VERSION "canboat-NMEA2000-curated"

NS_ :

BS_:

BU_: Vector__XXX
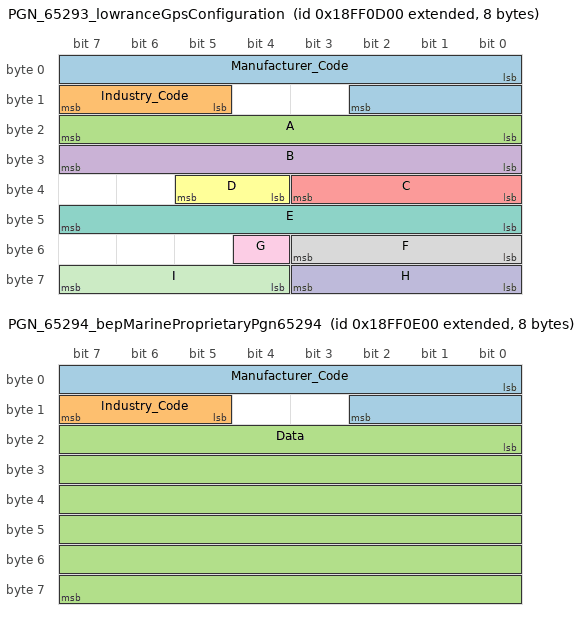
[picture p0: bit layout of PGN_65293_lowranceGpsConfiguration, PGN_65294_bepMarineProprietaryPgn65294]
BO_ 2566851840 PGN_65293_lowranceGpsConfiguration: 8 Vector__XXX
 SG_ Manufacturer_Code : 0|11@1+ (1.0,0) [0|2047] "" Vector__XXX
 SG_ Industry_Code : 13|3@1+ (1.0,0) [0|7] "" Vector__XXX
 SG_ A : 16|8@1+ (1.0,0) [0|255] "" Vector__XXX
 SG_ B : 24|8@1+ (1.0,0) [0|255] "" Vector__XXX
 SG_ C : 32|4@1+ (1.0,0) [0|15] "" Vector__XXX
 SG_ D : 36|2@1+ (1.0,0) [0|3] "" Vector__XXX
 SG_ E : 40|8@1+ (1.0,0) [0|255] "" Vector__XXX
 SG_ F : 48|4@1+ (1.0,0) [0|15] "" Vector__XXX
 SG_ G : 52|1@1+ (1.0,0) [0|1] "" Vector__XXX
 SG_ H : 56|4@1+ (1.0,0) [0|15] "" Vector__XXX
 SG_ I : 60|4@1+ (1.0,0) [0|15] "" Vector__XXX

BO_ 2566851840 PGN_65293_simnetLgc2000Configuration: 8 Vector__XXX
 SG_ Manufacturer_Code : 0|11@1+ (1.0,0) [0|2047] "" Vector__XXX
 SG_ Industry_Code : 13|3@1+ (1.0,0) [0|7] "" Vector__XXX

BO_ 2566852096 PGN_65294_bepMarineProprietaryPgn65294: 8 Vector__XXX
 SG_ Manufacturer_Code : 0|11@1+ (1.0,0) [0|2047] "" Vector__XXX
 SG_ Industry_Code : 13|3@1+ (1.0,0) [0|7] "" Vector__XXX
 SG_ Data : 16|48@1+ (1.0,0) [0|281474976710655] "" Vector__XXX

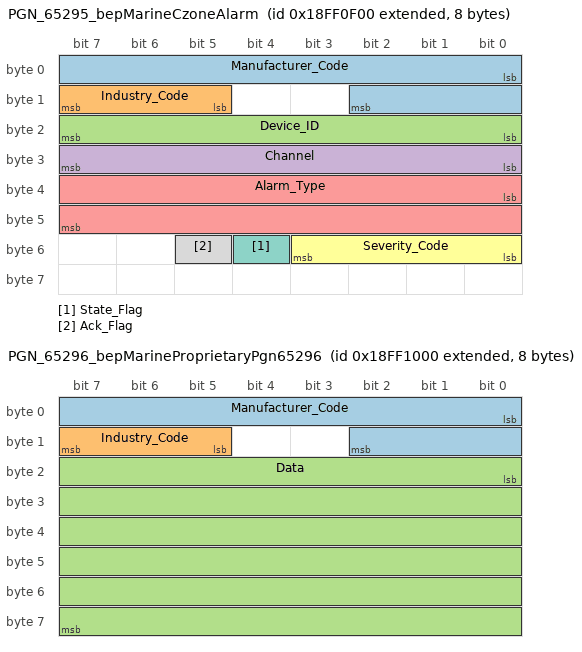
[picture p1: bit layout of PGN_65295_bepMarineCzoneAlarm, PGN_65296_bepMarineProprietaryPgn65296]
BO_ 2566852352 PGN_65295_bepMarineCzoneAlarm: 8 Vector__XXX
 SG_ Manufacturer_Code : 0|11@1+ (1.0,0) [0|2047] "" Vector__XXX
 SG_ Industry_Code : 13|3@1+ (1.0,0) [0|7] "" Vector__XXX
 SG_ Device_ID : 16|8@1+ (1.0,0) [0|255] "" Vector__XXX
 SG_ Channel : 24|8@1+ (1.0,0) [0|255] "" Vector__XXX
 SG_ Alarm_Type : 32|16@1+ (1.0,0) [0|65535] "" Vector__XXX
 SG_ Severity_Code : 48|4@1+ (1.0,0) [0|15] "" Vector__XXX
 SG_ State_Flag : 52|1@1+ (1.0,0) [0|1] "" Vector__XXX
 SG_ Ack_Flag : 53|1@1+ (1.0,0) [0|1] "" Vector__XXX

BO_ 2566852608 PGN_65296_bepMarineProprietaryPgn65296: 8 Vector__XXX
 SG_ Manufacturer_Code : 0|11@1+ (1.0,0) [0|2047] "" Vector__XXX
 SG_ Industry_Code : 13|3@1+ (1.0,0) [0|7] "" Vector__XXX
 SG_ Data : 16|48@1+ (1.0,0) [0|281474976710655] "" Vector__XXX

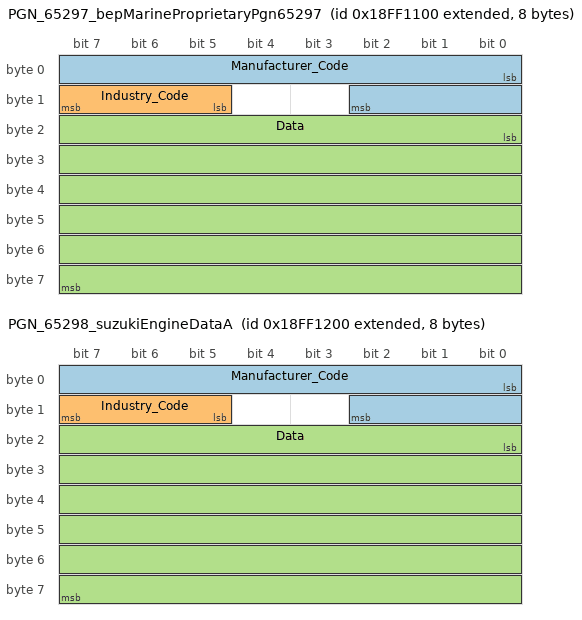
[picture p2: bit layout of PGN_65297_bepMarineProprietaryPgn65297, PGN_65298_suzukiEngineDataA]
BO_ 2566852864 PGN_65297_bepMarineProprietaryPgn65297: 8 Vector__XXX
 SG_ Manufacturer_Code : 0|11@1+ (1.0,0) [0|2047] "" Vector__XXX
 SG_ Industry_Code : 13|3@1+ (1.0,0) [0|7] "" Vector__XXX
 SG_ Data : 16|48@1+ (1.0,0) [0|281474976710655] "" Vector__XXX

BO_ 2566853120 PGN_65298_suzukiEngineDataA: 8 Vector__XXX
 SG_ Manufacturer_Code : 0|11@1+ (1.0,0) [0|2047] "" Vector__XXX
 SG_ Industry_Code : 13|3@1+ (1.0,0) [0|7] "" Vector__XXX
 SG_ Data : 16|48@1+ (1.0,0) [0|281474976710655] "" Vector__XXX

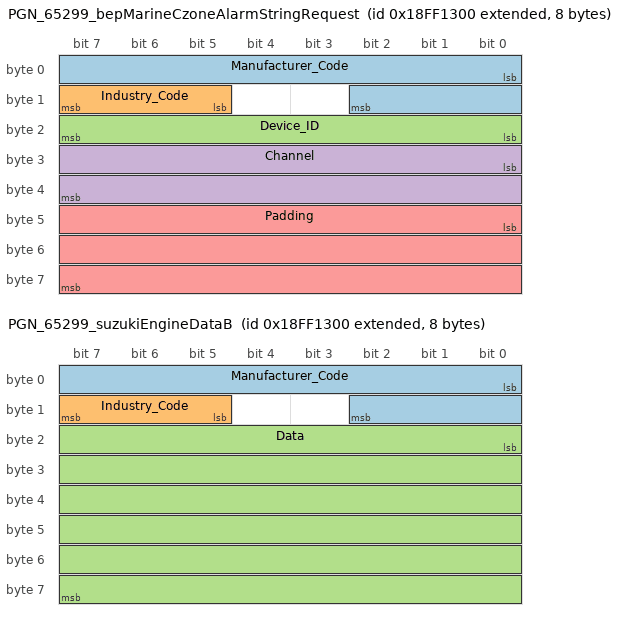
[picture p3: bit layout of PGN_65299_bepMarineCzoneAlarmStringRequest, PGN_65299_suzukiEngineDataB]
BO_ 2566853376 PGN_65299_bepMarineCzoneAlarmStringRequest: 8 Vector__XXX
 SG_ Manufacturer_Code : 0|11@1+ (1.0,0) [0|2047] "" Vector__XXX
 SG_ Industry_Code : 13|3@1+ (1.0,0) [0|7] "" Vector__XXX
 SG_ Device_ID : 16|8@1+ (1.0,0) [0|255] "" Vector__XXX
 SG_ Channel : 24|16@1+ (1.0,0) [0|65535] "" Vector__XXX
 SG_ Padding : 40|24@1+ (1.0,0) [0|16777215] "" Vector__XXX

BO_ 2566853376 PGN_65299_suzukiEngineDataB: 8 Vector__XXX
 SG_ Manufacturer_Code : 0|11@1+ (1.0,0) [0|2047] "" Vector__XXX
 SG_ Industry_Code : 13|3@1+ (1.0,0) [0|7] "" Vector__XXX
 SG_ Data : 16|48@1+ (1.0,0) [0|281474976710655] "" Vector__XXX

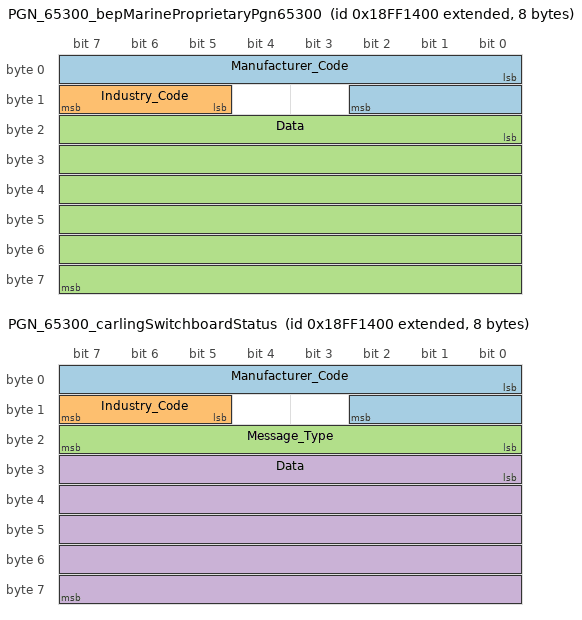
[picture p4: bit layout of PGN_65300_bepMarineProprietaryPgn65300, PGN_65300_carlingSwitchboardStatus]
BO_ 2566853632 PGN_65300_bepMarineProprietaryPgn65300: 8 Vector__XXX
 SG_ Manufacturer_Code : 0|11@1+ (1.0,0) [0|2047] "" Vector__XXX
 SG_ Industry_Code : 13|3@1+ (1.0,0) [0|7] "" Vector__XXX
 SG_ Data : 16|48@1+ (1.0,0) [0|281474976710655] "" Vector__XXX

BO_ 2566853632 PGN_65300_carlingSwitchboardStatus: 8 Vector__XXX
 SG_ Manufacturer_Code : 0|11@1+ (1.0,0) [0|2047] "" Vector__XXX
 SG_ Industry_Code : 13|3@1+ (1.0,0) [0|7] "" Vector__XXX
 SG_ Message_Type : 16|8@1+ (1.0,0) [0|255] "" Vector__XXX
 SG_ Data : 24|40@1+ (1.0,0) [0|1099511627775] "" Vector__XXX

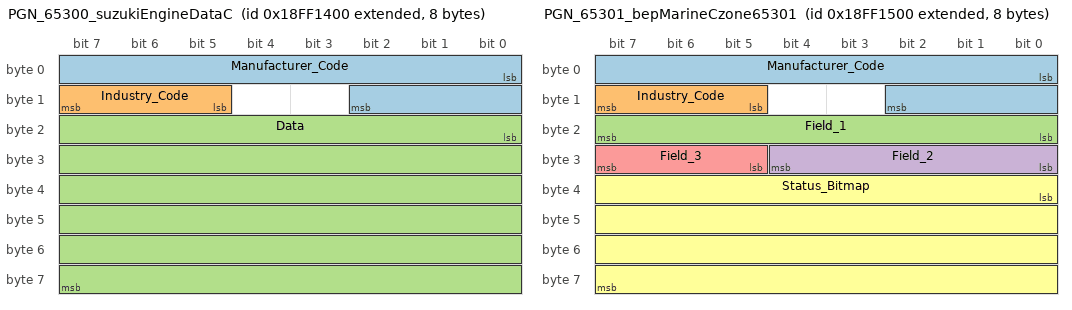
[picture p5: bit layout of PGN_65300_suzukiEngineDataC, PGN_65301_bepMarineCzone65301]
BO_ 2566853632 PGN_65300_suzukiEngineDataC: 8 Vector__XXX
 SG_ Manufacturer_Code : 0|11@1+ (1.0,0) [0|2047] "" Vector__XXX
 SG_ Industry_Code : 13|3@1+ (1.0,0) [0|7] "" Vector__XXX
 SG_ Data : 16|48@1+ (1.0,0) [0|281474976710655] "" Vector__XXX

BO_ 2566853888 PGN_65301_bepMarineCzone65301: 8 Vector__XXX
 SG_ Manufacturer_Code : 0|11@1+ (1.0,0) [0|2047] "" Vector__XXX
 SG_ Industry_Code : 13|3@1+ (1.0,0) [0|7] "" Vector__XXX
 SG_ Field_1 : 16|8@1+ (1.0,0) [0|255] "" Vector__XXX
 SG_ Field_2 : 24|5@1+ (1.0,0) [0|31] "" Vector__XXX
 SG_ Field_3 : 29|3@1+ (1.0,0) [0|7] "" Vector__XXX
 SG_ Status_Bitmap : 32|32@1+ (1.0,0) [0|4294967295] "" Vector__XXX

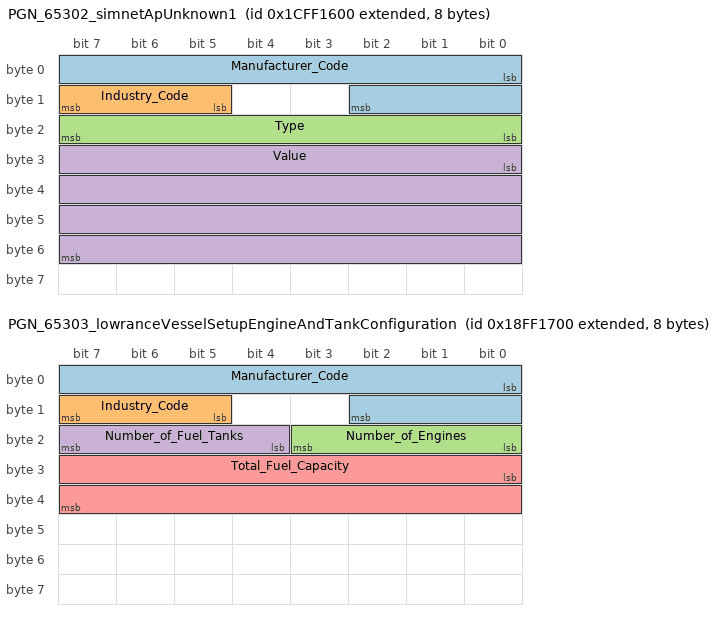
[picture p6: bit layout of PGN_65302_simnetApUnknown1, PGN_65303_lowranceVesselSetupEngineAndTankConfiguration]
BO_ 2633963008 PGN_65302_simnetApUnknown1: 8 Vector__XXX
 SG_ Manufacturer_Code : 0|11@1+ (1.0,0) [0|2047] "" Vector__XXX
 SG_ Industry_Code : 13|3@1+ (1.0,0) [0|7] "" Vector__XXX
 SG_ Type : 16|8@1+ (1.0,0) [0|255] "" Vector__XXX
 SG_ Value : 24|32@1+ (1.0,0) [0|4294967295] "" Vector__XXX

BO_ 2566854400 PGN_65303_lowranceVesselSetupEngineAndTankConfiguration: 8 Vector__XXX
 SG_ Manufacturer_Code : 0|11@1+ (1.0,0) [0|2047] "" Vector__XXX
 SG_ Industry_Code : 13|3@1+ (1.0,0) [0|7] "" Vector__XXX
 SG_ Number_of_Engines : 16|4@1+ (1.0,0) [0|15] "" Vector__XXX
 SG_ Number_of_Fuel_Tanks : 20|4@1+ (1.0,0) [0|15] "" Vector__XXX
 SG_ Total_Fuel_Capacity : 24|16@1+ (0.1,0) [0.0|6553.5] "" Vector__XXX

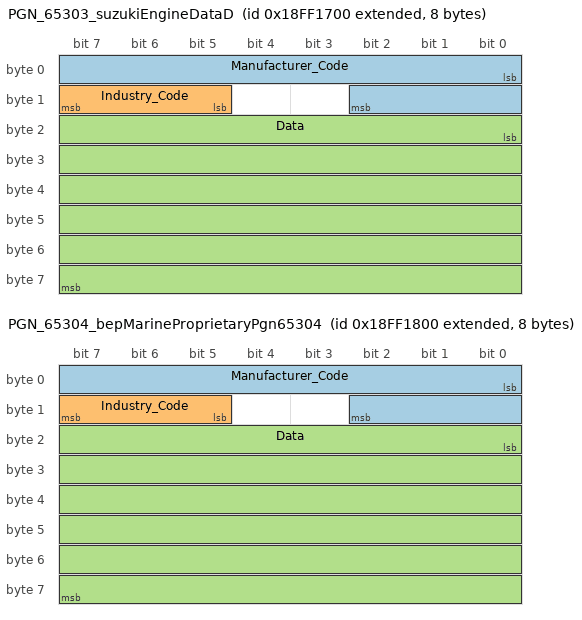
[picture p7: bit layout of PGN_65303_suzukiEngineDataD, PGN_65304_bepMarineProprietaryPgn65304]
BO_ 2566854400 PGN_65303_suzukiEngineDataD: 8 Vector__XXX
 SG_ Manufacturer_Code : 0|11@1+ (1.0,0) [0|2047] "" Vector__XXX
 SG_ Industry_Code : 13|3@1+ (1.0,0) [0|7] "" Vector__XXX
 SG_ Data : 16|48@1+ (1.0,0) [0|281474976710655] "" Vector__XXX

BO_ 2566854656 PGN_65304_bepMarineProprietaryPgn65304: 8 Vector__XXX
 SG_ Manufacturer_Code : 0|11@1+ (1.0,0) [0|2047] "" Vector__XXX
 SG_ Industry_Code : 13|3@1+ (1.0,0) [0|7] "" Vector__XXX
 SG_ Data : 16|48@1+ (1.0,0) [0|281474976710655] "" Vector__XXX

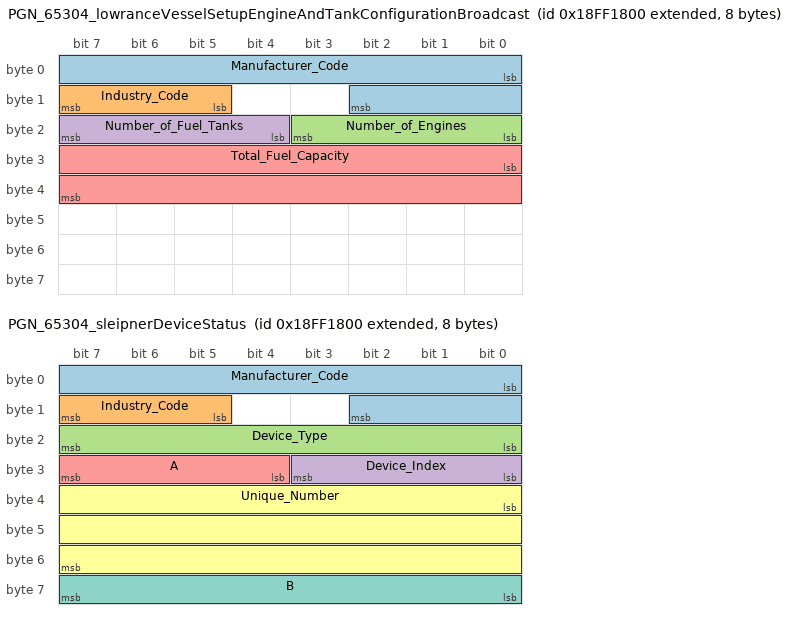
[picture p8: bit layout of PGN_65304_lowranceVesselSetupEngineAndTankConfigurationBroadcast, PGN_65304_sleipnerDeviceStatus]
BO_ 2566854656 PGN_65304_lowranceVesselSetupEngineAndTankConfigurationBroadcast: 8 Vector__XXX
 SG_ Manufacturer_Code : 0|11@1+ (1.0,0) [0|2047] "" Vector__XXX
 SG_ Industry_Code : 13|3@1+ (1.0,0) [0|7] "" Vector__XXX
 SG_ Number_of_Engines : 16|4@1+ (1.0,0) [0|15] "" Vector__XXX
 SG_ Number_of_Fuel_Tanks : 20|4@1+ (1.0,0) [0|15] "" Vector__XXX
 SG_ Total_Fuel_Capacity : 24|16@1+ (0.1,0) [0.0|6553.5] "" Vector__XXX

BO_ 2566854656 PGN_65304_sleipnerDeviceStatus: 8 Vector__XXX
 SG_ Manufacturer_Code : 0|11@1+ (1.0,0) [0|2047] "" Vector__XXX
 SG_ Industry_Code : 13|3@1+ (1.0,0) [0|7] "" Vector__XXX
 SG_ Device_Type : 16|8@1+ (1.0,0) [0|255] "" Vector__XXX
 SG_ Device_Index : 24|4@1+ (1.0,0) [0|15] "" Vector__XXX
 SG_ A : 28|4@1+ (1.0,0) [0|15] "" Vector__XXX
 SG_ Unique_Number : 32|24@1+ (1.0,0) [0|16777215] "" Vector__XXX
 SG_ B : 56|8@1+ (1.0,0) [0|255] "" Vector__XXX

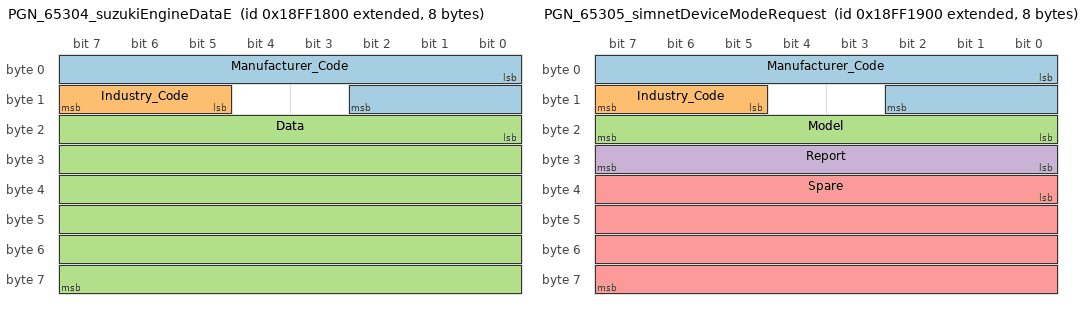
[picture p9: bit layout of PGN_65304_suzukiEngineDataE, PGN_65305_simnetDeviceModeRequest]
BO_ 2566854656 PGN_65304_suzukiEngineDataE: 8 Vector__XXX
 SG_ Manufacturer_Code : 0|11@1+ (1.0,0) [0|2047] "" Vector__XXX
 SG_ Industry_Code : 13|3@1+ (1.0,0) [0|7] "" Vector__XXX
 SG_ Data : 16|48@1+ (1.0,0) [0|281474976710655] "" Vector__XXX

BO_ 2566854912 PGN_65305_simnetDeviceModeRequest: 8 Vector__XXX
 SG_ Manufacturer_Code : 0|11@1+ (1.0,0) [0|2047] "" Vector__XXX
 SG_ Industry_Code : 13|3@1+ (1.0,0) [0|7] "" Vector__XXX
 SG_ Model : 16|8@1+ (1.0,0) [0|255] "" Vector__XXX
 SG_ Report : 24|8@1+ (1.0,0) [0|255] "" Vector__XXX
 SG_ Spare : 32|32@1+ (1.0,0) [0|4294967295] "" Vector__XXX

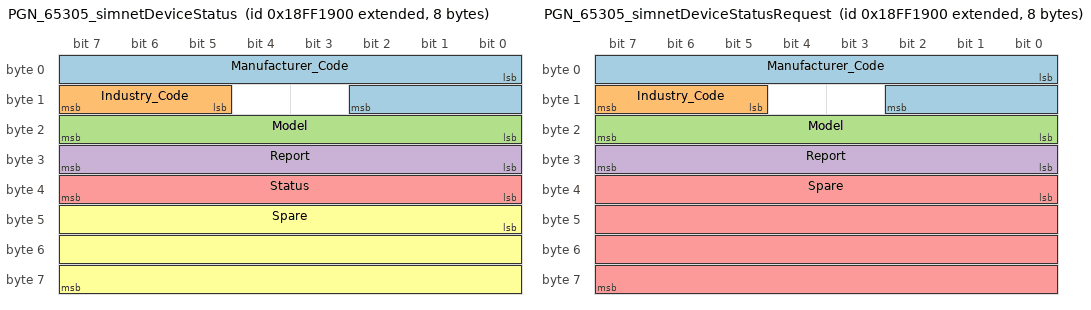
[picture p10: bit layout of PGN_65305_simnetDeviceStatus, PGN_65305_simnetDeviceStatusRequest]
BO_ 2566854912 PGN_65305_simnetDeviceStatus: 8 Vector__XXX
 SG_ Manufacturer_Code : 0|11@1+ (1.0,0) [0|2047] "" Vector__XXX
 SG_ Industry_Code : 13|3@1+ (1.0,0) [0|7] "" Vector__XXX
 SG_ Model : 16|8@1+ (1.0,0) [0|255] "" Vector__XXX
 SG_ Report : 24|8@1+ (1.0,0) [0|255] "" Vector__XXX
 SG_ Status : 32|8@1+ (1.0,0) [0|255] "" Vector__XXX
 SG_ Spare : 40|24@1+ (1.0,0) [0|16777215] "" Vector__XXX

BO_ 2566854912 PGN_65305_simnetDeviceStatusRequest: 8 Vector__XXX
 SG_ Manufacturer_Code : 0|11@1+ (1.0,0) [0|2047] "" Vector__XXX
 SG_ Industry_Code : 13|3@1+ (1.0,0) [0|7] "" Vector__XXX
 SG_ Model : 16|8@1+ (1.0,0) [0|255] "" Vector__XXX
 SG_ Report : 24|8@1+ (1.0,0) [0|255] "" Vector__XXX
 SG_ Spare : 32|32@1+ (1.0,0) [0|4294967295] "" Vector__XXX

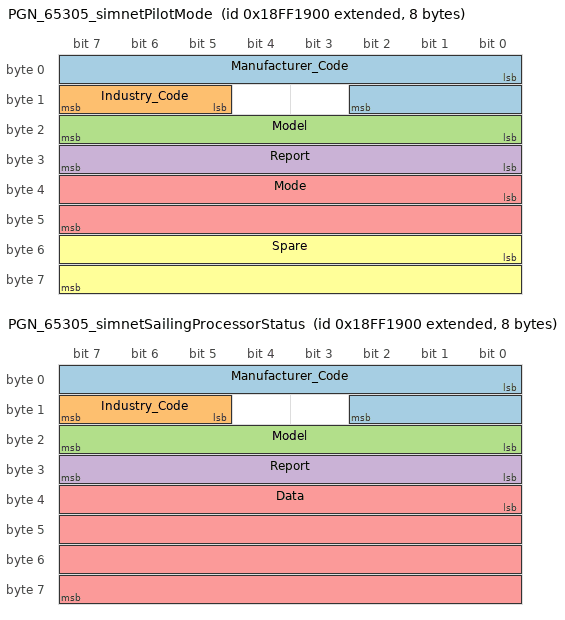
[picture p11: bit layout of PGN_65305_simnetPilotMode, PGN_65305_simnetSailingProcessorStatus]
BO_ 2566854912 PGN_65305_simnetPilotMode: 8 Vector__XXX
 SG_ Manufacturer_Code : 0|11@1+ (1.0,0) [0|2047] "" Vector__XXX
 SG_ Industry_Code : 13|3@1+ (1.0,0) [0|7] "" Vector__XXX
 SG_ Model : 16|8@1+ (1.0,0) [0|255] "" Vector__XXX
 SG_ Report : 24|8@1+ (1.0,0) [0|255] "" Vector__XXX
 SG_ Mode : 32|16@1+ (1.0,0) [0|65535] "" Vector__XXX
 SG_ Spare : 48|16@1+ (1.0,0) [0|65535] "" Vector__XXX

BO_ 2566854912 PGN_65305_simnetSailingProcessorStatus: 8 Vector__XXX
 SG_ Manufacturer_Code : 0|11@1+ (1.0,0) [0|2047] "" Vector__XXX
 SG_ Industry_Code : 13|3@1+ (1.0,0) [0|7] "" Vector__XXX
 SG_ Model : 16|8@1+ (1.0,0) [0|255] "" Vector__XXX
 SG_ Report : 24|8@1+ (1.0,0) [0|255] "" Vector__XXX
 SG_ Data : 32|32@1+ (1.0,0) [0|4294967295] "" Vector__XXX

CM_ BO_ 2566851840 "NMEA2000: PGN 65293 - Lowrance: GPS Configuration (type: Single)";
CM_ BO_ 2566851840 "NMEA2000: PGN 65293 - Simnet: LGC-2000 Configuration (type: Single)";
CM_ BO_ 2566852096 "NMEA2000: PGN 65294 - BEP Marine: Proprietary PGN 65294 (type: Single)";
CM_ BO_ 2566852352 "NMEA2000: PGN 65295 - BEP Marine: CZone Alarm (type: Single)";
CM_ BO_ 2566852608 "NMEA2000: PGN 65296 - BEP Marine: Proprietary PGN 65296 (type: Single)";
CM_ BO_ 2566852864 "NMEA2000: PGN 65297 - BEP Marine: Proprietary PGN 65297 (type: Single)";
CM_ BO_ 2566853120 "NMEA2000: PGN 65298 - Suzuki: Engine Data A (type: Single)";
CM_ BO_ 2566853376 "NMEA2000: PGN 65299 - BEP Marine: CZone Alarm String Request (type: Single)";
CM_ BO_ 2566853376 "NMEA2000: PGN 65299 - Suzuki: Engine Data B (type: Single)";
CM_ BO_ 2566853632 "NMEA2000: PGN 65300 - BEP Marine: Proprietary PGN 65300 (type: Single)";
CM_ BO_ 2566853632 "NMEA2000: PGN 65300 - Carling: Switchboard Status (type: Single)";
CM_ BO_ 2566853632 "NMEA2000: PGN 65300 - Suzuki: Engine Data C (type: Single)";
CM_ BO_ 2566853888 "NMEA2000: PGN 65301 - BEP Marine: CZone 65301 (type: Single)";
CM_ BO_ 2633963008 "NMEA2000: PGN 65302 - Simnet: AP Unknown 1 (type: Single)";
CM_ BO_ 2566854400 "NMEA2000: PGN 65303 - Lowrance: Vessel Setup - Engine and Tank Configuration (type: Single)";
CM_ BO_ 2566854400 "NMEA2000: PGN 65303 - Suzuki: Engine Data D (type: Single)";
CM_ BO_ 2566854656 "NMEA2000: PGN 65304 - BEP Marine: Proprietary PGN 65304 (type: Single)";
CM_ BO_ 2566854656 "NMEA2000: PGN 65304 - Lowrance: Vessel Setup - Engine and Tank Configuration Broadcast (type: Single)";
CM_ BO_ 2566854656 "NMEA2000: PGN 65304 - Sleipner: Device Status (type: Single)";
CM_ BO_ 2566854656 "NMEA2000: PGN 65304 - Suzuki: Engine Data E (type: Single)";
CM_ BO_ 2566854912 "NMEA2000: PGN 65305 - Simnet: Device Mode Request (type: Single)";
CM_ BO_ 2566854912 "NMEA2000: PGN 65305 - Simnet: Device Status (type: Single)";
CM_ BO_ 2566854912 "NMEA2000: PGN 65305 - Simnet: Device Status Request (type: Single)";
CM_ BO_ 2566854912 "NMEA2000: PGN 65305 - Simnet: Pilot Mode (type: Single)";
CM_ BO_ 2566854912 "NMEA2000: PGN 65305 - Simnet: Sailing Processor Status (type: Single)";
CM_ SG_ 2566851840 Manufacturer_Code "Lowrance; canboat type: LOOKUP";
CM_ SG_ 2566851840 Industry_Code "Marine Industry; canboat type: LOOKUP";
CM_ SG_ 2566851840 A "canboat type: UINT8";
CM_ SG_ 2566851840 B "canboat type: UINT8";
CM_ SG_ 2566851840 C "canboat type: UNSIGNED_INTEGER";
CM_ SG_ 2566851840 D "canboat type: UNSIGNED_INTEGER";
CM_ SG_ 2566851840 E "canboat type: UINT8";
CM_ SG_ 2566851840 F "canboat type: UNSIGNED_INTEGER";
CM_ SG_ 2566851840 G "canboat type: UNSIGNED_INTEGER";
CM_ SG_ 2566851840 H "canboat type: UNSIGNED_INTEGER";
CM_ SG_ 2566851840 I "canboat type: UNSIGNED_INTEGER";
CM_ SG_ 2566851840 Manufacturer_Code "Simrad; canboat type: LOOKUP";
CM_ SG_ 2566851840 Industry_Code "Marine Industry; canboat type: LOOKUP";
CM_ SG_ 2566852096 Manufacturer_Code "BEP Marine; canboat type: LOOKUP";
CM_ SG_ 2566852096 Industry_Code "Marine Industry; canboat type: LOOKUP";
CM_ SG_ 2566852096 Data "canboat type: BINARY";
CM_ SG_ 2566852352 Manufacturer_Code "BEP Marine; canboat type: LOOKUP";
CM_ SG_ 2566852352 Industry_Code "Marine Industry; canboat type: LOOKUP";
CM_ SG_ 2566852352 Device_ID "Device / source module id; canboat type: UINT8";
CM_ SG_ 2566852352 Channel "Channel / alarm id low byte; canboat type: UINT8";
CM_ SG_ 2566852352 Alarm_Type "canboat type: LOOKUP";
CM_ SG_ 2566852352 Severity_Code "Raw CZone severity code; values 1..5 map to internal severities 4..0; canboat type: UNSIGNED_INTEGER";
CM_ SG_ 2566852352 State_Flag "State bit used by CZone to distinguish active vs cleared/acknowledged state; canboat type: UNSIGNED_INTEGER";
CM_ SG_ 2566852352 Ack_Flag "Packed and transmitted by CZone, but receive-side action is not confirmed; canboat type: UNSIGNED_INTEGER";
CM_ SG_ 2566852608 Manufacturer_Code "BEP Marine; canboat type: LOOKUP";
CM_ SG_ 2566852608 Industry_Code "Marine Industry; canboat type: LOOKUP";
CM_ SG_ 2566852608 Data "canboat type: BINARY";
CM_ SG_ 2566852864 Manufacturer_Code "BEP Marine; canboat type: LOOKUP";
CM_ SG_ 2566852864 Industry_Code "Marine Industry; canboat type: LOOKUP";
CM_ SG_ 2566852864 Data "canboat type: BINARY";
CM_ SG_ 2566853120 Manufacturer_Code "Suzuki Motor Corporation; canboat type: LOOKUP";
CM_ SG_ 2566853120 Industry_Code "Marine Industry; canboat type: LOOKUP";
CM_ SG_ 2566853120 Data "canboat type: BINARY";
CM_ SG_ 2566853376 Manufacturer_Code "BEP Marine; canboat type: LOOKUP";
CM_ SG_ 2566853376 Industry_Code "Marine Industry; canboat type: LOOKUP";
CM_ SG_ 2566853376 Device_ID "Device / destination module id associated with the alarm; canboat type: UINT8";
CM_ SG_ 2566853376 Channel "Channel / alarm id; canboat type: UINT16";
CM_ SG_ 2566853376 Padding "Set to FF FF FF; canboat type: BINARY";
CM_ SG_ 2566853376 Manufacturer_Code "Suzuki Motor Corporation; canboat type: LOOKUP";
CM_ SG_ 2566853376 Industry_Code "Marine Industry; canboat type: LOOKUP";
CM_ SG_ 2566853376 Data "canboat type: BINARY";
CM_ SG_ 2566853632 Manufacturer_Code "BEP Marine; canboat type: LOOKUP";
CM_ SG_ 2566853632 Industry_Code "Marine Industry; canboat type: LOOKUP";
CM_ SG_ 2566853632 Data "canboat type: BINARY";
CM_ SG_ 2566853632 Manufacturer_Code "Carling Technologies Inc. (Moritz Aerospace); canboat type: LOOKUP";
CM_ SG_ 2566853632 Industry_Code "Marine Industry; canboat type: LOOKUP";
CM_ SG_ 2566853632 Message_Type "canboat type: UINT8";
CM_ SG_ 2566853632 Data "Payload varies by Message Type.; canboat type: BINARY";
CM_ SG_ 2566853632 Manufacturer_Code "Suzuki Motor Corporation; canboat type: LOOKUP";
CM_ SG_ 2566853632 Industry_Code "Marine Industry; canboat type: LOOKUP";
CM_ SG_ 2566853632 Data "canboat type: BINARY";
CM_ SG_ 2566853888 Manufacturer_Code "BEP Marine; canboat type: LOOKUP";
CM_ SG_ 2566853888 Industry_Code "Marine Industry; canboat type: LOOKUP";
CM_ SG_ 2566853888 Field_1 "Pass-through byte; purpose unverified; canboat type: UINT8";
CM_ SG_ 2566853888 Field_2 "5-bit field; purpose unverified; canboat type: UNSIGNED_INTEGER";
CM_ SG_ 2566853888 Field_3 "3-bit field; purpose unverified; canboat type: UNSIGNED_INTEGER";
CM_ SG_ 2566853888 Status_Bitmap "32-bit bitmap, LSB-first; bit n set => item n active. Per-bit meaning unverified.; canboat type: BINARY";
CM_ SG_ 2633963008 Manufacturer_Code "Simrad; canboat type: LOOKUP";
CM_ SG_ 2633963008 Industry_Code "Marine Industry; canboat type: LOOKUP";
CM_ SG_ 2633963008 Type "Always 0x0A; canboat type: UINT8";
CM_ SG_ 2633963008 Value "canboat type: UINT32";
CM_ SG_ 2566854400 Manufacturer_Code "Lowrance; canboat type: LOOKUP";
CM_ SG_ 2566854400 Industry_Code "Marine Industry; canboat type: LOOKUP";
CM_ SG_ 2566854400 Number_of_Engines "Engine count configured on the display's Vessel Setup page; canboat type: UNSIGNED_INTEGER";
CM_ SG_ 2566854400 Number_of_Fuel_Tanks "Fuel-tank count configured on the display's Vessel Setup page; canboat type: UNSIGNED_INTEGER";
CM_ SG_ 2566854400 Total_Fuel_Capacity "canboat type: VOLUME_UFIX16_DL";
CM_ SG_ 2566854400 Manufacturer_Code "Suzuki Motor Corporation; canboat type: LOOKUP";
CM_ SG_ 2566854400 Industry_Code "Marine Industry; canboat type: LOOKUP";
CM_ SG_ 2566854400 Data "canboat type: BINARY";
CM_ SG_ 2566854656 Manufacturer_Code "BEP Marine; canboat type: LOOKUP";
CM_ SG_ 2566854656 Industry_Code "Marine Industry; canboat type: LOOKUP";
CM_ SG_ 2566854656 Data "canboat type: BINARY";
CM_ SG_ 2566854656 Manufacturer_Code "Lowrance; canboat type: LOOKUP";
CM_ SG_ 2566854656 Industry_Code "Marine Industry; canboat type: LOOKUP";
CM_ SG_ 2566854656 Number_of_Engines "Engine count configured on the display's Vessel Setup page; canboat type: UNSIGNED_INTEGER";
CM_ SG_ 2566854656 Number_of_Fuel_Tanks "Fuel-tank count configured on the display's Vessel Setup page; canboat type: UNSIGNED_INTEGER";
CM_ SG_ 2566854656 Total_Fuel_Capacity "canboat type: VOLUME_UFIX16_DL";
CM_ SG_ 2566854656 Manufacturer_Code "Sleipner Motor; canboat type: LOOKUP";
CM_ SG_ 2566854656 Industry_Code "Marine Industry; canboat type: LOOKUP";
CM_ SG_ 2566854656 Device_Type "Constant per device; canboat type: UINT8";
CM_ SG_ 2566854656 Device_Index "Stable per-device index; canboat type: UNSIGNED_INTEGER";
CM_ SG_ 2566854656 A "Varies with system state; the value set is wider than the thruster state reported in PGN 130827 and is not yet understood; canboat type: UNSIGNED_INTEGER";
CM_ SG_ 2566854656 Unique_Number "ISO Identity Number, as claimed by this device in PGN 60928; canboat type: UNSIGNED_INTEGER";
CM_ SG_ 2566854656 B "canboat type: UINT8";
CM_ SG_ 2566854656 Manufacturer_Code "Suzuki Motor Corporation; canboat type: LOOKUP";
CM_ SG_ 2566854656 Industry_Code "Marine Industry; canboat type: LOOKUP";
CM_ SG_ 2566854656 Data "canboat type: BINARY";
CM_ SG_ 2566854912 Manufacturer_Code "Simrad; canboat type: LOOKUP";
CM_ SG_ 2566854912 Industry_Code "Marine Industry; canboat type: LOOKUP";
CM_ SG_ 2566854912 Model "canboat type: LOOKUP";
CM_ SG_ 2566854912 Report "Send Mode; canboat type: LOOKUP";
CM_ SG_ 2566854912 Spare "canboat type: SPARE";
CM_ SG_ 2566854912 Manufacturer_Code "Simrad; canboat type: LOOKUP";
CM_ SG_ 2566854912 Industry_Code "Marine Industry; canboat type: LOOKUP";
CM_ SG_ 2566854912 Model "canboat type: LOOKUP";
CM_ SG_ 2566854912 Report "Status; canboat type: LOOKUP";
CM_ SG_ 2566854912 Status "canboat type: LOOKUP";
CM_ SG_ 2566854912 Spare "canboat type: SPARE";
CM_ SG_ 2566854912 Manufacturer_Code "Simrad; canboat type: LOOKUP";
CM_ SG_ 2566854912 Industry_Code "Marine Industry; canboat type: LOOKUP";
CM_ SG_ 2566854912 Model "canboat type: LOOKUP";
CM_ SG_ 2566854912 Report "Send Status; canboat type: LOOKUP";
CM_ SG_ 2566854912 Spare "canboat type: SPARE";
CM_ SG_ 2566854912 Manufacturer_Code "Simrad; canboat type: LOOKUP";
CM_ SG_ 2566854912 Industry_Code "Marine Industry; canboat type: LOOKUP";
CM_ SG_ 2566854912 Model "canboat type: LOOKUP";
CM_ SG_ 2566854912 Report "Mode; canboat type: LOOKUP";
CM_ SG_ 2566854912 Mode "canboat type: BITLOOKUP";
CM_ SG_ 2566854912 Spare "canboat type: SPARE";
CM_ SG_ 2566854912 Manufacturer_Code "Simrad; canboat type: LOOKUP";
CM_ SG_ 2566854912 Industry_Code "Marine Industry; canboat type: LOOKUP";
CM_ SG_ 2566854912 Model "canboat type: LOOKUP";
CM_ SG_ 2566854912 Report "Sailing Processor Status; canboat type: LOOKUP";
CM_ SG_ 2566854912 Data "canboat type: BINARY";
VAL_ 2566851840 Manufacturer_Code 69 "ARKS Enterprises" 78 "FW Murphy/Enovation Controls" 80 "Twin Disc" 85 "Kohler Power Systems" 88 "Hemisphere GPS" 135 "Airmar" 137 "Maretron" 140 "Lowrance" 144 "Mercury Marine" 147 "Nautibus Electronic" 148 "Blue Water Data" 154 "Westerbeke" 157 "ISSPRO" 161 "Offshore Systems (UK)" 163 "Evinrude/BRP" 165 "CPAC Systems" 168 "Xantrex Technology" 169 "Marlin Technologies" 172 "Yanmar Marine" 174 "Volvo Penta" 176 "Carling Technologies Inc. (Moritz Aerospace)" 185 "Beede Instruments" 192 "Floscan Instrument" 193 "Nobeltec" 198 "Mystic Valley Communications" 199 "Actia" 201 "Disenos Y Technologia" 211 "Digital Switching Systems" 215 "Xintex/Atena" 224 "EMMI NETWORK" 228 "ZF" 229 "Garmin" 233 "Yacht Monitoring Solutions" 235 "Sailormade Marine Telemetry/Tetra Technology" 243 "Eride" 257 "Honda Motor" 272 "Groco" 273 "Actisense" 274 "Amphenol LTW Technology" 275 "Navico" 283 "Hamilton Jet" 285 "Sea Recovery" 286 "Coelmo SRL Italy" 295 "BEP Marine" 304 "Empir Bus" 305 "NovAtel" 306 "Sleipner Motor" 307 "MBW Technologies" 315 "ICOM" 328 "Qwerty" 329 "Dief" 341 "Boening Automationstechnologie" 345 "Korean Maritime University" 351 "Thrane and Thrane" 355 "Mastervolt" 356 "Fischer Panda Generators" 358 "Victron Energy" 370 "Rolls Royce Marine" 373 "Electronic Design" 374 "Northern Lights" 378 "Glendinning" 381 "B & G" 384 "Rose Point Navigation Systems" 385 "Johnson Outdoors Marine Electronics Inc Geonav" 394 "Capi 2" 396 "Beyond Measure" 400 "Livorsi Marine" 404 "ComNav" 409 "Chetco" 419 "Fusion Electronics" 421 "Standard Horizon" 422 "True Heading" 426 "Egersund Marine Electronics" 427 "em-trak Marine Electronics" 431 "Tohatsu Co, JP" 437 "Digital Yacht" 438 "Comar Systems Limited" 440 "Cummins" 443 "VDO (aka Continental-Corporation)" 451 "Parker Hannifin aka Village Marine Tech" 459 "Alltek Marine Electronics" 460 "SAN GIORGIO S.E.I.N" 466 "Veethree Electronics & Marine" 470 "SI-TEX Marine Electronics" 471 "Sea Cross Marine" 475 "GME aka Standard Communications" 476 "Humminbird Marine Electronics" 478 "Ocean Sat" 481 "Chetco Digital Instruments" 493 "Watcheye" 499 "Lcj Capteurs" 502 "Attwood Marine" 503 "Naviop S.R.L." 504 "Vesper Marine" 510 "Marinesoft" 513 "Simarine" 517 "NoLand Engineering" 518 "Transas USA" 529 "National Instruments Korea" 530 "National Marine Electronics Association" 532 "Onwa Marine" 540 "Webasto" 571 "Marinecraft (South Korea)" 573 "McMurdo Group aka Orolia" 578 "Advansea" 579 "KVH" 580 "San Jose Technology" 583 "Yacht Control" 586 "Suzuki Motor" 591 "US Coast Guard" 595 "Ship Module aka Customware" 600 "Aquatic AV" 605 "Aventics" 606 "Intellian" 612 "SamwonIT" 614 "Arlt Tecnologies" 637 "Bavaria Yachts" 641 "Diverse Yacht Services" 644 "Wema U.S.A dba KUS" 658 "Shenzhen Jiuzhou Himunication" 688 "Rockford" 699 "Harman International" 704 "JL Audio" 708 "Lars Thrane" 715 "Autonnic" 717 "Yacht Devices" 734 "REAP Systems" 735 "AEM Performance Electronics" 739 "LxNav" 741 "Littelfuse, Inc (formerly Carling Technologies)" 743 "DaeMyung" 744 "Woosung" 748 "ISOTTA IFRA srl" 773 "Clarion US" 776 "HMI Systems" 777 "Ocean Signal" 778 "Seakeeper" 781 "Poly Planar" 785 "Fischer Panda DE" 795 "Broyda Industries" 796 "Canadian Automotive" 797 "Tides Marine" 798 "Lumishore" 799 "Still Water Designs and Audio" 802 "BJ Technologies (Beneteau)" 803 "Gill Sensors" 811 "Blue Water Desalination" 815 "FLIR" 824 "Undheim Systems" 826 "Lewmar" 838 "TeamSurv" 844 "Fell Marine" 847 "Oceanvolt" 862 "Prospec" 868 "Data Panel" 890 "L3 Technologies" 894 "Rhodan Marine Systems" 896 "Nexfour Solutions" 905 "ASA Electronics" 909 "Marines Co (South Korea)" 911 "Nautic-on" 917 "Sentinel" 929 "JL Marine Systems" 930 "Ecotronix" 944 "Zontisa Marine" 951 "EXOR International" 962 "Timbolier Industries" 963 "TJC Micro" 968 "Cox Powertrain" 969 "Blue Seas" 981 "Kobelt Manufacturing" 992 "Blue Ocean IOT" 997 "Xenta Systems" 999 "Signal K" 1004 "Ultraflex" 1008 "Lintest SmartBoat" 1011 "Soundmax" 1020 "Team Italia Marine (Onyx Marine Automation s.r.l)" 1021 "Entratech" 1022 "ITC" 1029 "The Marine Guardian" 1047 "Sonic" 1051 "ProNav" 1053 "Vetus Maxwell INC." 1056 "Lithium Pros" 1059 "Boatrax" 1062 "Marol Co ltd" 1065 "CALYPSO Instruments" 1066 "Spot Zero Water" 1069 "Lithionics Battery" 1070 "Quick-teck Electronics" 1075 "Uniden America" 1083 "Nauticoncept" 1084 "Shadow-Caster LED lighting" 1085 "Wet Sounds" 1088 "E-T-A Circuit Breakers" 1092 "Scheiber" 1100 "Smart Yachts International Limited" 1109 "Dockmate" 1114 "Bobs Machine" 1118 "L3Harris ASV" 1119 "Balmar" 1120 "Elettromedia" 1127 "Electromaax" 1140 "Across Oceans Systems" 1145 "Kiwi Yachting" 1150 "BSB Artificial Intelligence" 1151 "Orca Technologies" 1154 "TBS Electronics" 1158 "Technoton Electroics" 1160 "MG Energy Systems" 1169 "Sea Machine Robotics" 1171 "Vista Manufacturing" 1183 "Zipwake" 1186 "Sailmon" 1192 "Airmoniq Pro Kft" 1194 "Sierra Marine" 1200 "Xinuo Information Technology (Xiamen)" 1218 "Septentrio" 1233 "NKE Marine Electronics" 1238 "SuperTrack Aps" 1239 "Honda Electronics" 1245 "Raritan Engineering" 1249 "Integrated Power Solutions AG" 1260 "Interactive Technologies" 1283 "LTG-Tech" 1299 "Energy Solutions (UK)" 1300 "WATT Fuel Cell" 1302 "Pro Mainer" 1305 "Dragonfly Energy" 1306 "Koden Electronics" 1311 "Humphree" 1316 "Hinkley Yachts" 1317 "Global Marine Management GmbH (GMM)" 1320 "Triskel Marine" 1330 "Warwick Control Technologies" 1331 "Dolphin Charger" 1337 "Barnacle Systems" 1348 "Radian IoT" 1353 "Ocean LED Marine" 1359 "BluNav" 1361 "OVA (Nantong Saiyang Electronics Co., Ltd)" 1368 "RAD Propulsion" 1369 "Electric Yacht" 1372 "Elco Motor Yachts" 1384 "Tecnoseal Foundry S.r.l" 1385 "Pro Charging Systems" 1389 "EVEX" 1398 "Gobius Sensor Technology" 1403 "Arco Marine" 1408 "Lenco Marine" 1413 "Naocontrol" 1417 "Revatek" 1438 "Aeolionics" 1439 "PredictWind" 1440 "Egis Mobile Electric" 1445 "Starboard Yacht Group" 1446 "Roswell Marine" 1451 "ePropulsion (Guangdong ePropulsion Technology Ltd.)" 1452 "Micro-Air" 1453 "Vital Battery" 1458 "Ride Controller" 1460 "Tocaro Blue" 1461 "Vanquish Yachts" 1471 "FT Technologies" 1478 "Alps Alpine" 1481 "E-Force Marine" 1482 "CMC Marine" 1483 "Nanjing Sandemarine Information Technology" 1850 "Teleflex Marine (SeaStar Solutions)" 1851 "Raymarine" 1852 "Navionics" 1853 "Japan Radio" 1854 "Northstar Technologies" 1855 "Furuno" 1856 "Trimble" 1857 "Simrad" 1858 "Litton" 1859 "Kvasar" 1860 "MMP" 1861 "Vector Cantech" 1862 "Yamaha Marine" 1863 "Faria Instruments" ;
VAL_ 2566851840 Industry_Code 0 "Global" 1 "Highway" 2 "Agriculture" 3 "Construction" 4 "Marine Industry" 5 "Industrial" ;
VAL_ 2566851840 Manufacturer_Code 69 "ARKS Enterprises" 78 "FW Murphy/Enovation Controls" 80 "Twin Disc" 85 "Kohler Power Systems" 88 "Hemisphere GPS" 135 "Airmar" 137 "Maretron" 140 "Lowrance" 144 "Mercury Marine" 147 "Nautibus Electronic" 148 "Blue Water Data" 154 "Westerbeke" 157 "ISSPRO" 161 "Offshore Systems (UK)" 163 "Evinrude/BRP" 165 "CPAC Systems" 168 "Xantrex Technology" 169 "Marlin Technologies" 172 "Yanmar Marine" 174 "Volvo Penta" 176 "Carling Technologies Inc. (Moritz Aerospace)" 185 "Beede Instruments" 192 "Floscan Instrument" 193 "Nobeltec" 198 "Mystic Valley Communications" 199 "Actia" 201 "Disenos Y Technologia" 211 "Digital Switching Systems" 215 "Xintex/Atena" 224 "EMMI NETWORK" 228 "ZF" 229 "Garmin" 233 "Yacht Monitoring Solutions" 235 "Sailormade Marine Telemetry/Tetra Technology" 243 "Eride" 257 "Honda Motor" 272 "Groco" 273 "Actisense" 274 "Amphenol LTW Technology" 275 "Navico" 283 "Hamilton Jet" 285 "Sea Recovery" 286 "Coelmo SRL Italy" 295 "BEP Marine" 304 "Empir Bus" 305 "NovAtel" 306 "Sleipner Motor" 307 "MBW Technologies" 315 "ICOM" 328 "Qwerty" 329 "Dief" 341 "Boening Automationstechnologie" 345 "Korean Maritime University" 351 "Thrane and Thrane" 355 "Mastervolt" 356 "Fischer Panda Generators" 358 "Victron Energy" 370 "Rolls Royce Marine" 373 "Electronic Design" 374 "Northern Lights" 378 "Glendinning" 381 "B & G" 384 "Rose Point Navigation Systems" 385 "Johnson Outdoors Marine Electronics Inc Geonav" 394 "Capi 2" 396 "Beyond Measure" 400 "Livorsi Marine" 404 "ComNav" 409 "Chetco" 419 "Fusion Electronics" 421 "Standard Horizon" 422 "True Heading" 426 "Egersund Marine Electronics" 427 "em-trak Marine Electronics" 431 "Tohatsu Co, JP" 437 "Digital Yacht" 438 "Comar Systems Limited" 440 "Cummins" 443 "VDO (aka Continental-Corporation)" 451 "Parker Hannifin aka Village Marine Tech" 459 "Alltek Marine Electronics" 460 "SAN GIORGIO S.E.I.N" 466 "Veethree Electronics & Marine" 470 "SI-TEX Marine Electronics" 471 "Sea Cross Marine" 475 "GME aka Standard Communications" 476 "Humminbird Marine Electronics" 478 "Ocean Sat" 481 "Chetco Digital Instruments" 493 "Watcheye" 499 "Lcj Capteurs" 502 "Attwood Marine" 503 "Naviop S.R.L." 504 "Vesper Marine" 510 "Marinesoft" 513 "Simarine" 517 "NoLand Engineering" 518 "Transas USA" 529 "National Instruments Korea" 530 "National Marine Electronics Association" 532 "Onwa Marine" 540 "Webasto" 571 "Marinecraft (South Korea)" 573 "McMurdo Group aka Orolia" 578 "Advansea" 579 "KVH" 580 "San Jose Technology" 583 "Yacht Control" 586 "Suzuki Motor" 591 "US Coast Guard" 595 "Ship Module aka Customware" 600 "Aquatic AV" 605 "Aventics" 606 "Intellian" 612 "SamwonIT" 614 "Arlt Tecnologies" 637 "Bavaria Yachts" 641 "Diverse Yacht Services" 644 "Wema U.S.A dba KUS" 658 "Shenzhen Jiuzhou Himunication" 688 "Rockford" 699 "Harman International" 704 "JL Audio" 708 "Lars Thrane" 715 "Autonnic" 717 "Yacht Devices" 734 "REAP Systems" 735 "AEM Performance Electronics" 739 "LxNav" 741 "Littelfuse, Inc (formerly Carling Technologies)" 743 "DaeMyung" 744 "Woosung" 748 "ISOTTA IFRA srl" 773 "Clarion US" 776 "HMI Systems" 777 "Ocean Signal" 778 "Seakeeper" 781 "Poly Planar" 785 "Fischer Panda DE" 795 "Broyda Industries" 796 "Canadian Automotive" 797 "Tides Marine" 798 "Lumishore" 799 "Still Water Designs and Audio" 802 "BJ Technologies (Beneteau)" 803 "Gill Sensors" 811 "Blue Water Desalination" 815 "FLIR" 824 "Undheim Systems" 826 "Lewmar" 838 "TeamSurv" 844 "Fell Marine" 847 "Oceanvolt" 862 "Prospec" 868 "Data Panel" 890 "L3 Technologies" 894 "Rhodan Marine Systems" 896 "Nexfour Solutions" 905 "ASA Electronics" 909 "Marines Co (South Korea)" 911 "Nautic-on" 917 "Sentinel" 929 "JL Marine Systems" 930 "Ecotronix" 944 "Zontisa Marine" 951 "EXOR International" 962 "Timbolier Industries" 963 "TJC Micro" 968 "Cox Powertrain" 969 "Blue Seas" 981 "Kobelt Manufacturing" 992 "Blue Ocean IOT" 997 "Xenta Systems" 999 "Signal K" 1004 "Ultraflex" 1008 "Lintest SmartBoat" 1011 "Soundmax" 1020 "Team Italia Marine (Onyx Marine Automation s.r.l)" 1021 "Entratech" 1022 "ITC" 1029 "The Marine Guardian" 1047 "Sonic" 1051 "ProNav" 1053 "Vetus Maxwell INC." 1056 "Lithium Pros" 1059 "Boatrax" 1062 "Marol Co ltd" 1065 "CALYPSO Instruments" 1066 "Spot Zero Water" 1069 "Lithionics Battery" 1070 "Quick-teck Electronics" 1075 "Uniden America" 1083 "Nauticoncept" 1084 "Shadow-Caster LED lighting" 1085 "Wet Sounds" 1088 "E-T-A Circuit Breakers" 1092 "Scheiber" 1100 "Smart Yachts International Limited" 1109 "Dockmate" 1114 "Bobs Machine" 1118 "L3Harris ASV" 1119 "Balmar" 1120 "Elettromedia" 1127 "Electromaax" 1140 "Across Oceans Systems" 1145 "Kiwi Yachting" 1150 "BSB Artificial Intelligence" 1151 "Orca Technologies" 1154 "TBS Electronics" 1158 "Technoton Electroics" 1160 "MG Energy Systems" 1169 "Sea Machine Robotics" 1171 "Vista Manufacturing" 1183 "Zipwake" 1186 "Sailmon" 1192 "Airmoniq Pro Kft" 1194 "Sierra Marine" 1200 "Xinuo Information Technology (Xiamen)" 1218 "Septentrio" 1233 "NKE Marine Electronics" 1238 "SuperTrack Aps" 1239 "Honda Electronics" 1245 "Raritan Engineering" 1249 "Integrated Power Solutions AG" 1260 "Interactive Technologies" 1283 "LTG-Tech" 1299 "Energy Solutions (UK)" 1300 "WATT Fuel Cell" 1302 "Pro Mainer" 1305 "Dragonfly Energy" 1306 "Koden Electronics" 1311 "Humphree" 1316 "Hinkley Yachts" 1317 "Global Marine Management GmbH (GMM)" 1320 "Triskel Marine" 1330 "Warwick Control Technologies" 1331 "Dolphin Charger" 1337 "Barnacle Systems" 1348 "Radian IoT" 1353 "Ocean LED Marine" 1359 "BluNav" 1361 "OVA (Nantong Saiyang Electronics Co., Ltd)" 1368 "RAD Propulsion" 1369 "Electric Yacht" 1372 "Elco Motor Yachts" 1384 "Tecnoseal Foundry S.r.l" 1385 "Pro Charging Systems" 1389 "EVEX" 1398 "Gobius Sensor Technology" 1403 "Arco Marine" 1408 "Lenco Marine" 1413 "Naocontrol" 1417 "Revatek" 1438 "Aeolionics" 1439 "PredictWind" 1440 "Egis Mobile Electric" 1445 "Starboard Yacht Group" 1446 "Roswell Marine" 1451 "ePropulsion (Guangdong ePropulsion Technology Ltd.)" 1452 "Micro-Air" 1453 "Vital Battery" 1458 "Ride Controller" 1460 "Tocaro Blue" 1461 "Vanquish Yachts" 1471 "FT Technologies" 1478 "Alps Alpine" 1481 "E-Force Marine" 1482 "CMC Marine" 1483 "Nanjing Sandemarine Information Technology" 1850 "Teleflex Marine (SeaStar Solutions)" 1851 "Raymarine" 1852 "Navionics" 1853 "Japan Radio" 1854 "Northstar Technologies" 1855 "Furuno" 1856 "Trimble" 1857 "Simrad" 1858 "Litton" 1859 "Kvasar" 1860 "MMP" 1861 "Vector Cantech" 1862 "Yamaha Marine" 1863 "Faria Instruments" ;
VAL_ 2566851840 Industry_Code 0 "Global" 1 "Highway" 2 "Agriculture" 3 "Construction" 4 "Marine Industry" 5 "Industrial" ;
VAL_ 2566852096 Manufacturer_Code 69 "ARKS Enterprises" 78 "FW Murphy/Enovation Controls" 80 "Twin Disc" 85 "Kohler Power Systems" 88 "Hemisphere GPS" 135 "Airmar" 137 "Maretron" 140 "Lowrance" 144 "Mercury Marine" 147 "Nautibus Electronic" 148 "Blue Water Data" 154 "Westerbeke" 157 "ISSPRO" 161 "Offshore Systems (UK)" 163 "Evinrude/BRP" 165 "CPAC Systems" 168 "Xantrex Technology" 169 "Marlin Technologies" 172 "Yanmar Marine" 174 "Volvo Penta" 176 "Carling Technologies Inc. (Moritz Aerospace)" 185 "Beede Instruments" 192 "Floscan Instrument" 193 "Nobeltec" 198 "Mystic Valley Communications" 199 "Actia" 201 "Disenos Y Technologia" 211 "Digital Switching Systems" 215 "Xintex/Atena" 224 "EMMI NETWORK" 228 "ZF" 229 "Garmin" 233 "Yacht Monitoring Solutions" 235 "Sailormade Marine Telemetry/Tetra Technology" 243 "Eride" 257 "Honda Motor" 272 "Groco" 273 "Actisense" 274 "Amphenol LTW Technology" 275 "Navico" 283 "Hamilton Jet" 285 "Sea Recovery" 286 "Coelmo SRL Italy" 295 "BEP Marine" 304 "Empir Bus" 305 "NovAtel" 306 "Sleipner Motor" 307 "MBW Technologies" 315 "ICOM" 328 "Qwerty" 329 "Dief" 341 "Boening Automationstechnologie" 345 "Korean Maritime University" 351 "Thrane and Thrane" 355 "Mastervolt" 356 "Fischer Panda Generators" 358 "Victron Energy" 370 "Rolls Royce Marine" 373 "Electronic Design" 374 "Northern Lights" 378 "Glendinning" 381 "B & G" 384 "Rose Point Navigation Systems" 385 "Johnson Outdoors Marine Electronics Inc Geonav" 394 "Capi 2" 396 "Beyond Measure" 400 "Livorsi Marine" 404 "ComNav" 409 "Chetco" 419 "Fusion Electronics" 421 "Standard Horizon" 422 "True Heading" 426 "Egersund Marine Electronics" 427 "em-trak Marine Electronics" 431 "Tohatsu Co, JP" 437 "Digital Yacht" 438 "Comar Systems Limited" 440 "Cummins" 443 "VDO (aka Continental-Corporation)" 451 "Parker Hannifin aka Village Marine Tech" 459 "Alltek Marine Electronics" 460 "SAN GIORGIO S.E.I.N" 466 "Veethree Electronics & Marine" 470 "SI-TEX Marine Electronics" 471 "Sea Cross Marine" 475 "GME aka Standard Communications" 476 "Humminbird Marine Electronics" 478 "Ocean Sat" 481 "Chetco Digital Instruments" 493 "Watcheye" 499 "Lcj Capteurs" 502 "Attwood Marine" 503 "Naviop S.R.L." 504 "Vesper Marine" 510 "Marinesoft" 513 "Simarine" 517 "NoLand Engineering" 518 "Transas USA" 529 "National Instruments Korea" 530 "National Marine Electronics Association" 532 "Onwa Marine" 540 "Webasto" 571 "Marinecraft (South Korea)" 573 "McMurdo Group aka Orolia" 578 "Advansea" 579 "KVH" 580 "San Jose Technology" 583 "Yacht Control" 586 "Suzuki Motor" 591 "US Coast Guard" 595 "Ship Module aka Customware" 600 "Aquatic AV" 605 "Aventics" 606 "Intellian" 612 "SamwonIT" 614 "Arlt Tecnologies" 637 "Bavaria Yachts" 641 "Diverse Yacht Services" 644 "Wema U.S.A dba KUS" 658 "Shenzhen Jiuzhou Himunication" 688 "Rockford" 699 "Harman International" 704 "JL Audio" 708 "Lars Thrane" 715 "Autonnic" 717 "Yacht Devices" 734 "REAP Systems" 735 "AEM Performance Electronics" 739 "LxNav" 741 "Littelfuse, Inc (formerly Carling Technologies)" 743 "DaeMyung" 744 "Woosung" 748 "ISOTTA IFRA srl" 773 "Clarion US" 776 "HMI Systems" 777 "Ocean Signal" 778 "Seakeeper" 781 "Poly Planar" 785 "Fischer Panda DE" 795 "Broyda Industries" 796 "Canadian Automotive" 797 "Tides Marine" 798 "Lumishore" 799 "Still Water Designs and Audio" 802 "BJ Technologies (Beneteau)" 803 "Gill Sensors" 811 "Blue Water Desalination" 815 "FLIR" 824 "Undheim Systems" 826 "Lewmar" 838 "TeamSurv" 844 "Fell Marine" 847 "Oceanvolt" 862 "Prospec" 868 "Data Panel" 890 "L3 Technologies" 894 "Rhodan Marine Systems" 896 "Nexfour Solutions" 905 "ASA Electronics" 909 "Marines Co (South Korea)" 911 "Nautic-on" 917 "Sentinel" 929 "JL Marine Systems" 930 "Ecotronix" 944 "Zontisa Marine" 951 "EXOR International" 962 "Timbolier Industries" 963 "TJC Micro" 968 "Cox Powertrain" 969 "Blue Seas" 981 "Kobelt Manufacturing" 992 "Blue Ocean IOT" 997 "Xenta Systems" 999 "Signal K" 1004 "Ultraflex" 1008 "Lintest SmartBoat" 1011 "Soundmax" 1020 "Team Italia Marine (Onyx Marine Automation s.r.l)" 1021 "Entratech" 1022 "ITC" 1029 "The Marine Guardian" 1047 "Sonic" 1051 "ProNav" 1053 "Vetus Maxwell INC." 1056 "Lithium Pros" 1059 "Boatrax" 1062 "Marol Co ltd" 1065 "CALYPSO Instruments" 1066 "Spot Zero Water" 1069 "Lithionics Battery" 1070 "Quick-teck Electronics" 1075 "Uniden America" 1083 "Nauticoncept" 1084 "Shadow-Caster LED lighting" 1085 "Wet Sounds" 1088 "E-T-A Circuit Breakers" 1092 "Scheiber" 1100 "Smart Yachts International Limited" 1109 "Dockmate" 1114 "Bobs Machine" 1118 "L3Harris ASV" 1119 "Balmar" 1120 "Elettromedia" 1127 "Electromaax" 1140 "Across Oceans Systems" 1145 "Kiwi Yachting" 1150 "BSB Artificial Intelligence" 1151 "Orca Technologies" 1154 "TBS Electronics" 1158 "Technoton Electroics" 1160 "MG Energy Systems" 1169 "Sea Machine Robotics" 1171 "Vista Manufacturing" 1183 "Zipwake" 1186 "Sailmon" 1192 "Airmoniq Pro Kft" 1194 "Sierra Marine" 1200 "Xinuo Information Technology (Xiamen)" 1218 "Septentrio" 1233 "NKE Marine Electronics" 1238 "SuperTrack Aps" 1239 "Honda Electronics" 1245 "Raritan Engineering" 1249 "Integrated Power Solutions AG" 1260 "Interactive Technologies" 1283 "LTG-Tech" 1299 "Energy Solutions (UK)" 1300 "WATT Fuel Cell" 1302 "Pro Mainer" 1305 "Dragonfly Energy" 1306 "Koden Electronics" 1311 "Humphree" 1316 "Hinkley Yachts" 1317 "Global Marine Management GmbH (GMM)" 1320 "Triskel Marine" 1330 "Warwick Control Technologies" 1331 "Dolphin Charger" 1337 "Barnacle Systems" 1348 "Radian IoT" 1353 "Ocean LED Marine" 1359 "BluNav" 1361 "OVA (Nantong Saiyang Electronics Co., Ltd)" 1368 "RAD Propulsion" 1369 "Electric Yacht" 1372 "Elco Motor Yachts" 1384 "Tecnoseal Foundry S.r.l" 1385 "Pro Charging Systems" 1389 "EVEX" 1398 "Gobius Sensor Technology" 1403 "Arco Marine" 1408 "Lenco Marine" 1413 "Naocontrol" 1417 "Revatek" 1438 "Aeolionics" 1439 "PredictWind" 1440 "Egis Mobile Electric" 1445 "Starboard Yacht Group" 1446 "Roswell Marine" 1451 "ePropulsion (Guangdong ePropulsion Technology Ltd.)" 1452 "Micro-Air" 1453 "Vital Battery" 1458 "Ride Controller" 1460 "Tocaro Blue" 1461 "Vanquish Yachts" 1471 "FT Technologies" 1478 "Alps Alpine" 1481 "E-Force Marine" 1482 "CMC Marine" 1483 "Nanjing Sandemarine Information Technology" 1850 "Teleflex Marine (SeaStar Solutions)" 1851 "Raymarine" 1852 "Navionics" 1853 "Japan Radio" 1854 "Northstar Technologies" 1855 "Furuno" 1856 "Trimble" 1857 "Simrad" 1858 "Litton" 1859 "Kvasar" 1860 "MMP" 1861 "Vector Cantech" 1862 "Yamaha Marine" 1863 "Faria Instruments" ;
VAL_ 2566852096 Industry_Code 0 "Global" 1 "Highway" 2 "Agriculture" 3 "Construction" 4 "Marine Industry" 5 "Industrial" ;
VAL_ 2566852352 Manufacturer_Code 69 "ARKS Enterprises" 78 "FW Murphy/Enovation Controls" 80 "Twin Disc" 85 "Kohler Power Systems" 88 "Hemisphere GPS" 135 "Airmar" 137 "Maretron" 140 "Lowrance" 144 "Mercury Marine" 147 "Nautibus Electronic" 148 "Blue Water Data" 154 "Westerbeke" 157 "ISSPRO" 161 "Offshore Systems (UK)" 163 "Evinrude/BRP" 165 "CPAC Systems" 168 "Xantrex Technology" 169 "Marlin Technologies" 172 "Yanmar Marine" 174 "Volvo Penta" 176 "Carling Technologies Inc. (Moritz Aerospace)" 185 "Beede Instruments" 192 "Floscan Instrument" 193 "Nobeltec" 198 "Mystic Valley Communications" 199 "Actia" 201 "Disenos Y Technologia" 211 "Digital Switching Systems" 215 "Xintex/Atena" 224 "EMMI NETWORK" 228 "ZF" 229 "Garmin" 233 "Yacht Monitoring Solutions" 235 "Sailormade Marine Telemetry/Tetra Technology" 243 "Eride" 257 "Honda Motor" 272 "Groco" 273 "Actisense" 274 "Amphenol LTW Technology" 275 "Navico" 283 "Hamilton Jet" 285 "Sea Recovery" 286 "Coelmo SRL Italy" 295 "BEP Marine" 304 "Empir Bus" 305 "NovAtel" 306 "Sleipner Motor" 307 "MBW Technologies" 315 "ICOM" 328 "Qwerty" 329 "Dief" 341 "Boening Automationstechnologie" 345 "Korean Maritime University" 351 "Thrane and Thrane" 355 "Mastervolt" 356 "Fischer Panda Generators" 358 "Victron Energy" 370 "Rolls Royce Marine" 373 "Electronic Design" 374 "Northern Lights" 378 "Glendinning" 381 "B & G" 384 "Rose Point Navigation Systems" 385 "Johnson Outdoors Marine Electronics Inc Geonav" 394 "Capi 2" 396 "Beyond Measure" 400 "Livorsi Marine" 404 "ComNav" 409 "Chetco" 419 "Fusion Electronics" 421 "Standard Horizon" 422 "True Heading" 426 "Egersund Marine Electronics" 427 "em-trak Marine Electronics" 431 "Tohatsu Co, JP" 437 "Digital Yacht" 438 "Comar Systems Limited" 440 "Cummins" 443 "VDO (aka Continental-Corporation)" 451 "Parker Hannifin aka Village Marine Tech" 459 "Alltek Marine Electronics" 460 "SAN GIORGIO S.E.I.N" 466 "Veethree Electronics & Marine" 470 "SI-TEX Marine Electronics" 471 "Sea Cross Marine" 475 "GME aka Standard Communications" 476 "Humminbird Marine Electronics" 478 "Ocean Sat" 481 "Chetco Digital Instruments" 493 "Watcheye" 499 "Lcj Capteurs" 502 "Attwood Marine" 503 "Naviop S.R.L." 504 "Vesper Marine" 510 "Marinesoft" 513 "Simarine" 517 "NoLand Engineering" 518 "Transas USA" 529 "National Instruments Korea" 530 "National Marine Electronics Association" 532 "Onwa Marine" 540 "Webasto" 571 "Marinecraft (South Korea)" 573 "McMurdo Group aka Orolia" 578 "Advansea" 579 "KVH" 580 "San Jose Technology" 583 "Yacht Control" 586 "Suzuki Motor" 591 "US Coast Guard" 595 "Ship Module aka Customware" 600 "Aquatic AV" 605 "Aventics" 606 "Intellian" 612 "SamwonIT" 614 "Arlt Tecnologies" 637 "Bavaria Yachts" 641 "Diverse Yacht Services" 644 "Wema U.S.A dba KUS" 658 "Shenzhen Jiuzhou Himunication" 688 "Rockford" 699 "Harman International" 704 "JL Audio" 708 "Lars Thrane" 715 "Autonnic" 717 "Yacht Devices" 734 "REAP Systems" 735 "AEM Performance Electronics" 739 "LxNav" 741 "Littelfuse, Inc (formerly Carling Technologies)" 743 "DaeMyung" 744 "Woosung" 748 "ISOTTA IFRA srl" 773 "Clarion US" 776 "HMI Systems" 777 "Ocean Signal" 778 "Seakeeper" 781 "Poly Planar" 785 "Fischer Panda DE" 795 "Broyda Industries" 796 "Canadian Automotive" 797 "Tides Marine" 798 "Lumishore" 799 "Still Water Designs and Audio" 802 "BJ Technologies (Beneteau)" 803 "Gill Sensors" 811 "Blue Water Desalination" 815 "FLIR" 824 "Undheim Systems" 826 "Lewmar" 838 "TeamSurv" 844 "Fell Marine" 847 "Oceanvolt" 862 "Prospec" 868 "Data Panel" 890 "L3 Technologies" 894 "Rhodan Marine Systems" 896 "Nexfour Solutions" 905 "ASA Electronics" 909 "Marines Co (South Korea)" 911 "Nautic-on" 917 "Sentinel" 929 "JL Marine Systems" 930 "Ecotronix" 944 "Zontisa Marine" 951 "EXOR International" 962 "Timbolier Industries" 963 "TJC Micro" 968 "Cox Powertrain" 969 "Blue Seas" 981 "Kobelt Manufacturing" 992 "Blue Ocean IOT" 997 "Xenta Systems" 999 "Signal K" 1004 "Ultraflex" 1008 "Lintest SmartBoat" 1011 "Soundmax" 1020 "Team Italia Marine (Onyx Marine Automation s.r.l)" 1021 "Entratech" 1022 "ITC" 1029 "The Marine Guardian" 1047 "Sonic" 1051 "ProNav" 1053 "Vetus Maxwell INC." 1056 "Lithium Pros" 1059 "Boatrax" 1062 "Marol Co ltd" 1065 "CALYPSO Instruments" 1066 "Spot Zero Water" 1069 "Lithionics Battery" 1070 "Quick-teck Electronics" 1075 "Uniden America" 1083 "Nauticoncept" 1084 "Shadow-Caster LED lighting" 1085 "Wet Sounds" 1088 "E-T-A Circuit Breakers" 1092 "Scheiber" 1100 "Smart Yachts International Limited" 1109 "Dockmate" 1114 "Bobs Machine" 1118 "L3Harris ASV" 1119 "Balmar" 1120 "Elettromedia" 1127 "Electromaax" 1140 "Across Oceans Systems" 1145 "Kiwi Yachting" 1150 "BSB Artificial Intelligence" 1151 "Orca Technologies" 1154 "TBS Electronics" 1158 "Technoton Electroics" 1160 "MG Energy Systems" 1169 "Sea Machine Robotics" 1171 "Vista Manufacturing" 1183 "Zipwake" 1186 "Sailmon" 1192 "Airmoniq Pro Kft" 1194 "Sierra Marine" 1200 "Xinuo Information Technology (Xiamen)" 1218 "Septentrio" 1233 "NKE Marine Electronics" 1238 "SuperTrack Aps" 1239 "Honda Electronics" 1245 "Raritan Engineering" 1249 "Integrated Power Solutions AG" 1260 "Interactive Technologies" 1283 "LTG-Tech" 1299 "Energy Solutions (UK)" 1300 "WATT Fuel Cell" 1302 "Pro Mainer" 1305 "Dragonfly Energy" 1306 "Koden Electronics" 1311 "Humphree" 1316 "Hinkley Yachts" 1317 "Global Marine Management GmbH (GMM)" 1320 "Triskel Marine" 1330 "Warwick Control Technologies" 1331 "Dolphin Charger" 1337 "Barnacle Systems" 1348 "Radian IoT" 1353 "Ocean LED Marine" 1359 "BluNav" 1361 "OVA (Nantong Saiyang Electronics Co., Ltd)" 1368 "RAD Propulsion" 1369 "Electric Yacht" 1372 "Elco Motor Yachts" 1384 "Tecnoseal Foundry S.r.l" 1385 "Pro Charging Systems" 1389 "EVEX" 1398 "Gobius Sensor Technology" 1403 "Arco Marine" 1408 "Lenco Marine" 1413 "Naocontrol" 1417 "Revatek" 1438 "Aeolionics" 1439 "PredictWind" 1440 "Egis Mobile Electric" 1445 "Starboard Yacht Group" 1446 "Roswell Marine" 1451 "ePropulsion (Guangdong ePropulsion Technology Ltd.)" 1452 "Micro-Air" 1453 "Vital Battery" 1458 "Ride Controller" 1460 "Tocaro Blue" 1461 "Vanquish Yachts" 1471 "FT Technologies" 1478 "Alps Alpine" 1481 "E-Force Marine" 1482 "CMC Marine" 1483 "Nanjing Sandemarine Information Technology" 1850 "Teleflex Marine (SeaStar Solutions)" 1851 "Raymarine" 1852 "Navionics" 1853 "Japan Radio" 1854 "Northstar Technologies" 1855 "Furuno" 1856 "Trimble" 1857 "Simrad" 1858 "Litton" 1859 "Kvasar" 1860 "MMP" 1861 "Vector Cantech" 1862 "Yamaha Marine" 1863 "Faria Instruments" ;
VAL_ 2566852352 Industry_Code 0 "Global" 1 "Highway" 2 "Agriculture" 3 "Construction" 4 "Marine Industry" 5 "Industrial" ;
VAL_ 2566852352 Alarm_Type 1 "AC Voltage Error" 2 "AC Frequency Error" 3 "AC High Power" 4 "DC Low Voltage" 5 "DC Very Low Voltage" 6 "DC High Voltage" 7 "DC Low Battery Capacity" 10 "Out of Range" 11 "Low Run Current" 12 "Over Current" 13 "Short Circuit" 14 "Missing Commander" 15 "Reverse Current" 16 "Calibration Error" 17 "Missing Output" 18 "Systems On" 19 "AC Very High Power" 20 "AC Low Power" 21 "DC Very Low Battery Capacity" 22 "Battery Full" 23 "DC Load Shed Low" 24 "DC Load Shed Very Low" 25 "AC Load Shed Low" 26 "AC Load Shed Very Low" 27 "Reverse Polarity" 28 "Manual Override" 29 "Mastervolt" 30 "Hardware Fault" 31 "No AC Supply" 34 "PGN Switching On" 35 "Low Canbus Voltage" 36 "Blown Fuse" 37 "Manual Bypass" 38 "Generic Alarm" 39 "Battery Temperature Alarm" 40 "Temperature Sensor Error" 41 "AC IN Out Of Range" 42 "Device In Overload" 43 "High Temperature" 44 "Inverter/Charger Installation Error" 45 "Inverter Installation Error" 46 "Charger Installation Error" 47 "Cable Voltage Drop Too High" 48 "Shunt mismatch" 49 "Cooling Fan Error" 50 "Mastershunt Fuse Blown" 51 "High Temperature" 52 "Over Pressure" 53 "Low Pressure" 54 "Rapid Deflation" 55 "Inverter/Charger Over Temperature" 56 "Confirm On" 57 "Battery Safety" 58 "Stop Charging" 59 "Check Battery Relay" 60 "Battery Hardware Failure" 61 "Battery Over Current" 62 "Battery Temperature Low" 63 "Battery Temperature High" 64 "Battery Last 100" ;
VAL_ 2566852608 Manufacturer_Code 69 "ARKS Enterprises" 78 "FW Murphy/Enovation Controls" 80 "Twin Disc" 85 "Kohler Power Systems" 88 "Hemisphere GPS" 135 "Airmar" 137 "Maretron" 140 "Lowrance" 144 "Mercury Marine" 147 "Nautibus Electronic" 148 "Blue Water Data" 154 "Westerbeke" 157 "ISSPRO" 161 "Offshore Systems (UK)" 163 "Evinrude/BRP" 165 "CPAC Systems" 168 "Xantrex Technology" 169 "Marlin Technologies" 172 "Yanmar Marine" 174 "Volvo Penta" 176 "Carling Technologies Inc. (Moritz Aerospace)" 185 "Beede Instruments" 192 "Floscan Instrument" 193 "Nobeltec" 198 "Mystic Valley Communications" 199 "Actia" 201 "Disenos Y Technologia" 211 "Digital Switching Systems" 215 "Xintex/Atena" 224 "EMMI NETWORK" 228 "ZF" 229 "Garmin" 233 "Yacht Monitoring Solutions" 235 "Sailormade Marine Telemetry/Tetra Technology" 243 "Eride" 257 "Honda Motor" 272 "Groco" 273 "Actisense" 274 "Amphenol LTW Technology" 275 "Navico" 283 "Hamilton Jet" 285 "Sea Recovery" 286 "Coelmo SRL Italy" 295 "BEP Marine" 304 "Empir Bus" 305 "NovAtel" 306 "Sleipner Motor" 307 "MBW Technologies" 315 "ICOM" 328 "Qwerty" 329 "Dief" 341 "Boening Automationstechnologie" 345 "Korean Maritime University" 351 "Thrane and Thrane" 355 "Mastervolt" 356 "Fischer Panda Generators" 358 "Victron Energy" 370 "Rolls Royce Marine" 373 "Electronic Design" 374 "Northern Lights" 378 "Glendinning" 381 "B & G" 384 "Rose Point Navigation Systems" 385 "Johnson Outdoors Marine Electronics Inc Geonav" 394 "Capi 2" 396 "Beyond Measure" 400 "Livorsi Marine" 404 "ComNav" 409 "Chetco" 419 "Fusion Electronics" 421 "Standard Horizon" 422 "True Heading" 426 "Egersund Marine Electronics" 427 "em-trak Marine Electronics" 431 "Tohatsu Co, JP" 437 "Digital Yacht" 438 "Comar Systems Limited" 440 "Cummins" 443 "VDO (aka Continental-Corporation)" 451 "Parker Hannifin aka Village Marine Tech" 459 "Alltek Marine Electronics" 460 "SAN GIORGIO S.E.I.N" 466 "Veethree Electronics & Marine" 470 "SI-TEX Marine Electronics" 471 "Sea Cross Marine" 475 "GME aka Standard Communications" 476 "Humminbird Marine Electronics" 478 "Ocean Sat" 481 "Chetco Digital Instruments" 493 "Watcheye" 499 "Lcj Capteurs" 502 "Attwood Marine" 503 "Naviop S.R.L." 504 "Vesper Marine" 510 "Marinesoft" 513 "Simarine" 517 "NoLand Engineering" 518 "Transas USA" 529 "National Instruments Korea" 530 "National Marine Electronics Association" 532 "Onwa Marine" 540 "Webasto" 571 "Marinecraft (South Korea)" 573 "McMurdo Group aka Orolia" 578 "Advansea" 579 "KVH" 580 "San Jose Technology" 583 "Yacht Control" 586 "Suzuki Motor" 591 "US Coast Guard" 595 "Ship Module aka Customware" 600 "Aquatic AV" 605 "Aventics" 606 "Intellian" 612 "SamwonIT" 614 "Arlt Tecnologies" 637 "Bavaria Yachts" 641 "Diverse Yacht Services" 644 "Wema U.S.A dba KUS" 658 "Shenzhen Jiuzhou Himunication" 688 "Rockford" 699 "Harman International" 704 "JL Audio" 708 "Lars Thrane" 715 "Autonnic" 717 "Yacht Devices" 734 "REAP Systems" 735 "AEM Performance Electronics" 739 "LxNav" 741 "Littelfuse, Inc (formerly Carling Technologies)" 743 "DaeMyung" 744 "Woosung" 748 "ISOTTA IFRA srl" 773 "Clarion US" 776 "HMI Systems" 777 "Ocean Signal" 778 "Seakeeper" 781 "Poly Planar" 785 "Fischer Panda DE" 795 "Broyda Industries" 796 "Canadian Automotive" 797 "Tides Marine" 798 "Lumishore" 799 "Still Water Designs and Audio" 802 "BJ Technologies (Beneteau)" 803 "Gill Sensors" 811 "Blue Water Desalination" 815 "FLIR" 824 "Undheim Systems" 826 "Lewmar" 838 "TeamSurv" 844 "Fell Marine" 847 "Oceanvolt" 862 "Prospec" 868 "Data Panel" 890 "L3 Technologies" 894 "Rhodan Marine Systems" 896 "Nexfour Solutions" 905 "ASA Electronics" 909 "Marines Co (South Korea)" 911 "Nautic-on" 917 "Sentinel" 929 "JL Marine Systems" 930 "Ecotronix" 944 "Zontisa Marine" 951 "EXOR International" 962 "Timbolier Industries" 963 "TJC Micro" 968 "Cox Powertrain" 969 "Blue Seas" 981 "Kobelt Manufacturing" 992 "Blue Ocean IOT" 997 "Xenta Systems" 999 "Signal K" 1004 "Ultraflex" 1008 "Lintest SmartBoat" 1011 "Soundmax" 1020 "Team Italia Marine (Onyx Marine Automation s.r.l)" 1021 "Entratech" 1022 "ITC" 1029 "The Marine Guardian" 1047 "Sonic" 1051 "ProNav" 1053 "Vetus Maxwell INC." 1056 "Lithium Pros" 1059 "Boatrax" 1062 "Marol Co ltd" 1065 "CALYPSO Instruments" 1066 "Spot Zero Water" 1069 "Lithionics Battery" 1070 "Quick-teck Electronics" 1075 "Uniden America" 1083 "Nauticoncept" 1084 "Shadow-Caster LED lighting" 1085 "Wet Sounds" 1088 "E-T-A Circuit Breakers" 1092 "Scheiber" 1100 "Smart Yachts International Limited" 1109 "Dockmate" 1114 "Bobs Machine" 1118 "L3Harris ASV" 1119 "Balmar" 1120 "Elettromedia" 1127 "Electromaax" 1140 "Across Oceans Systems" 1145 "Kiwi Yachting" 1150 "BSB Artificial Intelligence" 1151 "Orca Technologies" 1154 "TBS Electronics" 1158 "Technoton Electroics" 1160 "MG Energy Systems" 1169 "Sea Machine Robotics" 1171 "Vista Manufacturing" 1183 "Zipwake" 1186 "Sailmon" 1192 "Airmoniq Pro Kft" 1194 "Sierra Marine" 1200 "Xinuo Information Technology (Xiamen)" 1218 "Septentrio" 1233 "NKE Marine Electronics" 1238 "SuperTrack Aps" 1239 "Honda Electronics" 1245 "Raritan Engineering" 1249 "Integrated Power Solutions AG" 1260 "Interactive Technologies" 1283 "LTG-Tech" 1299 "Energy Solutions (UK)" 1300 "WATT Fuel Cell" 1302 "Pro Mainer" 1305 "Dragonfly Energy" 1306 "Koden Electronics" 1311 "Humphree" 1316 "Hinkley Yachts" 1317 "Global Marine Management GmbH (GMM)" 1320 "Triskel Marine" 1330 "Warwick Control Technologies" 1331 "Dolphin Charger" 1337 "Barnacle Systems" 1348 "Radian IoT" 1353 "Ocean LED Marine" 1359 "BluNav" 1361 "OVA (Nantong Saiyang Electronics Co., Ltd)" 1368 "RAD Propulsion" 1369 "Electric Yacht" 1372 "Elco Motor Yachts" 1384 "Tecnoseal Foundry S.r.l" 1385 "Pro Charging Systems" 1389 "EVEX" 1398 "Gobius Sensor Technology" 1403 "Arco Marine" 1408 "Lenco Marine" 1413 "Naocontrol" 1417 "Revatek" 1438 "Aeolionics" 1439 "PredictWind" 1440 "Egis Mobile Electric" 1445 "Starboard Yacht Group" 1446 "Roswell Marine" 1451 "ePropulsion (Guangdong ePropulsion Technology Ltd.)" 1452 "Micro-Air" 1453 "Vital Battery" 1458 "Ride Controller" 1460 "Tocaro Blue" 1461 "Vanquish Yachts" 1471 "FT Technologies" 1478 "Alps Alpine" 1481 "E-Force Marine" 1482 "CMC Marine" 1483 "Nanjing Sandemarine Information Technology" 1850 "Teleflex Marine (SeaStar Solutions)" 1851 "Raymarine" 1852 "Navionics" 1853 "Japan Radio" 1854 "Northstar Technologies" 1855 "Furuno" 1856 "Trimble" 1857 "Simrad" 1858 "Litton" 1859 "Kvasar" 1860 "MMP" 1861 "Vector Cantech" 1862 "Yamaha Marine" 1863 "Faria Instruments" ;
VAL_ 2566852608 Industry_Code 0 "Global" 1 "Highway" 2 "Agriculture" 3 "Construction" 4 "Marine Industry" 5 "Industrial" ;
VAL_ 2566852864 Manufacturer_Code 69 "ARKS Enterprises" 78 "FW Murphy/Enovation Controls" 80 "Twin Disc" 85 "Kohler Power Systems" 88 "Hemisphere GPS" 135 "Airmar" 137 "Maretron" 140 "Lowrance" 144 "Mercury Marine" 147 "Nautibus Electronic" 148 "Blue Water Data" 154 "Westerbeke" 157 "ISSPRO" 161 "Offshore Systems (UK)" 163 "Evinrude/BRP" 165 "CPAC Systems" 168 "Xantrex Technology" 169 "Marlin Technologies" 172 "Yanmar Marine" 174 "Volvo Penta" 176 "Carling Technologies Inc. (Moritz Aerospace)" 185 "Beede Instruments" 192 "Floscan Instrument" 193 "Nobeltec" 198 "Mystic Valley Communications" 199 "Actia" 201 "Disenos Y Technologia" 211 "Digital Switching Systems" 215 "Xintex/Atena" 224 "EMMI NETWORK" 228 "ZF" 229 "Garmin" 233 "Yacht Monitoring Solutions" 235 "Sailormade Marine Telemetry/Tetra Technology" 243 "Eride" 257 "Honda Motor" 272 "Groco" 273 "Actisense" 274 "Amphenol LTW Technology" 275 "Navico" 283 "Hamilton Jet" 285 "Sea Recovery" 286 "Coelmo SRL Italy" 295 "BEP Marine" 304 "Empir Bus" 305 "NovAtel" 306 "Sleipner Motor" 307 "MBW Technologies" 315 "ICOM" 328 "Qwerty" 329 "Dief" 341 "Boening Automationstechnologie" 345 "Korean Maritime University" 351 "Thrane and Thrane" 355 "Mastervolt" 356 "Fischer Panda Generators" 358 "Victron Energy" 370 "Rolls Royce Marine" 373 "Electronic Design" 374 "Northern Lights" 378 "Glendinning" 381 "B & G" 384 "Rose Point Navigation Systems" 385 "Johnson Outdoors Marine Electronics Inc Geonav" 394 "Capi 2" 396 "Beyond Measure" 400 "Livorsi Marine" 404 "ComNav" 409 "Chetco" 419 "Fusion Electronics" 421 "Standard Horizon" 422 "True Heading" 426 "Egersund Marine Electronics" 427 "em-trak Marine Electronics" 431 "Tohatsu Co, JP" 437 "Digital Yacht" 438 "Comar Systems Limited" 440 "Cummins" 443 "VDO (aka Continental-Corporation)" 451 "Parker Hannifin aka Village Marine Tech" 459 "Alltek Marine Electronics" 460 "SAN GIORGIO S.E.I.N" 466 "Veethree Electronics & Marine" 470 "SI-TEX Marine Electronics" 471 "Sea Cross Marine" 475 "GME aka Standard Communications" 476 "Humminbird Marine Electronics" 478 "Ocean Sat" 481 "Chetco Digital Instruments" 493 "Watcheye" 499 "Lcj Capteurs" 502 "Attwood Marine" 503 "Naviop S.R.L." 504 "Vesper Marine" 510 "Marinesoft" 513 "Simarine" 517 "NoLand Engineering" 518 "Transas USA" 529 "National Instruments Korea" 530 "National Marine Electronics Association" 532 "Onwa Marine" 540 "Webasto" 571 "Marinecraft (South Korea)" 573 "McMurdo Group aka Orolia" 578 "Advansea" 579 "KVH" 580 "San Jose Technology" 583 "Yacht Control" 586 "Suzuki Motor" 591 "US Coast Guard" 595 "Ship Module aka Customware" 600 "Aquatic AV" 605 "Aventics" 606 "Intellian" 612 "SamwonIT" 614 "Arlt Tecnologies" 637 "Bavaria Yachts" 641 "Diverse Yacht Services" 644 "Wema U.S.A dba KUS" 658 "Shenzhen Jiuzhou Himunication" 688 "Rockford" 699 "Harman International" 704 "JL Audio" 708 "Lars Thrane" 715 "Autonnic" 717 "Yacht Devices" 734 "REAP Systems" 735 "AEM Performance Electronics" 739 "LxNav" 741 "Littelfuse, Inc (formerly Carling Technologies)" 743 "DaeMyung" 744 "Woosung" 748 "ISOTTA IFRA srl" 773 "Clarion US" 776 "HMI Systems" 777 "Ocean Signal" 778 "Seakeeper" 781 "Poly Planar" 785 "Fischer Panda DE" 795 "Broyda Industries" 796 "Canadian Automotive" 797 "Tides Marine" 798 "Lumishore" 799 "Still Water Designs and Audio" 802 "BJ Technologies (Beneteau)" 803 "Gill Sensors" 811 "Blue Water Desalination" 815 "FLIR" 824 "Undheim Systems" 826 "Lewmar" 838 "TeamSurv" 844 "Fell Marine" 847 "Oceanvolt" 862 "Prospec" 868 "Data Panel" 890 "L3 Technologies" 894 "Rhodan Marine Systems" 896 "Nexfour Solutions" 905 "ASA Electronics" 909 "Marines Co (South Korea)" 911 "Nautic-on" 917 "Sentinel" 929 "JL Marine Systems" 930 "Ecotronix" 944 "Zontisa Marine" 951 "EXOR International" 962 "Timbolier Industries" 963 "TJC Micro" 968 "Cox Powertrain" 969 "Blue Seas" 981 "Kobelt Manufacturing" 992 "Blue Ocean IOT" 997 "Xenta Systems" 999 "Signal K" 1004 "Ultraflex" 1008 "Lintest SmartBoat" 1011 "Soundmax" 1020 "Team Italia Marine (Onyx Marine Automation s.r.l)" 1021 "Entratech" 1022 "ITC" 1029 "The Marine Guardian" 1047 "Sonic" 1051 "ProNav" 1053 "Vetus Maxwell INC." 1056 "Lithium Pros" 1059 "Boatrax" 1062 "Marol Co ltd" 1065 "CALYPSO Instruments" 1066 "Spot Zero Water" 1069 "Lithionics Battery" 1070 "Quick-teck Electronics" 1075 "Uniden America" 1083 "Nauticoncept" 1084 "Shadow-Caster LED lighting" 1085 "Wet Sounds" 1088 "E-T-A Circuit Breakers" 1092 "Scheiber" 1100 "Smart Yachts International Limited" 1109 "Dockmate" 1114 "Bobs Machine" 1118 "L3Harris ASV" 1119 "Balmar" 1120 "Elettromedia" 1127 "Electromaax" 1140 "Across Oceans Systems" 1145 "Kiwi Yachting" 1150 "BSB Artificial Intelligence" 1151 "Orca Technologies" 1154 "TBS Electronics" 1158 "Technoton Electroics" 1160 "MG Energy Systems" 1169 "Sea Machine Robotics" 1171 "Vista Manufacturing" 1183 "Zipwake" 1186 "Sailmon" 1192 "Airmoniq Pro Kft" 1194 "Sierra Marine" 1200 "Xinuo Information Technology (Xiamen)" 1218 "Septentrio" 1233 "NKE Marine Electronics" 1238 "SuperTrack Aps" 1239 "Honda Electronics" 1245 "Raritan Engineering" 1249 "Integrated Power Solutions AG" 1260 "Interactive Technologies" 1283 "LTG-Tech" 1299 "Energy Solutions (UK)" 1300 "WATT Fuel Cell" 1302 "Pro Mainer" 1305 "Dragonfly Energy" 1306 "Koden Electronics" 1311 "Humphree" 1316 "Hinkley Yachts" 1317 "Global Marine Management GmbH (GMM)" 1320 "Triskel Marine" 1330 "Warwick Control Technologies" 1331 "Dolphin Charger" 1337 "Barnacle Systems" 1348 "Radian IoT" 1353 "Ocean LED Marine" 1359 "BluNav" 1361 "OVA (Nantong Saiyang Electronics Co., Ltd)" 1368 "RAD Propulsion" 1369 "Electric Yacht" 1372 "Elco Motor Yachts" 1384 "Tecnoseal Foundry S.r.l" 1385 "Pro Charging Systems" 1389 "EVEX" 1398 "Gobius Sensor Technology" 1403 "Arco Marine" 1408 "Lenco Marine" 1413 "Naocontrol" 1417 "Revatek" 1438 "Aeolionics" 1439 "PredictWind" 1440 "Egis Mobile Electric" 1445 "Starboard Yacht Group" 1446 "Roswell Marine" 1451 "ePropulsion (Guangdong ePropulsion Technology Ltd.)" 1452 "Micro-Air" 1453 "Vital Battery" 1458 "Ride Controller" 1460 "Tocaro Blue" 1461 "Vanquish Yachts" 1471 "FT Technologies" 1478 "Alps Alpine" 1481 "E-Force Marine" 1482 "CMC Marine" 1483 "Nanjing Sandemarine Information Technology" 1850 "Teleflex Marine (SeaStar Solutions)" 1851 "Raymarine" 1852 "Navionics" 1853 "Japan Radio" 1854 "Northstar Technologies" 1855 "Furuno" 1856 "Trimble" 1857 "Simrad" 1858 "Litton" 1859 "Kvasar" 1860 "MMP" 1861 "Vector Cantech" 1862 "Yamaha Marine" 1863 "Faria Instruments" ;
VAL_ 2566852864 Industry_Code 0 "Global" 1 "Highway" 2 "Agriculture" 3 "Construction" 4 "Marine Industry" 5 "Industrial" ;
VAL_ 2566853120 Manufacturer_Code 69 "ARKS Enterprises" 78 "FW Murphy/Enovation Controls" 80 "Twin Disc" 85 "Kohler Power Systems" 88 "Hemisphere GPS" 135 "Airmar" 137 "Maretron" 140 "Lowrance" 144 "Mercury Marine" 147 "Nautibus Electronic" 148 "Blue Water Data" 154 "Westerbeke" 157 "ISSPRO" 161 "Offshore Systems (UK)" 163 "Evinrude/BRP" 165 "CPAC Systems" 168 "Xantrex Technology" 169 "Marlin Technologies" 172 "Yanmar Marine" 174 "Volvo Penta" 176 "Carling Technologies Inc. (Moritz Aerospace)" 185 "Beede Instruments" 192 "Floscan Instrument" 193 "Nobeltec" 198 "Mystic Valley Communications" 199 "Actia" 201 "Disenos Y Technologia" 211 "Digital Switching Systems" 215 "Xintex/Atena" 224 "EMMI NETWORK" 228 "ZF" 229 "Garmin" 233 "Yacht Monitoring Solutions" 235 "Sailormade Marine Telemetry/Tetra Technology" 243 "Eride" 257 "Honda Motor" 272 "Groco" 273 "Actisense" 274 "Amphenol LTW Technology" 275 "Navico" 283 "Hamilton Jet" 285 "Sea Recovery" 286 "Coelmo SRL Italy" 295 "BEP Marine" 304 "Empir Bus" 305 "NovAtel" 306 "Sleipner Motor" 307 "MBW Technologies" 315 "ICOM" 328 "Qwerty" 329 "Dief" 341 "Boening Automationstechnologie" 345 "Korean Maritime University" 351 "Thrane and Thrane" 355 "Mastervolt" 356 "Fischer Panda Generators" 358 "Victron Energy" 370 "Rolls Royce Marine" 373 "Electronic Design" 374 "Northern Lights" 378 "Glendinning" 381 "B & G" 384 "Rose Point Navigation Systems" 385 "Johnson Outdoors Marine Electronics Inc Geonav" 394 "Capi 2" 396 "Beyond Measure" 400 "Livorsi Marine" 404 "ComNav" 409 "Chetco" 419 "Fusion Electronics" 421 "Standard Horizon" 422 "True Heading" 426 "Egersund Marine Electronics" 427 "em-trak Marine Electronics" 431 "Tohatsu Co, JP" 437 "Digital Yacht" 438 "Comar Systems Limited" 440 "Cummins" 443 "VDO (aka Continental-Corporation)" 451 "Parker Hannifin aka Village Marine Tech" 459 "Alltek Marine Electronics" 460 "SAN GIORGIO S.E.I.N" 466 "Veethree Electronics & Marine" 470 "SI-TEX Marine Electronics" 471 "Sea Cross Marine" 475 "GME aka Standard Communications" 476 "Humminbird Marine Electronics" 478 "Ocean Sat" 481 "Chetco Digital Instruments" 493 "Watcheye" 499 "Lcj Capteurs" 502 "Attwood Marine" 503 "Naviop S.R.L." 504 "Vesper Marine" 510 "Marinesoft" 513 "Simarine" 517 "NoLand Engineering" 518 "Transas USA" 529 "National Instruments Korea" 530 "National Marine Electronics Association" 532 "Onwa Marine" 540 "Webasto" 571 "Marinecraft (South Korea)" 573 "McMurdo Group aka Orolia" 578 "Advansea" 579 "KVH" 580 "San Jose Technology" 583 "Yacht Control" 586 "Suzuki Motor" 591 "US Coast Guard" 595 "Ship Module aka Customware" 600 "Aquatic AV" 605 "Aventics" 606 "Intellian" 612 "SamwonIT" 614 "Arlt Tecnologies" 637 "Bavaria Yachts" 641 "Diverse Yacht Services" 644 "Wema U.S.A dba KUS" 658 "Shenzhen Jiuzhou Himunication" 688 "Rockford" 699 "Harman International" 704 "JL Audio" 708 "Lars Thrane" 715 "Autonnic" 717 "Yacht Devices" 734 "REAP Systems" 735 "AEM Performance Electronics" 739 "LxNav" 741 "Littelfuse, Inc (formerly Carling Technologies)" 743 "DaeMyung" 744 "Woosung" 748 "ISOTTA IFRA srl" 773 "Clarion US" 776 "HMI Systems" 777 "Ocean Signal" 778 "Seakeeper" 781 "Poly Planar" 785 "Fischer Panda DE" 795 "Broyda Industries" 796 "Canadian Automotive" 797 "Tides Marine" 798 "Lumishore" 799 "Still Water Designs and Audio" 802 "BJ Technologies (Beneteau)" 803 "Gill Sensors" 811 "Blue Water Desalination" 815 "FLIR" 824 "Undheim Systems" 826 "Lewmar" 838 "TeamSurv" 844 "Fell Marine" 847 "Oceanvolt" 862 "Prospec" 868 "Data Panel" 890 "L3 Technologies" 894 "Rhodan Marine Systems" 896 "Nexfour Solutions" 905 "ASA Electronics" 909 "Marines Co (South Korea)" 911 "Nautic-on" 917 "Sentinel" 929 "JL Marine Systems" 930 "Ecotronix" 944 "Zontisa Marine" 951 "EXOR International" 962 "Timbolier Industries" 963 "TJC Micro" 968 "Cox Powertrain" 969 "Blue Seas" 981 "Kobelt Manufacturing" 992 "Blue Ocean IOT" 997 "Xenta Systems" 999 "Signal K" 1004 "Ultraflex" 1008 "Lintest SmartBoat" 1011 "Soundmax" 1020 "Team Italia Marine (Onyx Marine Automation s.r.l)" 1021 "Entratech" 1022 "ITC" 1029 "The Marine Guardian" 1047 "Sonic" 1051 "ProNav" 1053 "Vetus Maxwell INC." 1056 "Lithium Pros" 1059 "Boatrax" 1062 "Marol Co ltd" 1065 "CALYPSO Instruments" 1066 "Spot Zero Water" 1069 "Lithionics Battery" 1070 "Quick-teck Electronics" 1075 "Uniden America" 1083 "Nauticoncept" 1084 "Shadow-Caster LED lighting" 1085 "Wet Sounds" 1088 "E-T-A Circuit Breakers" 1092 "Scheiber" 1100 "Smart Yachts International Limited" 1109 "Dockmate" 1114 "Bobs Machine" 1118 "L3Harris ASV" 1119 "Balmar" 1120 "Elettromedia" 1127 "Electromaax" 1140 "Across Oceans Systems" 1145 "Kiwi Yachting" 1150 "BSB Artificial Intelligence" 1151 "Orca Technologies" 1154 "TBS Electronics" 1158 "Technoton Electroics" 1160 "MG Energy Systems" 1169 "Sea Machine Robotics" 1171 "Vista Manufacturing" 1183 "Zipwake" 1186 "Sailmon" 1192 "Airmoniq Pro Kft" 1194 "Sierra Marine" 1200 "Xinuo Information Technology (Xiamen)" 1218 "Septentrio" 1233 "NKE Marine Electronics" 1238 "SuperTrack Aps" 1239 "Honda Electronics" 1245 "Raritan Engineering" 1249 "Integrated Power Solutions AG" 1260 "Interactive Technologies" 1283 "LTG-Tech" 1299 "Energy Solutions (UK)" 1300 "WATT Fuel Cell" 1302 "Pro Mainer" 1305 "Dragonfly Energy" 1306 "Koden Electronics" 1311 "Humphree" 1316 "Hinkley Yachts" 1317 "Global Marine Management GmbH (GMM)" 1320 "Triskel Marine" 1330 "Warwick Control Technologies" 1331 "Dolphin Charger" 1337 "Barnacle Systems" 1348 "Radian IoT" 1353 "Ocean LED Marine" 1359 "BluNav" 1361 "OVA (Nantong Saiyang Electronics Co., Ltd)" 1368 "RAD Propulsion" 1369 "Electric Yacht" 1372 "Elco Motor Yachts" 1384 "Tecnoseal Foundry S.r.l" 1385 "Pro Charging Systems" 1389 "EVEX" 1398 "Gobius Sensor Technology" 1403 "Arco Marine" 1408 "Lenco Marine" 1413 "Naocontrol" 1417 "Revatek" 1438 "Aeolionics" 1439 "PredictWind" 1440 "Egis Mobile Electric" 1445 "Starboard Yacht Group" 1446 "Roswell Marine" 1451 "ePropulsion (Guangdong ePropulsion Technology Ltd.)" 1452 "Micro-Air" 1453 "Vital Battery" 1458 "Ride Controller" 1460 "Tocaro Blue" 1461 "Vanquish Yachts" 1471 "FT Technologies" 1478 "Alps Alpine" 1481 "E-Force Marine" 1482 "CMC Marine" 1483 "Nanjing Sandemarine Information Technology" 1850 "Teleflex Marine (SeaStar Solutions)" 1851 "Raymarine" 1852 "Navionics" 1853 "Japan Radio" 1854 "Northstar Technologies" 1855 "Furuno" 1856 "Trimble" 1857 "Simrad" 1858 "Litton" 1859 "Kvasar" 1860 "MMP" 1861 "Vector Cantech" 1862 "Yamaha Marine" 1863 "Faria Instruments" ;
VAL_ 2566853120 Industry_Code 0 "Global" 1 "Highway" 2 "Agriculture" 3 "Construction" 4 "Marine Industry" 5 "Industrial" ;
VAL_ 2566853376 Manufacturer_Code 69 "ARKS Enterprises" 78 "FW Murphy/Enovation Controls" 80 "Twin Disc" 85 "Kohler Power Systems" 88 "Hemisphere GPS" 135 "Airmar" 137 "Maretron" 140 "Lowrance" 144 "Mercury Marine" 147 "Nautibus Electronic" 148 "Blue Water Data" 154 "Westerbeke" 157 "ISSPRO" 161 "Offshore Systems (UK)" 163 "Evinrude/BRP" 165 "CPAC Systems" 168 "Xantrex Technology" 169 "Marlin Technologies" 172 "Yanmar Marine" 174 "Volvo Penta" 176 "Carling Technologies Inc. (Moritz Aerospace)" 185 "Beede Instruments" 192 "Floscan Instrument" 193 "Nobeltec" 198 "Mystic Valley Communications" 199 "Actia" 201 "Disenos Y Technologia" 211 "Digital Switching Systems" 215 "Xintex/Atena" 224 "EMMI NETWORK" 228 "ZF" 229 "Garmin" 233 "Yacht Monitoring Solutions" 235 "Sailormade Marine Telemetry/Tetra Technology" 243 "Eride" 257 "Honda Motor" 272 "Groco" 273 "Actisense" 274 "Amphenol LTW Technology" 275 "Navico" 283 "Hamilton Jet" 285 "Sea Recovery" 286 "Coelmo SRL Italy" 295 "BEP Marine" 304 "Empir Bus" 305 "NovAtel" 306 "Sleipner Motor" 307 "MBW Technologies" 315 "ICOM" 328 "Qwerty" 329 "Dief" 341 "Boening Automationstechnologie" 345 "Korean Maritime University" 351 "Thrane and Thrane" 355 "Mastervolt" 356 "Fischer Panda Generators" 358 "Victron Energy" 370 "Rolls Royce Marine" 373 "Electronic Design" 374 "Northern Lights" 378 "Glendinning" 381 "B & G" 384 "Rose Point Navigation Systems" 385 "Johnson Outdoors Marine Electronics Inc Geonav" 394 "Capi 2" 396 "Beyond Measure" 400 "Livorsi Marine" 404 "ComNav" 409 "Chetco" 419 "Fusion Electronics" 421 "Standard Horizon" 422 "True Heading" 426 "Egersund Marine Electronics" 427 "em-trak Marine Electronics" 431 "Tohatsu Co, JP" 437 "Digital Yacht" 438 "Comar Systems Limited" 440 "Cummins" 443 "VDO (aka Continental-Corporation)" 451 "Parker Hannifin aka Village Marine Tech" 459 "Alltek Marine Electronics" 460 "SAN GIORGIO S.E.I.N" 466 "Veethree Electronics & Marine" 470 "SI-TEX Marine Electronics" 471 "Sea Cross Marine" 475 "GME aka Standard Communications" 476 "Humminbird Marine Electronics" 478 "Ocean Sat" 481 "Chetco Digital Instruments" 493 "Watcheye" 499 "Lcj Capteurs" 502 "Attwood Marine" 503 "Naviop S.R.L." 504 "Vesper Marine" 510 "Marinesoft" 513 "Simarine" 517 "NoLand Engineering" 518 "Transas USA" 529 "National Instruments Korea" 530 "National Marine Electronics Association" 532 "Onwa Marine" 540 "Webasto" 571 "Marinecraft (South Korea)" 573 "McMurdo Group aka Orolia" 578 "Advansea" 579 "KVH" 580 "San Jose Technology" 583 "Yacht Control" 586 "Suzuki Motor" 591 "US Coast Guard" 595 "Ship Module aka Customware" 600 "Aquatic AV" 605 "Aventics" 606 "Intellian" 612 "SamwonIT" 614 "Arlt Tecnologies" 637 "Bavaria Yachts" 641 "Diverse Yacht Services" 644 "Wema U.S.A dba KUS" 658 "Shenzhen Jiuzhou Himunication" 688 "Rockford" 699 "Harman International" 704 "JL Audio" 708 "Lars Thrane" 715 "Autonnic" 717 "Yacht Devices" 734 "REAP Systems" 735 "AEM Performance Electronics" 739 "LxNav" 741 "Littelfuse, Inc (formerly Carling Technologies)" 743 "DaeMyung" 744 "Woosung" 748 "ISOTTA IFRA srl" 773 "Clarion US" 776 "HMI Systems" 777 "Ocean Signal" 778 "Seakeeper" 781 "Poly Planar" 785 "Fischer Panda DE" 795 "Broyda Industries" 796 "Canadian Automotive" 797 "Tides Marine" 798 "Lumishore" 799 "Still Water Designs and Audio" 802 "BJ Technologies (Beneteau)" 803 "Gill Sensors" 811 "Blue Water Desalination" 815 "FLIR" 824 "Undheim Systems" 826 "Lewmar" 838 "TeamSurv" 844 "Fell Marine" 847 "Oceanvolt" 862 "Prospec" 868 "Data Panel" 890 "L3 Technologies" 894 "Rhodan Marine Systems" 896 "Nexfour Solutions" 905 "ASA Electronics" 909 "Marines Co (South Korea)" 911 "Nautic-on" 917 "Sentinel" 929 "JL Marine Systems" 930 "Ecotronix" 944 "Zontisa Marine" 951 "EXOR International" 962 "Timbolier Industries" 963 "TJC Micro" 968 "Cox Powertrain" 969 "Blue Seas" 981 "Kobelt Manufacturing" 992 "Blue Ocean IOT" 997 "Xenta Systems" 999 "Signal K" 1004 "Ultraflex" 1008 "Lintest SmartBoat" 1011 "Soundmax" 1020 "Team Italia Marine (Onyx Marine Automation s.r.l)" 1021 "Entratech" 1022 "ITC" 1029 "The Marine Guardian" 1047 "Sonic" 1051 "ProNav" 1053 "Vetus Maxwell INC." 1056 "Lithium Pros" 1059 "Boatrax" 1062 "Marol Co ltd" 1065 "CALYPSO Instruments" 1066 "Spot Zero Water" 1069 "Lithionics Battery" 1070 "Quick-teck Electronics" 1075 "Uniden America" 1083 "Nauticoncept" 1084 "Shadow-Caster LED lighting" 1085 "Wet Sounds" 1088 "E-T-A Circuit Breakers" 1092 "Scheiber" 1100 "Smart Yachts International Limited" 1109 "Dockmate" 1114 "Bobs Machine" 1118 "L3Harris ASV" 1119 "Balmar" 1120 "Elettromedia" 1127 "Electromaax" 1140 "Across Oceans Systems" 1145 "Kiwi Yachting" 1150 "BSB Artificial Intelligence" 1151 "Orca Technologies" 1154 "TBS Electronics" 1158 "Technoton Electroics" 1160 "MG Energy Systems" 1169 "Sea Machine Robotics" 1171 "Vista Manufacturing" 1183 "Zipwake" 1186 "Sailmon" 1192 "Airmoniq Pro Kft" 1194 "Sierra Marine" 1200 "Xinuo Information Technology (Xiamen)" 1218 "Septentrio" 1233 "NKE Marine Electronics" 1238 "SuperTrack Aps" 1239 "Honda Electronics" 1245 "Raritan Engineering" 1249 "Integrated Power Solutions AG" 1260 "Interactive Technologies" 1283 "LTG-Tech" 1299 "Energy Solutions (UK)" 1300 "WATT Fuel Cell" 1302 "Pro Mainer" 1305 "Dragonfly Energy" 1306 "Koden Electronics" 1311 "Humphree" 1316 "Hinkley Yachts" 1317 "Global Marine Management GmbH (GMM)" 1320 "Triskel Marine" 1330 "Warwick Control Technologies" 1331 "Dolphin Charger" 1337 "Barnacle Systems" 1348 "Radian IoT" 1353 "Ocean LED Marine" 1359 "BluNav" 1361 "OVA (Nantong Saiyang Electronics Co., Ltd)" 1368 "RAD Propulsion" 1369 "Electric Yacht" 1372 "Elco Motor Yachts" 1384 "Tecnoseal Foundry S.r.l" 1385 "Pro Charging Systems" 1389 "EVEX" 1398 "Gobius Sensor Technology" 1403 "Arco Marine" 1408 "Lenco Marine" 1413 "Naocontrol" 1417 "Revatek" 1438 "Aeolionics" 1439 "PredictWind" 1440 "Egis Mobile Electric" 1445 "Starboard Yacht Group" 1446 "Roswell Marine" 1451 "ePropulsion (Guangdong ePropulsion Technology Ltd.)" 1452 "Micro-Air" 1453 "Vital Battery" 1458 "Ride Controller" 1460 "Tocaro Blue" 1461 "Vanquish Yachts" 1471 "FT Technologies" 1478 "Alps Alpine" 1481 "E-Force Marine" 1482 "CMC Marine" 1483 "Nanjing Sandemarine Information Technology" 1850 "Teleflex Marine (SeaStar Solutions)" 1851 "Raymarine" 1852 "Navionics" 1853 "Japan Radio" 1854 "Northstar Technologies" 1855 "Furuno" 1856 "Trimble" 1857 "Simrad" 1858 "Litton" 1859 "Kvasar" 1860 "MMP" 1861 "Vector Cantech" 1862 "Yamaha Marine" 1863 "Faria Instruments" ;
VAL_ 2566853376 Industry_Code 0 "Global" 1 "Highway" 2 "Agriculture" 3 "Construction" 4 "Marine Industry" 5 "Industrial" ;
VAL_ 2566853376 Manufacturer_Code 69 "ARKS Enterprises" 78 "FW Murphy/Enovation Controls" 80 "Twin Disc" 85 "Kohler Power Systems" 88 "Hemisphere GPS" 135 "Airmar" 137 "Maretron" 140 "Lowrance" 144 "Mercury Marine" 147 "Nautibus Electronic" 148 "Blue Water Data" 154 "Westerbeke" 157 "ISSPRO" 161 "Offshore Systems (UK)" 163 "Evinrude/BRP" 165 "CPAC Systems" 168 "Xantrex Technology" 169 "Marlin Technologies" 172 "Yanmar Marine" 174 "Volvo Penta" 176 "Carling Technologies Inc. (Moritz Aerospace)" 185 "Beede Instruments" 192 "Floscan Instrument" 193 "Nobeltec" 198 "Mystic Valley Communications" 199 "Actia" 201 "Disenos Y Technologia" 211 "Digital Switching Systems" 215 "Xintex/Atena" 224 "EMMI NETWORK" 228 "ZF" 229 "Garmin" 233 "Yacht Monitoring Solutions" 235 "Sailormade Marine Telemetry/Tetra Technology" 243 "Eride" 257 "Honda Motor" 272 "Groco" 273 "Actisense" 274 "Amphenol LTW Technology" 275 "Navico" 283 "Hamilton Jet" 285 "Sea Recovery" 286 "Coelmo SRL Italy" 295 "BEP Marine" 304 "Empir Bus" 305 "NovAtel" 306 "Sleipner Motor" 307 "MBW Technologies" 315 "ICOM" 328 "Qwerty" 329 "Dief" 341 "Boening Automationstechnologie" 345 "Korean Maritime University" 351 "Thrane and Thrane" 355 "Mastervolt" 356 "Fischer Panda Generators" 358 "Victron Energy" 370 "Rolls Royce Marine" 373 "Electronic Design" 374 "Northern Lights" 378 "Glendinning" 381 "B & G" 384 "Rose Point Navigation Systems" 385 "Johnson Outdoors Marine Electronics Inc Geonav" 394 "Capi 2" 396 "Beyond Measure" 400 "Livorsi Marine" 404 "ComNav" 409 "Chetco" 419 "Fusion Electronics" 421 "Standard Horizon" 422 "True Heading" 426 "Egersund Marine Electronics" 427 "em-trak Marine Electronics" 431 "Tohatsu Co, JP" 437 "Digital Yacht" 438 "Comar Systems Limited" 440 "Cummins" 443 "VDO (aka Continental-Corporation)" 451 "Parker Hannifin aka Village Marine Tech" 459 "Alltek Marine Electronics" 460 "SAN GIORGIO S.E.I.N" 466 "Veethree Electronics & Marine" 470 "SI-TEX Marine Electronics" 471 "Sea Cross Marine" 475 "GME aka Standard Communications" 476 "Humminbird Marine Electronics" 478 "Ocean Sat" 481 "Chetco Digital Instruments" 493 "Watcheye" 499 "Lcj Capteurs" 502 "Attwood Marine" 503 "Naviop S.R.L." 504 "Vesper Marine" 510 "Marinesoft" 513 "Simarine" 517 "NoLand Engineering" 518 "Transas USA" 529 "National Instruments Korea" 530 "National Marine Electronics Association" 532 "Onwa Marine" 540 "Webasto" 571 "Marinecraft (South Korea)" 573 "McMurdo Group aka Orolia" 578 "Advansea" 579 "KVH" 580 "San Jose Technology" 583 "Yacht Control" 586 "Suzuki Motor" 591 "US Coast Guard" 595 "Ship Module aka Customware" 600 "Aquatic AV" 605 "Aventics" 606 "Intellian" 612 "SamwonIT" 614 "Arlt Tecnologies" 637 "Bavaria Yachts" 641 "Diverse Yacht Services" 644 "Wema U.S.A dba KUS" 658 "Shenzhen Jiuzhou Himunication" 688 "Rockford" 699 "Harman International" 704 "JL Audio" 708 "Lars Thrane" 715 "Autonnic" 717 "Yacht Devices" 734 "REAP Systems" 735 "AEM Performance Electronics" 739 "LxNav" 741 "Littelfuse, Inc (formerly Carling Technologies)" 743 "DaeMyung" 744 "Woosung" 748 "ISOTTA IFRA srl" 773 "Clarion US" 776 "HMI Systems" 777 "Ocean Signal" 778 "Seakeeper" 781 "Poly Planar" 785 "Fischer Panda DE" 795 "Broyda Industries" 796 "Canadian Automotive" 797 "Tides Marine" 798 "Lumishore" 799 "Still Water Designs and Audio" 802 "BJ Technologies (Beneteau)" 803 "Gill Sensors" 811 "Blue Water Desalination" 815 "FLIR" 824 "Undheim Systems" 826 "Lewmar" 838 "TeamSurv" 844 "Fell Marine" 847 "Oceanvolt" 862 "Prospec" 868 "Data Panel" 890 "L3 Technologies" 894 "Rhodan Marine Systems" 896 "Nexfour Solutions" 905 "ASA Electronics" 909 "Marines Co (South Korea)" 911 "Nautic-on" 917 "Sentinel" 929 "JL Marine Systems" 930 "Ecotronix" 944 "Zontisa Marine" 951 "EXOR International" 962 "Timbolier Industries" 963 "TJC Micro" 968 "Cox Powertrain" 969 "Blue Seas" 981 "Kobelt Manufacturing" 992 "Blue Ocean IOT" 997 "Xenta Systems" 999 "Signal K" 1004 "Ultraflex" 1008 "Lintest SmartBoat" 1011 "Soundmax" 1020 "Team Italia Marine (Onyx Marine Automation s.r.l)" 1021 "Entratech" 1022 "ITC" 1029 "The Marine Guardian" 1047 "Sonic" 1051 "ProNav" 1053 "Vetus Maxwell INC." 1056 "Lithium Pros" 1059 "Boatrax" 1062 "Marol Co ltd" 1065 "CALYPSO Instruments" 1066 "Spot Zero Water" 1069 "Lithionics Battery" 1070 "Quick-teck Electronics" 1075 "Uniden America" 1083 "Nauticoncept" 1084 "Shadow-Caster LED lighting" 1085 "Wet Sounds" 1088 "E-T-A Circuit Breakers" 1092 "Scheiber" 1100 "Smart Yachts International Limited" 1109 "Dockmate" 1114 "Bobs Machine" 1118 "L3Harris ASV" 1119 "Balmar" 1120 "Elettromedia" 1127 "Electromaax" 1140 "Across Oceans Systems" 1145 "Kiwi Yachting" 1150 "BSB Artificial Intelligence" 1151 "Orca Technologies" 1154 "TBS Electronics" 1158 "Technoton Electroics" 1160 "MG Energy Systems" 1169 "Sea Machine Robotics" 1171 "Vista Manufacturing" 1183 "Zipwake" 1186 "Sailmon" 1192 "Airmoniq Pro Kft" 1194 "Sierra Marine" 1200 "Xinuo Information Technology (Xiamen)" 1218 "Septentrio" 1233 "NKE Marine Electronics" 1238 "SuperTrack Aps" 1239 "Honda Electronics" 1245 "Raritan Engineering" 1249 "Integrated Power Solutions AG" 1260 "Interactive Technologies" 1283 "LTG-Tech" 1299 "Energy Solutions (UK)" 1300 "WATT Fuel Cell" 1302 "Pro Mainer" 1305 "Dragonfly Energy" 1306 "Koden Electronics" 1311 "Humphree" 1316 "Hinkley Yachts" 1317 "Global Marine Management GmbH (GMM)" 1320 "Triskel Marine" 1330 "Warwick Control Technologies" 1331 "Dolphin Charger" 1337 "Barnacle Systems" 1348 "Radian IoT" 1353 "Ocean LED Marine" 1359 "BluNav" 1361 "OVA (Nantong Saiyang Electronics Co., Ltd)" 1368 "RAD Propulsion" 1369 "Electric Yacht" 1372 "Elco Motor Yachts" 1384 "Tecnoseal Foundry S.r.l" 1385 "Pro Charging Systems" 1389 "EVEX" 1398 "Gobius Sensor Technology" 1403 "Arco Marine" 1408 "Lenco Marine" 1413 "Naocontrol" 1417 "Revatek" 1438 "Aeolionics" 1439 "PredictWind" 1440 "Egis Mobile Electric" 1445 "Starboard Yacht Group" 1446 "Roswell Marine" 1451 "ePropulsion (Guangdong ePropulsion Technology Ltd.)" 1452 "Micro-Air" 1453 "Vital Battery" 1458 "Ride Controller" 1460 "Tocaro Blue" 1461 "Vanquish Yachts" 1471 "FT Technologies" 1478 "Alps Alpine" 1481 "E-Force Marine" 1482 "CMC Marine" 1483 "Nanjing Sandemarine Information Technology" 1850 "Teleflex Marine (SeaStar Solutions)" 1851 "Raymarine" 1852 "Navionics" 1853 "Japan Radio" 1854 "Northstar Technologies" 1855 "Furuno" 1856 "Trimble" 1857 "Simrad" 1858 "Litton" 1859 "Kvasar" 1860 "MMP" 1861 "Vector Cantech" 1862 "Yamaha Marine" 1863 "Faria Instruments" ;
VAL_ 2566853376 Industry_Code 0 "Global" 1 "Highway" 2 "Agriculture" 3 "Construction" 4 "Marine Industry" 5 "Industrial" ;
VAL_ 2566853632 Manufacturer_Code 69 "ARKS Enterprises" 78 "FW Murphy/Enovation Controls" 80 "Twin Disc" 85 "Kohler Power Systems" 88 "Hemisphere GPS" 135 "Airmar" 137 "Maretron" 140 "Lowrance" 144 "Mercury Marine" 147 "Nautibus Electronic" 148 "Blue Water Data" 154 "Westerbeke" 157 "ISSPRO" 161 "Offshore Systems (UK)" 163 "Evinrude/BRP" 165 "CPAC Systems" 168 "Xantrex Technology" 169 "Marlin Technologies" 172 "Yanmar Marine" 174 "Volvo Penta" 176 "Carling Technologies Inc. (Moritz Aerospace)" 185 "Beede Instruments" 192 "Floscan Instrument" 193 "Nobeltec" 198 "Mystic Valley Communications" 199 "Actia" 201 "Disenos Y Technologia" 211 "Digital Switching Systems" 215 "Xintex/Atena" 224 "EMMI NETWORK" 228 "ZF" 229 "Garmin" 233 "Yacht Monitoring Solutions" 235 "Sailormade Marine Telemetry/Tetra Technology" 243 "Eride" 257 "Honda Motor" 272 "Groco" 273 "Actisense" 274 "Amphenol LTW Technology" 275 "Navico" 283 "Hamilton Jet" 285 "Sea Recovery" 286 "Coelmo SRL Italy" 295 "BEP Marine" 304 "Empir Bus" 305 "NovAtel" 306 "Sleipner Motor" 307 "MBW Technologies" 315 "ICOM" 328 "Qwerty" 329 "Dief" 341 "Boening Automationstechnologie" 345 "Korean Maritime University" 351 "Thrane and Thrane" 355 "Mastervolt" 356 "Fischer Panda Generators" 358 "Victron Energy" 370 "Rolls Royce Marine" 373 "Electronic Design" 374 "Northern Lights" 378 "Glendinning" 381 "B & G" 384 "Rose Point Navigation Systems" 385 "Johnson Outdoors Marine Electronics Inc Geonav" 394 "Capi 2" 396 "Beyond Measure" 400 "Livorsi Marine" 404 "ComNav" 409 "Chetco" 419 "Fusion Electronics" 421 "Standard Horizon" 422 "True Heading" 426 "Egersund Marine Electronics" 427 "em-trak Marine Electronics" 431 "Tohatsu Co, JP" 437 "Digital Yacht" 438 "Comar Systems Limited" 440 "Cummins" 443 "VDO (aka Continental-Corporation)" 451 "Parker Hannifin aka Village Marine Tech" 459 "Alltek Marine Electronics" 460 "SAN GIORGIO S.E.I.N" 466 "Veethree Electronics & Marine" 470 "SI-TEX Marine Electronics" 471 "Sea Cross Marine" 475 "GME aka Standard Communications" 476 "Humminbird Marine Electronics" 478 "Ocean Sat" 481 "Chetco Digital Instruments" 493 "Watcheye" 499 "Lcj Capteurs" 502 "Attwood Marine" 503 "Naviop S.R.L." 504 "Vesper Marine" 510 "Marinesoft" 513 "Simarine" 517 "NoLand Engineering" 518 "Transas USA" 529 "National Instruments Korea" 530 "National Marine Electronics Association" 532 "Onwa Marine" 540 "Webasto" 571 "Marinecraft (South Korea)" 573 "McMurdo Group aka Orolia" 578 "Advansea" 579 "KVH" 580 "San Jose Technology" 583 "Yacht Control" 586 "Suzuki Motor" 591 "US Coast Guard" 595 "Ship Module aka Customware" 600 "Aquatic AV" 605 "Aventics" 606 "Intellian" 612 "SamwonIT" 614 "Arlt Tecnologies" 637 "Bavaria Yachts" 641 "Diverse Yacht Services" 644 "Wema U.S.A dba KUS" 658 "Shenzhen Jiuzhou Himunication" 688 "Rockford" 699 "Harman International" 704 "JL Audio" 708 "Lars Thrane" 715 "Autonnic" 717 "Yacht Devices" 734 "REAP Systems" 735 "AEM Performance Electronics" 739 "LxNav" 741 "Littelfuse, Inc (formerly Carling Technologies)" 743 "DaeMyung" 744 "Woosung" 748 "ISOTTA IFRA srl" 773 "Clarion US" 776 "HMI Systems" 777 "Ocean Signal" 778 "Seakeeper" 781 "Poly Planar" 785 "Fischer Panda DE" 795 "Broyda Industries" 796 "Canadian Automotive" 797 "Tides Marine" 798 "Lumishore" 799 "Still Water Designs and Audio" 802 "BJ Technologies (Beneteau)" 803 "Gill Sensors" 811 "Blue Water Desalination" 815 "FLIR" 824 "Undheim Systems" 826 "Lewmar" 838 "TeamSurv" 844 "Fell Marine" 847 "Oceanvolt" 862 "Prospec" 868 "Data Panel" 890 "L3 Technologies" 894 "Rhodan Marine Systems" 896 "Nexfour Solutions" 905 "ASA Electronics" 909 "Marines Co (South Korea)" 911 "Nautic-on" 917 "Sentinel" 929 "JL Marine Systems" 930 "Ecotronix" 944 "Zontisa Marine" 951 "EXOR International" 962 "Timbolier Industries" 963 "TJC Micro" 968 "Cox Powertrain" 969 "Blue Seas" 981 "Kobelt Manufacturing" 992 "Blue Ocean IOT" 997 "Xenta Systems" 999 "Signal K" 1004 "Ultraflex" 1008 "Lintest SmartBoat" 1011 "Soundmax" 1020 "Team Italia Marine (Onyx Marine Automation s.r.l)" 1021 "Entratech" 1022 "ITC" 1029 "The Marine Guardian" 1047 "Sonic" 1051 "ProNav" 1053 "Vetus Maxwell INC." 1056 "Lithium Pros" 1059 "Boatrax" 1062 "Marol Co ltd" 1065 "CALYPSO Instruments" 1066 "Spot Zero Water" 1069 "Lithionics Battery" 1070 "Quick-teck Electronics" 1075 "Uniden America" 1083 "Nauticoncept" 1084 "Shadow-Caster LED lighting" 1085 "Wet Sounds" 1088 "E-T-A Circuit Breakers" 1092 "Scheiber" 1100 "Smart Yachts International Limited" 1109 "Dockmate" 1114 "Bobs Machine" 1118 "L3Harris ASV" 1119 "Balmar" 1120 "Elettromedia" 1127 "Electromaax" 1140 "Across Oceans Systems" 1145 "Kiwi Yachting" 1150 "BSB Artificial Intelligence" 1151 "Orca Technologies" 1154 "TBS Electronics" 1158 "Technoton Electroics" 1160 "MG Energy Systems" 1169 "Sea Machine Robotics" 1171 "Vista Manufacturing" 1183 "Zipwake" 1186 "Sailmon" 1192 "Airmoniq Pro Kft" 1194 "Sierra Marine" 1200 "Xinuo Information Technology (Xiamen)" 1218 "Septentrio" 1233 "NKE Marine Electronics" 1238 "SuperTrack Aps" 1239 "Honda Electronics" 1245 "Raritan Engineering" 1249 "Integrated Power Solutions AG" 1260 "Interactive Technologies" 1283 "LTG-Tech" 1299 "Energy Solutions (UK)" 1300 "WATT Fuel Cell" 1302 "Pro Mainer" 1305 "Dragonfly Energy" 1306 "Koden Electronics" 1311 "Humphree" 1316 "Hinkley Yachts" 1317 "Global Marine Management GmbH (GMM)" 1320 "Triskel Marine" 1330 "Warwick Control Technologies" 1331 "Dolphin Charger" 1337 "Barnacle Systems" 1348 "Radian IoT" 1353 "Ocean LED Marine" 1359 "BluNav" 1361 "OVA (Nantong Saiyang Electronics Co., Ltd)" 1368 "RAD Propulsion" 1369 "Electric Yacht" 1372 "Elco Motor Yachts" 1384 "Tecnoseal Foundry S.r.l" 1385 "Pro Charging Systems" 1389 "EVEX" 1398 "Gobius Sensor Technology" 1403 "Arco Marine" 1408 "Lenco Marine" 1413 "Naocontrol" 1417 "Revatek" 1438 "Aeolionics" 1439 "PredictWind" 1440 "Egis Mobile Electric" 1445 "Starboard Yacht Group" 1446 "Roswell Marine" 1451 "ePropulsion (Guangdong ePropulsion Technology Ltd.)" 1452 "Micro-Air" 1453 "Vital Battery" 1458 "Ride Controller" 1460 "Tocaro Blue" 1461 "Vanquish Yachts" 1471 "FT Technologies" 1478 "Alps Alpine" 1481 "E-Force Marine" 1482 "CMC Marine" 1483 "Nanjing Sandemarine Information Technology" 1850 "Teleflex Marine (SeaStar Solutions)" 1851 "Raymarine" 1852 "Navionics" 1853 "Japan Radio" 1854 "Northstar Technologies" 1855 "Furuno" 1856 "Trimble" 1857 "Simrad" 1858 "Litton" 1859 "Kvasar" 1860 "MMP" 1861 "Vector Cantech" 1862 "Yamaha Marine" 1863 "Faria Instruments" ;
VAL_ 2566853632 Industry_Code 0 "Global" 1 "Highway" 2 "Agriculture" 3 "Construction" 4 "Marine Industry" 5 "Industrial" ;
VAL_ 2566853632 Manufacturer_Code 69 "ARKS Enterprises" 78 "FW Murphy/Enovation Controls" 80 "Twin Disc" 85 "Kohler Power Systems" 88 "Hemisphere GPS" 135 "Airmar" 137 "Maretron" 140 "Lowrance" 144 "Mercury Marine" 147 "Nautibus Electronic" 148 "Blue Water Data" 154 "Westerbeke" 157 "ISSPRO" 161 "Offshore Systems (UK)" 163 "Evinrude/BRP" 165 "CPAC Systems" 168 "Xantrex Technology" 169 "Marlin Technologies" 172 "Yanmar Marine" 174 "Volvo Penta" 176 "Carling Technologies Inc. (Moritz Aerospace)" 185 "Beede Instruments" 192 "Floscan Instrument" 193 "Nobeltec" 198 "Mystic Valley Communications" 199 "Actia" 201 "Disenos Y Technologia" 211 "Digital Switching Systems" 215 "Xintex/Atena" 224 "EMMI NETWORK" 228 "ZF" 229 "Garmin" 233 "Yacht Monitoring Solutions" 235 "Sailormade Marine Telemetry/Tetra Technology" 243 "Eride" 257 "Honda Motor" 272 "Groco" 273 "Actisense" 274 "Amphenol LTW Technology" 275 "Navico" 283 "Hamilton Jet" 285 "Sea Recovery" 286 "Coelmo SRL Italy" 295 "BEP Marine" 304 "Empir Bus" 305 "NovAtel" 306 "Sleipner Motor" 307 "MBW Technologies" 315 "ICOM" 328 "Qwerty" 329 "Dief" 341 "Boening Automationstechnologie" 345 "Korean Maritime University" 351 "Thrane and Thrane" 355 "Mastervolt" 356 "Fischer Panda Generators" 358 "Victron Energy" 370 "Rolls Royce Marine" 373 "Electronic Design" 374 "Northern Lights" 378 "Glendinning" 381 "B & G" 384 "Rose Point Navigation Systems" 385 "Johnson Outdoors Marine Electronics Inc Geonav" 394 "Capi 2" 396 "Beyond Measure" 400 "Livorsi Marine" 404 "ComNav" 409 "Chetco" 419 "Fusion Electronics" 421 "Standard Horizon" 422 "True Heading" 426 "Egersund Marine Electronics" 427 "em-trak Marine Electronics" 431 "Tohatsu Co, JP" 437 "Digital Yacht" 438 "Comar Systems Limited" 440 "Cummins" 443 "VDO (aka Continental-Corporation)" 451 "Parker Hannifin aka Village Marine Tech" 459 "Alltek Marine Electronics" 460 "SAN GIORGIO S.E.I.N" 466 "Veethree Electronics & Marine" 470 "SI-TEX Marine Electronics" 471 "Sea Cross Marine" 475 "GME aka Standard Communications" 476 "Humminbird Marine Electronics" 478 "Ocean Sat" 481 "Chetco Digital Instruments" 493 "Watcheye" 499 "Lcj Capteurs" 502 "Attwood Marine" 503 "Naviop S.R.L." 504 "Vesper Marine" 510 "Marinesoft" 513 "Simarine" 517 "NoLand Engineering" 518 "Transas USA" 529 "National Instruments Korea" 530 "National Marine Electronics Association" 532 "Onwa Marine" 540 "Webasto" 571 "Marinecraft (South Korea)" 573 "McMurdo Group aka Orolia" 578 "Advansea" 579 "KVH" 580 "San Jose Technology" 583 "Yacht Control" 586 "Suzuki Motor" 591 "US Coast Guard" 595 "Ship Module aka Customware" 600 "Aquatic AV" 605 "Aventics" 606 "Intellian" 612 "SamwonIT" 614 "Arlt Tecnologies" 637 "Bavaria Yachts" 641 "Diverse Yacht Services" 644 "Wema U.S.A dba KUS" 658 "Shenzhen Jiuzhou Himunication" 688 "Rockford" 699 "Harman International" 704 "JL Audio" 708 "Lars Thrane" 715 "Autonnic" 717 "Yacht Devices" 734 "REAP Systems" 735 "AEM Performance Electronics" 739 "LxNav" 741 "Littelfuse, Inc (formerly Carling Technologies)" 743 "DaeMyung" 744 "Woosung" 748 "ISOTTA IFRA srl" 773 "Clarion US" 776 "HMI Systems" 777 "Ocean Signal" 778 "Seakeeper" 781 "Poly Planar" 785 "Fischer Panda DE" 795 "Broyda Industries" 796 "Canadian Automotive" 797 "Tides Marine" 798 "Lumishore" 799 "Still Water Designs and Audio" 802 "BJ Technologies (Beneteau)" 803 "Gill Sensors" 811 "Blue Water Desalination" 815 "FLIR" 824 "Undheim Systems" 826 "Lewmar" 838 "TeamSurv" 844 "Fell Marine" 847 "Oceanvolt" 862 "Prospec" 868 "Data Panel" 890 "L3 Technologies" 894 "Rhodan Marine Systems" 896 "Nexfour Solutions" 905 "ASA Electronics" 909 "Marines Co (South Korea)" 911 "Nautic-on" 917 "Sentinel" 929 "JL Marine Systems" 930 "Ecotronix" 944 "Zontisa Marine" 951 "EXOR International" 962 "Timbolier Industries" 963 "TJC Micro" 968 "Cox Powertrain" 969 "Blue Seas" 981 "Kobelt Manufacturing" 992 "Blue Ocean IOT" 997 "Xenta Systems" 999 "Signal K" 1004 "Ultraflex" 1008 "Lintest SmartBoat" 1011 "Soundmax" 1020 "Team Italia Marine (Onyx Marine Automation s.r.l)" 1021 "Entratech" 1022 "ITC" 1029 "The Marine Guardian" 1047 "Sonic" 1051 "ProNav" 1053 "Vetus Maxwell INC." 1056 "Lithium Pros" 1059 "Boatrax" 1062 "Marol Co ltd" 1065 "CALYPSO Instruments" 1066 "Spot Zero Water" 1069 "Lithionics Battery" 1070 "Quick-teck Electronics" 1075 "Uniden America" 1083 "Nauticoncept" 1084 "Shadow-Caster LED lighting" 1085 "Wet Sounds" 1088 "E-T-A Circuit Breakers" 1092 "Scheiber" 1100 "Smart Yachts International Limited" 1109 "Dockmate" 1114 "Bobs Machine" 1118 "L3Harris ASV" 1119 "Balmar" 1120 "Elettromedia" 1127 "Electromaax" 1140 "Across Oceans Systems" 1145 "Kiwi Yachting" 1150 "BSB Artificial Intelligence" 1151 "Orca Technologies" 1154 "TBS Electronics" 1158 "Technoton Electroics" 1160 "MG Energy Systems" 1169 "Sea Machine Robotics" 1171 "Vista Manufacturing" 1183 "Zipwake" 1186 "Sailmon" 1192 "Airmoniq Pro Kft" 1194 "Sierra Marine" 1200 "Xinuo Information Technology (Xiamen)" 1218 "Septentrio" 1233 "NKE Marine Electronics" 1238 "SuperTrack Aps" 1239 "Honda Electronics" 1245 "Raritan Engineering" 1249 "Integrated Power Solutions AG" 1260 "Interactive Technologies" 1283 "LTG-Tech" 1299 "Energy Solutions (UK)" 1300 "WATT Fuel Cell" 1302 "Pro Mainer" 1305 "Dragonfly Energy" 1306 "Koden Electronics" 1311 "Humphree" 1316 "Hinkley Yachts" 1317 "Global Marine Management GmbH (GMM)" 1320 "Triskel Marine" 1330 "Warwick Control Technologies" 1331 "Dolphin Charger" 1337 "Barnacle Systems" 1348 "Radian IoT" 1353 "Ocean LED Marine" 1359 "BluNav" 1361 "OVA (Nantong Saiyang Electronics Co., Ltd)" 1368 "RAD Propulsion" 1369 "Electric Yacht" 1372 "Elco Motor Yachts" 1384 "Tecnoseal Foundry S.r.l" 1385 "Pro Charging Systems" 1389 "EVEX" 1398 "Gobius Sensor Technology" 1403 "Arco Marine" 1408 "Lenco Marine" 1413 "Naocontrol" 1417 "Revatek" 1438 "Aeolionics" 1439 "PredictWind" 1440 "Egis Mobile Electric" 1445 "Starboard Yacht Group" 1446 "Roswell Marine" 1451 "ePropulsion (Guangdong ePropulsion Technology Ltd.)" 1452 "Micro-Air" 1453 "Vital Battery" 1458 "Ride Controller" 1460 "Tocaro Blue" 1461 "Vanquish Yachts" 1471 "FT Technologies" 1478 "Alps Alpine" 1481 "E-Force Marine" 1482 "CMC Marine" 1483 "Nanjing Sandemarine Information Technology" 1850 "Teleflex Marine (SeaStar Solutions)" 1851 "Raymarine" 1852 "Navionics" 1853 "Japan Radio" 1854 "Northstar Technologies" 1855 "Furuno" 1856 "Trimble" 1857 "Simrad" 1858 "Litton" 1859 "Kvasar" 1860 "MMP" 1861 "Vector Cantech" 1862 "Yamaha Marine" 1863 "Faria Instruments" ;
VAL_ 2566853632 Industry_Code 0 "Global" 1 "Highway" 2 "Agriculture" 3 "Construction" 4 "Marine Industry" 5 "Industrial" ;
VAL_ 2566853632 Manufacturer_Code 69 "ARKS Enterprises" 78 "FW Murphy/Enovation Controls" 80 "Twin Disc" 85 "Kohler Power Systems" 88 "Hemisphere GPS" 135 "Airmar" 137 "Maretron" 140 "Lowrance" 144 "Mercury Marine" 147 "Nautibus Electronic" 148 "Blue Water Data" 154 "Westerbeke" 157 "ISSPRO" 161 "Offshore Systems (UK)" 163 "Evinrude/BRP" 165 "CPAC Systems" 168 "Xantrex Technology" 169 "Marlin Technologies" 172 "Yanmar Marine" 174 "Volvo Penta" 176 "Carling Technologies Inc. (Moritz Aerospace)" 185 "Beede Instruments" 192 "Floscan Instrument" 193 "Nobeltec" 198 "Mystic Valley Communications" 199 "Actia" 201 "Disenos Y Technologia" 211 "Digital Switching Systems" 215 "Xintex/Atena" 224 "EMMI NETWORK" 228 "ZF" 229 "Garmin" 233 "Yacht Monitoring Solutions" 235 "Sailormade Marine Telemetry/Tetra Technology" 243 "Eride" 257 "Honda Motor" 272 "Groco" 273 "Actisense" 274 "Amphenol LTW Technology" 275 "Navico" 283 "Hamilton Jet" 285 "Sea Recovery" 286 "Coelmo SRL Italy" 295 "BEP Marine" 304 "Empir Bus" 305 "NovAtel" 306 "Sleipner Motor" 307 "MBW Technologies" 315 "ICOM" 328 "Qwerty" 329 "Dief" 341 "Boening Automationstechnologie" 345 "Korean Maritime University" 351 "Thrane and Thrane" 355 "Mastervolt" 356 "Fischer Panda Generators" 358 "Victron Energy" 370 "Rolls Royce Marine" 373 "Electronic Design" 374 "Northern Lights" 378 "Glendinning" 381 "B & G" 384 "Rose Point Navigation Systems" 385 "Johnson Outdoors Marine Electronics Inc Geonav" 394 "Capi 2" 396 "Beyond Measure" 400 "Livorsi Marine" 404 "ComNav" 409 "Chetco" 419 "Fusion Electronics" 421 "Standard Horizon" 422 "True Heading" 426 "Egersund Marine Electronics" 427 "em-trak Marine Electronics" 431 "Tohatsu Co, JP" 437 "Digital Yacht" 438 "Comar Systems Limited" 440 "Cummins" 443 "VDO (aka Continental-Corporation)" 451 "Parker Hannifin aka Village Marine Tech" 459 "Alltek Marine Electronics" 460 "SAN GIORGIO S.E.I.N" 466 "Veethree Electronics & Marine" 470 "SI-TEX Marine Electronics" 471 "Sea Cross Marine" 475 "GME aka Standard Communications" 476 "Humminbird Marine Electronics" 478 "Ocean Sat" 481 "Chetco Digital Instruments" 493 "Watcheye" 499 "Lcj Capteurs" 502 "Attwood Marine" 503 "Naviop S.R.L." 504 "Vesper Marine" 510 "Marinesoft" 513 "Simarine" 517 "NoLand Engineering" 518 "Transas USA" 529 "National Instruments Korea" 530 "National Marine Electronics Association" 532 "Onwa Marine" 540 "Webasto" 571 "Marinecraft (South Korea)" 573 "McMurdo Group aka Orolia" 578 "Advansea" 579 "KVH" 580 "San Jose Technology" 583 "Yacht Control" 586 "Suzuki Motor" 591 "US Coast Guard" 595 "Ship Module aka Customware" 600 "Aquatic AV" 605 "Aventics" 606 "Intellian" 612 "SamwonIT" 614 "Arlt Tecnologies" 637 "Bavaria Yachts" 641 "Diverse Yacht Services" 644 "Wema U.S.A dba KUS" 658 "Shenzhen Jiuzhou Himunication" 688 "Rockford" 699 "Harman International" 704 "JL Audio" 708 "Lars Thrane" 715 "Autonnic" 717 "Yacht Devices" 734 "REAP Systems" 735 "AEM Performance Electronics" 739 "LxNav" 741 "Littelfuse, Inc (formerly Carling Technologies)" 743 "DaeMyung" 744 "Woosung" 748 "ISOTTA IFRA srl" 773 "Clarion US" 776 "HMI Systems" 777 "Ocean Signal" 778 "Seakeeper" 781 "Poly Planar" 785 "Fischer Panda DE" 795 "Broyda Industries" 796 "Canadian Automotive" 797 "Tides Marine" 798 "Lumishore" 799 "Still Water Designs and Audio" 802 "BJ Technologies (Beneteau)" 803 "Gill Sensors" 811 "Blue Water Desalination" 815 "FLIR" 824 "Undheim Systems" 826 "Lewmar" 838 "TeamSurv" 844 "Fell Marine" 847 "Oceanvolt" 862 "Prospec" 868 "Data Panel" 890 "L3 Technologies" 894 "Rhodan Marine Systems" 896 "Nexfour Solutions" 905 "ASA Electronics" 909 "Marines Co (South Korea)" 911 "Nautic-on" 917 "Sentinel" 929 "JL Marine Systems" 930 "Ecotronix" 944 "Zontisa Marine" 951 "EXOR International" 962 "Timbolier Industries" 963 "TJC Micro" 968 "Cox Powertrain" 969 "Blue Seas" 981 "Kobelt Manufacturing" 992 "Blue Ocean IOT" 997 "Xenta Systems" 999 "Signal K" 1004 "Ultraflex" 1008 "Lintest SmartBoat" 1011 "Soundmax" 1020 "Team Italia Marine (Onyx Marine Automation s.r.l)" 1021 "Entratech" 1022 "ITC" 1029 "The Marine Guardian" 1047 "Sonic" 1051 "ProNav" 1053 "Vetus Maxwell INC." 1056 "Lithium Pros" 1059 "Boatrax" 1062 "Marol Co ltd" 1065 "CALYPSO Instruments" 1066 "Spot Zero Water" 1069 "Lithionics Battery" 1070 "Quick-teck Electronics" 1075 "Uniden America" 1083 "Nauticoncept" 1084 "Shadow-Caster LED lighting" 1085 "Wet Sounds" 1088 "E-T-A Circuit Breakers" 1092 "Scheiber" 1100 "Smart Yachts International Limited" 1109 "Dockmate" 1114 "Bobs Machine" 1118 "L3Harris ASV" 1119 "Balmar" 1120 "Elettromedia" 1127 "Electromaax" 1140 "Across Oceans Systems" 1145 "Kiwi Yachting" 1150 "BSB Artificial Intelligence" 1151 "Orca Technologies" 1154 "TBS Electronics" 1158 "Technoton Electroics" 1160 "MG Energy Systems" 1169 "Sea Machine Robotics" 1171 "Vista Manufacturing" 1183 "Zipwake" 1186 "Sailmon" 1192 "Airmoniq Pro Kft" 1194 "Sierra Marine" 1200 "Xinuo Information Technology (Xiamen)" 1218 "Septentrio" 1233 "NKE Marine Electronics" 1238 "SuperTrack Aps" 1239 "Honda Electronics" 1245 "Raritan Engineering" 1249 "Integrated Power Solutions AG" 1260 "Interactive Technologies" 1283 "LTG-Tech" 1299 "Energy Solutions (UK)" 1300 "WATT Fuel Cell" 1302 "Pro Mainer" 1305 "Dragonfly Energy" 1306 "Koden Electronics" 1311 "Humphree" 1316 "Hinkley Yachts" 1317 "Global Marine Management GmbH (GMM)" 1320 "Triskel Marine" 1330 "Warwick Control Technologies" 1331 "Dolphin Charger" 1337 "Barnacle Systems" 1348 "Radian IoT" 1353 "Ocean LED Marine" 1359 "BluNav" 1361 "OVA (Nantong Saiyang Electronics Co., Ltd)" 1368 "RAD Propulsion" 1369 "Electric Yacht" 1372 "Elco Motor Yachts" 1384 "Tecnoseal Foundry S.r.l" 1385 "Pro Charging Systems" 1389 "EVEX" 1398 "Gobius Sensor Technology" 1403 "Arco Marine" 1408 "Lenco Marine" 1413 "Naocontrol" 1417 "Revatek" 1438 "Aeolionics" 1439 "PredictWind" 1440 "Egis Mobile Electric" 1445 "Starboard Yacht Group" 1446 "Roswell Marine" 1451 "ePropulsion (Guangdong ePropulsion Technology Ltd.)" 1452 "Micro-Air" 1453 "Vital Battery" 1458 "Ride Controller" 1460 "Tocaro Blue" 1461 "Vanquish Yachts" 1471 "FT Technologies" 1478 "Alps Alpine" 1481 "E-Force Marine" 1482 "CMC Marine" 1483 "Nanjing Sandemarine Information Technology" 1850 "Teleflex Marine (SeaStar Solutions)" 1851 "Raymarine" 1852 "Navionics" 1853 "Japan Radio" 1854 "Northstar Technologies" 1855 "Furuno" 1856 "Trimble" 1857 "Simrad" 1858 "Litton" 1859 "Kvasar" 1860 "MMP" 1861 "Vector Cantech" 1862 "Yamaha Marine" 1863 "Faria Instruments" ;
VAL_ 2566853632 Industry_Code 0 "Global" 1 "Highway" 2 "Agriculture" 3 "Construction" 4 "Marine Industry" 5 "Industrial" ;
VAL_ 2566853888 Manufacturer_Code 69 "ARKS Enterprises" 78 "FW Murphy/Enovation Controls" 80 "Twin Disc" 85 "Kohler Power Systems" 88 "Hemisphere GPS" 135 "Airmar" 137 "Maretron" 140 "Lowrance" 144 "Mercury Marine" 147 "Nautibus Electronic" 148 "Blue Water Data" 154 "Westerbeke" 157 "ISSPRO" 161 "Offshore Systems (UK)" 163 "Evinrude/BRP" 165 "CPAC Systems" 168 "Xantrex Technology" 169 "Marlin Technologies" 172 "Yanmar Marine" 174 "Volvo Penta" 176 "Carling Technologies Inc. (Moritz Aerospace)" 185 "Beede Instruments" 192 "Floscan Instrument" 193 "Nobeltec" 198 "Mystic Valley Communications" 199 "Actia" 201 "Disenos Y Technologia" 211 "Digital Switching Systems" 215 "Xintex/Atena" 224 "EMMI NETWORK" 228 "ZF" 229 "Garmin" 233 "Yacht Monitoring Solutions" 235 "Sailormade Marine Telemetry/Tetra Technology" 243 "Eride" 257 "Honda Motor" 272 "Groco" 273 "Actisense" 274 "Amphenol LTW Technology" 275 "Navico" 283 "Hamilton Jet" 285 "Sea Recovery" 286 "Coelmo SRL Italy" 295 "BEP Marine" 304 "Empir Bus" 305 "NovAtel" 306 "Sleipner Motor" 307 "MBW Technologies" 315 "ICOM" 328 "Qwerty" 329 "Dief" 341 "Boening Automationstechnologie" 345 "Korean Maritime University" 351 "Thrane and Thrane" 355 "Mastervolt" 356 "Fischer Panda Generators" 358 "Victron Energy" 370 "Rolls Royce Marine" 373 "Electronic Design" 374 "Northern Lights" 378 "Glendinning" 381 "B & G" 384 "Rose Point Navigation Systems" 385 "Johnson Outdoors Marine Electronics Inc Geonav" 394 "Capi 2" 396 "Beyond Measure" 400 "Livorsi Marine" 404 "ComNav" 409 "Chetco" 419 "Fusion Electronics" 421 "Standard Horizon" 422 "True Heading" 426 "Egersund Marine Electronics" 427 "em-trak Marine Electronics" 431 "Tohatsu Co, JP" 437 "Digital Yacht" 438 "Comar Systems Limited" 440 "Cummins" 443 "VDO (aka Continental-Corporation)" 451 "Parker Hannifin aka Village Marine Tech" 459 "Alltek Marine Electronics" 460 "SAN GIORGIO S.E.I.N" 466 "Veethree Electronics & Marine" 470 "SI-TEX Marine Electronics" 471 "Sea Cross Marine" 475 "GME aka Standard Communications" 476 "Humminbird Marine Electronics" 478 "Ocean Sat" 481 "Chetco Digital Instruments" 493 "Watcheye" 499 "Lcj Capteurs" 502 "Attwood Marine" 503 "Naviop S.R.L." 504 "Vesper Marine" 510 "Marinesoft" 513 "Simarine" 517 "NoLand Engineering" 518 "Transas USA" 529 "National Instruments Korea" 530 "National Marine Electronics Association" 532 "Onwa Marine" 540 "Webasto" 571 "Marinecraft (South Korea)" 573 "McMurdo Group aka Orolia" 578 "Advansea" 579 "KVH" 580 "San Jose Technology" 583 "Yacht Control" 586 "Suzuki Motor" 591 "US Coast Guard" 595 "Ship Module aka Customware" 600 "Aquatic AV" 605 "Aventics" 606 "Intellian" 612 "SamwonIT" 614 "Arlt Tecnologies" 637 "Bavaria Yachts" 641 "Diverse Yacht Services" 644 "Wema U.S.A dba KUS" 658 "Shenzhen Jiuzhou Himunication" 688 "Rockford" 699 "Harman International" 704 "JL Audio" 708 "Lars Thrane" 715 "Autonnic" 717 "Yacht Devices" 734 "REAP Systems" 735 "AEM Performance Electronics" 739 "LxNav" 741 "Littelfuse, Inc (formerly Carling Technologies)" 743 "DaeMyung" 744 "Woosung" 748 "ISOTTA IFRA srl" 773 "Clarion US" 776 "HMI Systems" 777 "Ocean Signal" 778 "Seakeeper" 781 "Poly Planar" 785 "Fischer Panda DE" 795 "Broyda Industries" 796 "Canadian Automotive" 797 "Tides Marine" 798 "Lumishore" 799 "Still Water Designs and Audio" 802 "BJ Technologies (Beneteau)" 803 "Gill Sensors" 811 "Blue Water Desalination" 815 "FLIR" 824 "Undheim Systems" 826 "Lewmar" 838 "TeamSurv" 844 "Fell Marine" 847 "Oceanvolt" 862 "Prospec" 868 "Data Panel" 890 "L3 Technologies" 894 "Rhodan Marine Systems" 896 "Nexfour Solutions" 905 "ASA Electronics" 909 "Marines Co (South Korea)" 911 "Nautic-on" 917 "Sentinel" 929 "JL Marine Systems" 930 "Ecotronix" 944 "Zontisa Marine" 951 "EXOR International" 962 "Timbolier Industries" 963 "TJC Micro" 968 "Cox Powertrain" 969 "Blue Seas" 981 "Kobelt Manufacturing" 992 "Blue Ocean IOT" 997 "Xenta Systems" 999 "Signal K" 1004 "Ultraflex" 1008 "Lintest SmartBoat" 1011 "Soundmax" 1020 "Team Italia Marine (Onyx Marine Automation s.r.l)" 1021 "Entratech" 1022 "ITC" 1029 "The Marine Guardian" 1047 "Sonic" 1051 "ProNav" 1053 "Vetus Maxwell INC." 1056 "Lithium Pros" 1059 "Boatrax" 1062 "Marol Co ltd" 1065 "CALYPSO Instruments" 1066 "Spot Zero Water" 1069 "Lithionics Battery" 1070 "Quick-teck Electronics" 1075 "Uniden America" 1083 "Nauticoncept" 1084 "Shadow-Caster LED lighting" 1085 "Wet Sounds" 1088 "E-T-A Circuit Breakers" 1092 "Scheiber" 1100 "Smart Yachts International Limited" 1109 "Dockmate" 1114 "Bobs Machine" 1118 "L3Harris ASV" 1119 "Balmar" 1120 "Elettromedia" 1127 "Electromaax" 1140 "Across Oceans Systems" 1145 "Kiwi Yachting" 1150 "BSB Artificial Intelligence" 1151 "Orca Technologies" 1154 "TBS Electronics" 1158 "Technoton Electroics" 1160 "MG Energy Systems" 1169 "Sea Machine Robotics" 1171 "Vista Manufacturing" 1183 "Zipwake" 1186 "Sailmon" 1192 "Airmoniq Pro Kft" 1194 "Sierra Marine" 1200 "Xinuo Information Technology (Xiamen)" 1218 "Septentrio" 1233 "NKE Marine Electronics" 1238 "SuperTrack Aps" 1239 "Honda Electronics" 1245 "Raritan Engineering" 1249 "Integrated Power Solutions AG" 1260 "Interactive Technologies" 1283 "LTG-Tech" 1299 "Energy Solutions (UK)" 1300 "WATT Fuel Cell" 1302 "Pro Mainer" 1305 "Dragonfly Energy" 1306 "Koden Electronics" 1311 "Humphree" 1316 "Hinkley Yachts" 1317 "Global Marine Management GmbH (GMM)" 1320 "Triskel Marine" 1330 "Warwick Control Technologies" 1331 "Dolphin Charger" 1337 "Barnacle Systems" 1348 "Radian IoT" 1353 "Ocean LED Marine" 1359 "BluNav" 1361 "OVA (Nantong Saiyang Electronics Co., Ltd)" 1368 "RAD Propulsion" 1369 "Electric Yacht" 1372 "Elco Motor Yachts" 1384 "Tecnoseal Foundry S.r.l" 1385 "Pro Charging Systems" 1389 "EVEX" 1398 "Gobius Sensor Technology" 1403 "Arco Marine" 1408 "Lenco Marine" 1413 "Naocontrol" 1417 "Revatek" 1438 "Aeolionics" 1439 "PredictWind" 1440 "Egis Mobile Electric" 1445 "Starboard Yacht Group" 1446 "Roswell Marine" 1451 "ePropulsion (Guangdong ePropulsion Technology Ltd.)" 1452 "Micro-Air" 1453 "Vital Battery" 1458 "Ride Controller" 1460 "Tocaro Blue" 1461 "Vanquish Yachts" 1471 "FT Technologies" 1478 "Alps Alpine" 1481 "E-Force Marine" 1482 "CMC Marine" 1483 "Nanjing Sandemarine Information Technology" 1850 "Teleflex Marine (SeaStar Solutions)" 1851 "Raymarine" 1852 "Navionics" 1853 "Japan Radio" 1854 "Northstar Technologies" 1855 "Furuno" 1856 "Trimble" 1857 "Simrad" 1858 "Litton" 1859 "Kvasar" 1860 "MMP" 1861 "Vector Cantech" 1862 "Yamaha Marine" 1863 "Faria Instruments" ;
VAL_ 2566853888 Industry_Code 0 "Global" 1 "Highway" 2 "Agriculture" 3 "Construction" 4 "Marine Industry" 5 "Industrial" ;
VAL_ 2633963008 Manufacturer_Code 69 "ARKS Enterprises" 78 "FW Murphy/Enovation Controls" 80 "Twin Disc" 85 "Kohler Power Systems" 88 "Hemisphere GPS" 135 "Airmar" 137 "Maretron" 140 "Lowrance" 144 "Mercury Marine" 147 "Nautibus Electronic" 148 "Blue Water Data" 154 "Westerbeke" 157 "ISSPRO" 161 "Offshore Systems (UK)" 163 "Evinrude/BRP" 165 "CPAC Systems" 168 "Xantrex Technology" 169 "Marlin Technologies" 172 "Yanmar Marine" 174 "Volvo Penta" 176 "Carling Technologies Inc. (Moritz Aerospace)" 185 "Beede Instruments" 192 "Floscan Instrument" 193 "Nobeltec" 198 "Mystic Valley Communications" 199 "Actia" 201 "Disenos Y Technologia" 211 "Digital Switching Systems" 215 "Xintex/Atena" 224 "EMMI NETWORK" 228 "ZF" 229 "Garmin" 233 "Yacht Monitoring Solutions" 235 "Sailormade Marine Telemetry/Tetra Technology" 243 "Eride" 257 "Honda Motor" 272 "Groco" 273 "Actisense" 274 "Amphenol LTW Technology" 275 "Navico" 283 "Hamilton Jet" 285 "Sea Recovery" 286 "Coelmo SRL Italy" 295 "BEP Marine" 304 "Empir Bus" 305 "NovAtel" 306 "Sleipner Motor" 307 "MBW Technologies" 315 "ICOM" 328 "Qwerty" 329 "Dief" 341 "Boening Automationstechnologie" 345 "Korean Maritime University" 351 "Thrane and Thrane" 355 "Mastervolt" 356 "Fischer Panda Generators" 358 "Victron Energy" 370 "Rolls Royce Marine" 373 "Electronic Design" 374 "Northern Lights" 378 "Glendinning" 381 "B & G" 384 "Rose Point Navigation Systems" 385 "Johnson Outdoors Marine Electronics Inc Geonav" 394 "Capi 2" 396 "Beyond Measure" 400 "Livorsi Marine" 404 "ComNav" 409 "Chetco" 419 "Fusion Electronics" 421 "Standard Horizon" 422 "True Heading" 426 "Egersund Marine Electronics" 427 "em-trak Marine Electronics" 431 "Tohatsu Co, JP" 437 "Digital Yacht" 438 "Comar Systems Limited" 440 "Cummins" 443 "VDO (aka Continental-Corporation)" 451 "Parker Hannifin aka Village Marine Tech" 459 "Alltek Marine Electronics" 460 "SAN GIORGIO S.E.I.N" 466 "Veethree Electronics & Marine" 470 "SI-TEX Marine Electronics" 471 "Sea Cross Marine" 475 "GME aka Standard Communications" 476 "Humminbird Marine Electronics" 478 "Ocean Sat" 481 "Chetco Digital Instruments" 493 "Watcheye" 499 "Lcj Capteurs" 502 "Attwood Marine" 503 "Naviop S.R.L." 504 "Vesper Marine" 510 "Marinesoft" 513 "Simarine" 517 "NoLand Engineering" 518 "Transas USA" 529 "National Instruments Korea" 530 "National Marine Electronics Association" 532 "Onwa Marine" 540 "Webasto" 571 "Marinecraft (South Korea)" 573 "McMurdo Group aka Orolia" 578 "Advansea" 579 "KVH" 580 "San Jose Technology" 583 "Yacht Control" 586 "Suzuki Motor" 591 "US Coast Guard" 595 "Ship Module aka Customware" 600 "Aquatic AV" 605 "Aventics" 606 "Intellian" 612 "SamwonIT" 614 "Arlt Tecnologies" 637 "Bavaria Yachts" 641 "Diverse Yacht Services" 644 "Wema U.S.A dba KUS" 658 "Shenzhen Jiuzhou Himunication" 688 "Rockford" 699 "Harman International" 704 "JL Audio" 708 "Lars Thrane" 715 "Autonnic" 717 "Yacht Devices" 734 "REAP Systems" 735 "AEM Performance Electronics" 739 "LxNav" 741 "Littelfuse, Inc (formerly Carling Technologies)" 743 "DaeMyung" 744 "Woosung" 748 "ISOTTA IFRA srl" 773 "Clarion US" 776 "HMI Systems" 777 "Ocean Signal" 778 "Seakeeper" 781 "Poly Planar" 785 "Fischer Panda DE" 795 "Broyda Industries" 796 "Canadian Automotive" 797 "Tides Marine" 798 "Lumishore" 799 "Still Water Designs and Audio" 802 "BJ Technologies (Beneteau)" 803 "Gill Sensors" 811 "Blue Water Desalination" 815 "FLIR" 824 "Undheim Systems" 826 "Lewmar" 838 "TeamSurv" 844 "Fell Marine" 847 "Oceanvolt" 862 "Prospec" 868 "Data Panel" 890 "L3 Technologies" 894 "Rhodan Marine Systems" 896 "Nexfour Solutions" 905 "ASA Electronics" 909 "Marines Co (South Korea)" 911 "Nautic-on" 917 "Sentinel" 929 "JL Marine Systems" 930 "Ecotronix" 944 "Zontisa Marine" 951 "EXOR International" 962 "Timbolier Industries" 963 "TJC Micro" 968 "Cox Powertrain" 969 "Blue Seas" 981 "Kobelt Manufacturing" 992 "Blue Ocean IOT" 997 "Xenta Systems" 999 "Signal K" 1004 "Ultraflex" 1008 "Lintest SmartBoat" 1011 "Soundmax" 1020 "Team Italia Marine (Onyx Marine Automation s.r.l)" 1021 "Entratech" 1022 "ITC" 1029 "The Marine Guardian" 1047 "Sonic" 1051 "ProNav" 1053 "Vetus Maxwell INC." 1056 "Lithium Pros" 1059 "Boatrax" 1062 "Marol Co ltd" 1065 "CALYPSO Instruments" 1066 "Spot Zero Water" 1069 "Lithionics Battery" 1070 "Quick-teck Electronics" 1075 "Uniden America" 1083 "Nauticoncept" 1084 "Shadow-Caster LED lighting" 1085 "Wet Sounds" 1088 "E-T-A Circuit Breakers" 1092 "Scheiber" 1100 "Smart Yachts International Limited" 1109 "Dockmate" 1114 "Bobs Machine" 1118 "L3Harris ASV" 1119 "Balmar" 1120 "Elettromedia" 1127 "Electromaax" 1140 "Across Oceans Systems" 1145 "Kiwi Yachting" 1150 "BSB Artificial Intelligence" 1151 "Orca Technologies" 1154 "TBS Electronics" 1158 "Technoton Electroics" 1160 "MG Energy Systems" 1169 "Sea Machine Robotics" 1171 "Vista Manufacturing" 1183 "Zipwake" 1186 "Sailmon" 1192 "Airmoniq Pro Kft" 1194 "Sierra Marine" 1200 "Xinuo Information Technology (Xiamen)" 1218 "Septentrio" 1233 "NKE Marine Electronics" 1238 "SuperTrack Aps" 1239 "Honda Electronics" 1245 "Raritan Engineering" 1249 "Integrated Power Solutions AG" 1260 "Interactive Technologies" 1283 "LTG-Tech" 1299 "Energy Solutions (UK)" 1300 "WATT Fuel Cell" 1302 "Pro Mainer" 1305 "Dragonfly Energy" 1306 "Koden Electronics" 1311 "Humphree" 1316 "Hinkley Yachts" 1317 "Global Marine Management GmbH (GMM)" 1320 "Triskel Marine" 1330 "Warwick Control Technologies" 1331 "Dolphin Charger" 1337 "Barnacle Systems" 1348 "Radian IoT" 1353 "Ocean LED Marine" 1359 "BluNav" 1361 "OVA (Nantong Saiyang Electronics Co., Ltd)" 1368 "RAD Propulsion" 1369 "Electric Yacht" 1372 "Elco Motor Yachts" 1384 "Tecnoseal Foundry S.r.l" 1385 "Pro Charging Systems" 1389 "EVEX" 1398 "Gobius Sensor Technology" 1403 "Arco Marine" 1408 "Lenco Marine" 1413 "Naocontrol" 1417 "Revatek" 1438 "Aeolionics" 1439 "PredictWind" 1440 "Egis Mobile Electric" 1445 "Starboard Yacht Group" 1446 "Roswell Marine" 1451 "ePropulsion (Guangdong ePropulsion Technology Ltd.)" 1452 "Micro-Air" 1453 "Vital Battery" 1458 "Ride Controller" 1460 "Tocaro Blue" 1461 "Vanquish Yachts" 1471 "FT Technologies" 1478 "Alps Alpine" 1481 "E-Force Marine" 1482 "CMC Marine" 1483 "Nanjing Sandemarine Information Technology" 1850 "Teleflex Marine (SeaStar Solutions)" 1851 "Raymarine" 1852 "Navionics" 1853 "Japan Radio" 1854 "Northstar Technologies" 1855 "Furuno" 1856 "Trimble" 1857 "Simrad" 1858 "Litton" 1859 "Kvasar" 1860 "MMP" 1861 "Vector Cantech" 1862 "Yamaha Marine" 1863 "Faria Instruments" ;
VAL_ 2633963008 Industry_Code 0 "Global" 1 "Highway" 2 "Agriculture" 3 "Construction" 4 "Marine Industry" 5 "Industrial" ;
VAL_ 2566854400 Manufacturer_Code 69 "ARKS Enterprises" 78 "FW Murphy/Enovation Controls" 80 "Twin Disc" 85 "Kohler Power Systems" 88 "Hemisphere GPS" 135 "Airmar" 137 "Maretron" 140 "Lowrance" 144 "Mercury Marine" 147 "Nautibus Electronic" 148 "Blue Water Data" 154 "Westerbeke" 157 "ISSPRO" 161 "Offshore Systems (UK)" 163 "Evinrude/BRP" 165 "CPAC Systems" 168 "Xantrex Technology" 169 "Marlin Technologies" 172 "Yanmar Marine" 174 "Volvo Penta" 176 "Carling Technologies Inc. (Moritz Aerospace)" 185 "Beede Instruments" 192 "Floscan Instrument" 193 "Nobeltec" 198 "Mystic Valley Communications" 199 "Actia" 201 "Disenos Y Technologia" 211 "Digital Switching Systems" 215 "Xintex/Atena" 224 "EMMI NETWORK" 228 "ZF" 229 "Garmin" 233 "Yacht Monitoring Solutions" 235 "Sailormade Marine Telemetry/Tetra Technology" 243 "Eride" 257 "Honda Motor" 272 "Groco" 273 "Actisense" 274 "Amphenol LTW Technology" 275 "Navico" 283 "Hamilton Jet" 285 "Sea Recovery" 286 "Coelmo SRL Italy" 295 "BEP Marine" 304 "Empir Bus" 305 "NovAtel" 306 "Sleipner Motor" 307 "MBW Technologies" 315 "ICOM" 328 "Qwerty" 329 "Dief" 341 "Boening Automationstechnologie" 345 "Korean Maritime University" 351 "Thrane and Thrane" 355 "Mastervolt" 356 "Fischer Panda Generators" 358 "Victron Energy" 370 "Rolls Royce Marine" 373 "Electronic Design" 374 "Northern Lights" 378 "Glendinning" 381 "B & G" 384 "Rose Point Navigation Systems" 385 "Johnson Outdoors Marine Electronics Inc Geonav" 394 "Capi 2" 396 "Beyond Measure" 400 "Livorsi Marine" 404 "ComNav" 409 "Chetco" 419 "Fusion Electronics" 421 "Standard Horizon" 422 "True Heading" 426 "Egersund Marine Electronics" 427 "em-trak Marine Electronics" 431 "Tohatsu Co, JP" 437 "Digital Yacht" 438 "Comar Systems Limited" 440 "Cummins" 443 "VDO (aka Continental-Corporation)" 451 "Parker Hannifin aka Village Marine Tech" 459 "Alltek Marine Electronics" 460 "SAN GIORGIO S.E.I.N" 466 "Veethree Electronics & Marine" 470 "SI-TEX Marine Electronics" 471 "Sea Cross Marine" 475 "GME aka Standard Communications" 476 "Humminbird Marine Electronics" 478 "Ocean Sat" 481 "Chetco Digital Instruments" 493 "Watcheye" 499 "Lcj Capteurs" 502 "Attwood Marine" 503 "Naviop S.R.L." 504 "Vesper Marine" 510 "Marinesoft" 513 "Simarine" 517 "NoLand Engineering" 518 "Transas USA" 529 "National Instruments Korea" 530 "National Marine Electronics Association" 532 "Onwa Marine" 540 "Webasto" 571 "Marinecraft (South Korea)" 573 "McMurdo Group aka Orolia" 578 "Advansea" 579 "KVH" 580 "San Jose Technology" 583 "Yacht Control" 586 "Suzuki Motor" 591 "US Coast Guard" 595 "Ship Module aka Customware" 600 "Aquatic AV" 605 "Aventics" 606 "Intellian" 612 "SamwonIT" 614 "Arlt Tecnologies" 637 "Bavaria Yachts" 641 "Diverse Yacht Services" 644 "Wema U.S.A dba KUS" 658 "Shenzhen Jiuzhou Himunication" 688 "Rockford" 699 "Harman International" 704 "JL Audio" 708 "Lars Thrane" 715 "Autonnic" 717 "Yacht Devices" 734 "REAP Systems" 735 "AEM Performance Electronics" 739 "LxNav" 741 "Littelfuse, Inc (formerly Carling Technologies)" 743 "DaeMyung" 744 "Woosung" 748 "ISOTTA IFRA srl" 773 "Clarion US" 776 "HMI Systems" 777 "Ocean Signal" 778 "Seakeeper" 781 "Poly Planar" 785 "Fischer Panda DE" 795 "Broyda Industries" 796 "Canadian Automotive" 797 "Tides Marine" 798 "Lumishore" 799 "Still Water Designs and Audio" 802 "BJ Technologies (Beneteau)" 803 "Gill Sensors" 811 "Blue Water Desalination" 815 "FLIR" 824 "Undheim Systems" 826 "Lewmar" 838 "TeamSurv" 844 "Fell Marine" 847 "Oceanvolt" 862 "Prospec" 868 "Data Panel" 890 "L3 Technologies" 894 "Rhodan Marine Systems" 896 "Nexfour Solutions" 905 "ASA Electronics" 909 "Marines Co (South Korea)" 911 "Nautic-on" 917 "Sentinel" 929 "JL Marine Systems" 930 "Ecotronix" 944 "Zontisa Marine" 951 "EXOR International" 962 "Timbolier Industries" 963 "TJC Micro" 968 "Cox Powertrain" 969 "Blue Seas" 981 "Kobelt Manufacturing" 992 "Blue Ocean IOT" 997 "Xenta Systems" 999 "Signal K" 1004 "Ultraflex" 1008 "Lintest SmartBoat" 1011 "Soundmax" 1020 "Team Italia Marine (Onyx Marine Automation s.r.l)" 1021 "Entratech" 1022 "ITC" 1029 "The Marine Guardian" 1047 "Sonic" 1051 "ProNav" 1053 "Vetus Maxwell INC." 1056 "Lithium Pros" 1059 "Boatrax" 1062 "Marol Co ltd" 1065 "CALYPSO Instruments" 1066 "Spot Zero Water" 1069 "Lithionics Battery" 1070 "Quick-teck Electronics" 1075 "Uniden America" 1083 "Nauticoncept" 1084 "Shadow-Caster LED lighting" 1085 "Wet Sounds" 1088 "E-T-A Circuit Breakers" 1092 "Scheiber" 1100 "Smart Yachts International Limited" 1109 "Dockmate" 1114 "Bobs Machine" 1118 "L3Harris ASV" 1119 "Balmar" 1120 "Elettromedia" 1127 "Electromaax" 1140 "Across Oceans Systems" 1145 "Kiwi Yachting" 1150 "BSB Artificial Intelligence" 1151 "Orca Technologies" 1154 "TBS Electronics" 1158 "Technoton Electroics" 1160 "MG Energy Systems" 1169 "Sea Machine Robotics" 1171 "Vista Manufacturing" 1183 "Zipwake" 1186 "Sailmon" 1192 "Airmoniq Pro Kft" 1194 "Sierra Marine" 1200 "Xinuo Information Technology (Xiamen)" 1218 "Septentrio" 1233 "NKE Marine Electronics" 1238 "SuperTrack Aps" 1239 "Honda Electronics" 1245 "Raritan Engineering" 1249 "Integrated Power Solutions AG" 1260 "Interactive Technologies" 1283 "LTG-Tech" 1299 "Energy Solutions (UK)" 1300 "WATT Fuel Cell" 1302 "Pro Mainer" 1305 "Dragonfly Energy" 1306 "Koden Electronics" 1311 "Humphree" 1316 "Hinkley Yachts" 1317 "Global Marine Management GmbH (GMM)" 1320 "Triskel Marine" 1330 "Warwick Control Technologies" 1331 "Dolphin Charger" 1337 "Barnacle Systems" 1348 "Radian IoT" 1353 "Ocean LED Marine" 1359 "BluNav" 1361 "OVA (Nantong Saiyang Electronics Co., Ltd)" 1368 "RAD Propulsion" 1369 "Electric Yacht" 1372 "Elco Motor Yachts" 1384 "Tecnoseal Foundry S.r.l" 1385 "Pro Charging Systems" 1389 "EVEX" 1398 "Gobius Sensor Technology" 1403 "Arco Marine" 1408 "Lenco Marine" 1413 "Naocontrol" 1417 "Revatek" 1438 "Aeolionics" 1439 "PredictWind" 1440 "Egis Mobile Electric" 1445 "Starboard Yacht Group" 1446 "Roswell Marine" 1451 "ePropulsion (Guangdong ePropulsion Technology Ltd.)" 1452 "Micro-Air" 1453 "Vital Battery" 1458 "Ride Controller" 1460 "Tocaro Blue" 1461 "Vanquish Yachts" 1471 "FT Technologies" 1478 "Alps Alpine" 1481 "E-Force Marine" 1482 "CMC Marine" 1483 "Nanjing Sandemarine Information Technology" 1850 "Teleflex Marine (SeaStar Solutions)" 1851 "Raymarine" 1852 "Navionics" 1853 "Japan Radio" 1854 "Northstar Technologies" 1855 "Furuno" 1856 "Trimble" 1857 "Simrad" 1858 "Litton" 1859 "Kvasar" 1860 "MMP" 1861 "Vector Cantech" 1862 "Yamaha Marine" 1863 "Faria Instruments" ;
VAL_ 2566854400 Industry_Code 0 "Global" 1 "Highway" 2 "Agriculture" 3 "Construction" 4 "Marine Industry" 5 "Industrial" ;
VAL_ 2566854400 Manufacturer_Code 69 "ARKS Enterprises" 78 "FW Murphy/Enovation Controls" 80 "Twin Disc" 85 "Kohler Power Systems" 88 "Hemisphere GPS" 135 "Airmar" 137 "Maretron" 140 "Lowrance" 144 "Mercury Marine" 147 "Nautibus Electronic" 148 "Blue Water Data" 154 "Westerbeke" 157 "ISSPRO" 161 "Offshore Systems (UK)" 163 "Evinrude/BRP" 165 "CPAC Systems" 168 "Xantrex Technology" 169 "Marlin Technologies" 172 "Yanmar Marine" 174 "Volvo Penta" 176 "Carling Technologies Inc. (Moritz Aerospace)" 185 "Beede Instruments" 192 "Floscan Instrument" 193 "Nobeltec" 198 "Mystic Valley Communications" 199 "Actia" 201 "Disenos Y Technologia" 211 "Digital Switching Systems" 215 "Xintex/Atena" 224 "EMMI NETWORK" 228 "ZF" 229 "Garmin" 233 "Yacht Monitoring Solutions" 235 "Sailormade Marine Telemetry/Tetra Technology" 243 "Eride" 257 "Honda Motor" 272 "Groco" 273 "Actisense" 274 "Amphenol LTW Technology" 275 "Navico" 283 "Hamilton Jet" 285 "Sea Recovery" 286 "Coelmo SRL Italy" 295 "BEP Marine" 304 "Empir Bus" 305 "NovAtel" 306 "Sleipner Motor" 307 "MBW Technologies" 315 "ICOM" 328 "Qwerty" 329 "Dief" 341 "Boening Automationstechnologie" 345 "Korean Maritime University" 351 "Thrane and Thrane" 355 "Mastervolt" 356 "Fischer Panda Generators" 358 "Victron Energy" 370 "Rolls Royce Marine" 373 "Electronic Design" 374 "Northern Lights" 378 "Glendinning" 381 "B & G" 384 "Rose Point Navigation Systems" 385 "Johnson Outdoors Marine Electronics Inc Geonav" 394 "Capi 2" 396 "Beyond Measure" 400 "Livorsi Marine" 404 "ComNav" 409 "Chetco" 419 "Fusion Electronics" 421 "Standard Horizon" 422 "True Heading" 426 "Egersund Marine Electronics" 427 "em-trak Marine Electronics" 431 "Tohatsu Co, JP" 437 "Digital Yacht" 438 "Comar Systems Limited" 440 "Cummins" 443 "VDO (aka Continental-Corporation)" 451 "Parker Hannifin aka Village Marine Tech" 459 "Alltek Marine Electronics" 460 "SAN GIORGIO S.E.I.N" 466 "Veethree Electronics & Marine" 470 "SI-TEX Marine Electronics" 471 "Sea Cross Marine" 475 "GME aka Standard Communications" 476 "Humminbird Marine Electronics" 478 "Ocean Sat" 481 "Chetco Digital Instruments" 493 "Watcheye" 499 "Lcj Capteurs" 502 "Attwood Marine" 503 "Naviop S.R.L." 504 "Vesper Marine" 510 "Marinesoft" 513 "Simarine" 517 "NoLand Engineering" 518 "Transas USA" 529 "National Instruments Korea" 530 "National Marine Electronics Association" 532 "Onwa Marine" 540 "Webasto" 571 "Marinecraft (South Korea)" 573 "McMurdo Group aka Orolia" 578 "Advansea" 579 "KVH" 580 "San Jose Technology" 583 "Yacht Control" 586 "Suzuki Motor" 591 "US Coast Guard" 595 "Ship Module aka Customware" 600 "Aquatic AV" 605 "Aventics" 606 "Intellian" 612 "SamwonIT" 614 "Arlt Tecnologies" 637 "Bavaria Yachts" 641 "Diverse Yacht Services" 644 "Wema U.S.A dba KUS" 658 "Shenzhen Jiuzhou Himunication" 688 "Rockford" 699 "Harman International" 704 "JL Audio" 708 "Lars Thrane" 715 "Autonnic" 717 "Yacht Devices" 734 "REAP Systems" 735 "AEM Performance Electronics" 739 "LxNav" 741 "Littelfuse, Inc (formerly Carling Technologies)" 743 "DaeMyung" 744 "Woosung" 748 "ISOTTA IFRA srl" 773 "Clarion US" 776 "HMI Systems" 777 "Ocean Signal" 778 "Seakeeper" 781 "Poly Planar" 785 "Fischer Panda DE" 795 "Broyda Industries" 796 "Canadian Automotive" 797 "Tides Marine" 798 "Lumishore" 799 "Still Water Designs and Audio" 802 "BJ Technologies (Beneteau)" 803 "Gill Sensors" 811 "Blue Water Desalination" 815 "FLIR" 824 "Undheim Systems" 826 "Lewmar" 838 "TeamSurv" 844 "Fell Marine" 847 "Oceanvolt" 862 "Prospec" 868 "Data Panel" 890 "L3 Technologies" 894 "Rhodan Marine Systems" 896 "Nexfour Solutions" 905 "ASA Electronics" 909 "Marines Co (South Korea)" 911 "Nautic-on" 917 "Sentinel" 929 "JL Marine Systems" 930 "Ecotronix" 944 "Zontisa Marine" 951 "EXOR International" 962 "Timbolier Industries" 963 "TJC Micro" 968 "Cox Powertrain" 969 "Blue Seas" 981 "Kobelt Manufacturing" 992 "Blue Ocean IOT" 997 "Xenta Systems" 999 "Signal K" 1004 "Ultraflex" 1008 "Lintest SmartBoat" 1011 "Soundmax" 1020 "Team Italia Marine (Onyx Marine Automation s.r.l)" 1021 "Entratech" 1022 "ITC" 1029 "The Marine Guardian" 1047 "Sonic" 1051 "ProNav" 1053 "Vetus Maxwell INC." 1056 "Lithium Pros" 1059 "Boatrax" 1062 "Marol Co ltd" 1065 "CALYPSO Instruments" 1066 "Spot Zero Water" 1069 "Lithionics Battery" 1070 "Quick-teck Electronics" 1075 "Uniden America" 1083 "Nauticoncept" 1084 "Shadow-Caster LED lighting" 1085 "Wet Sounds" 1088 "E-T-A Circuit Breakers" 1092 "Scheiber" 1100 "Smart Yachts International Limited" 1109 "Dockmate" 1114 "Bobs Machine" 1118 "L3Harris ASV" 1119 "Balmar" 1120 "Elettromedia" 1127 "Electromaax" 1140 "Across Oceans Systems" 1145 "Kiwi Yachting" 1150 "BSB Artificial Intelligence" 1151 "Orca Technologies" 1154 "TBS Electronics" 1158 "Technoton Electroics" 1160 "MG Energy Systems" 1169 "Sea Machine Robotics" 1171 "Vista Manufacturing" 1183 "Zipwake" 1186 "Sailmon" 1192 "Airmoniq Pro Kft" 1194 "Sierra Marine" 1200 "Xinuo Information Technology (Xiamen)" 1218 "Septentrio" 1233 "NKE Marine Electronics" 1238 "SuperTrack Aps" 1239 "Honda Electronics" 1245 "Raritan Engineering" 1249 "Integrated Power Solutions AG" 1260 "Interactive Technologies" 1283 "LTG-Tech" 1299 "Energy Solutions (UK)" 1300 "WATT Fuel Cell" 1302 "Pro Mainer" 1305 "Dragonfly Energy" 1306 "Koden Electronics" 1311 "Humphree" 1316 "Hinkley Yachts" 1317 "Global Marine Management GmbH (GMM)" 1320 "Triskel Marine" 1330 "Warwick Control Technologies" 1331 "Dolphin Charger" 1337 "Barnacle Systems" 1348 "Radian IoT" 1353 "Ocean LED Marine" 1359 "BluNav" 1361 "OVA (Nantong Saiyang Electronics Co., Ltd)" 1368 "RAD Propulsion" 1369 "Electric Yacht" 1372 "Elco Motor Yachts" 1384 "Tecnoseal Foundry S.r.l" 1385 "Pro Charging Systems" 1389 "EVEX" 1398 "Gobius Sensor Technology" 1403 "Arco Marine" 1408 "Lenco Marine" 1413 "Naocontrol" 1417 "Revatek" 1438 "Aeolionics" 1439 "PredictWind" 1440 "Egis Mobile Electric" 1445 "Starboard Yacht Group" 1446 "Roswell Marine" 1451 "ePropulsion (Guangdong ePropulsion Technology Ltd.)" 1452 "Micro-Air" 1453 "Vital Battery" 1458 "Ride Controller" 1460 "Tocaro Blue" 1461 "Vanquish Yachts" 1471 "FT Technologies" 1478 "Alps Alpine" 1481 "E-Force Marine" 1482 "CMC Marine" 1483 "Nanjing Sandemarine Information Technology" 1850 "Teleflex Marine (SeaStar Solutions)" 1851 "Raymarine" 1852 "Navionics" 1853 "Japan Radio" 1854 "Northstar Technologies" 1855 "Furuno" 1856 "Trimble" 1857 "Simrad" 1858 "Litton" 1859 "Kvasar" 1860 "MMP" 1861 "Vector Cantech" 1862 "Yamaha Marine" 1863 "Faria Instruments" ;
VAL_ 2566854400 Industry_Code 0 "Global" 1 "Highway" 2 "Agriculture" 3 "Construction" 4 "Marine Industry" 5 "Industrial" ;
VAL_ 2566854656 Manufacturer_Code 69 "ARKS Enterprises" 78 "FW Murphy/Enovation Controls" 80 "Twin Disc" 85 "Kohler Power Systems" 88 "Hemisphere GPS" 135 "Airmar" 137 "Maretron" 140 "Lowrance" 144 "Mercury Marine" 147 "Nautibus Electronic" 148 "Blue Water Data" 154 "Westerbeke" 157 "ISSPRO" 161 "Offshore Systems (UK)" 163 "Evinrude/BRP" 165 "CPAC Systems" 168 "Xantrex Technology" 169 "Marlin Technologies" 172 "Yanmar Marine" 174 "Volvo Penta" 176 "Carling Technologies Inc. (Moritz Aerospace)" 185 "Beede Instruments" 192 "Floscan Instrument" 193 "Nobeltec" 198 "Mystic Valley Communications" 199 "Actia" 201 "Disenos Y Technologia" 211 "Digital Switching Systems" 215 "Xintex/Atena" 224 "EMMI NETWORK" 228 "ZF" 229 "Garmin" 233 "Yacht Monitoring Solutions" 235 "Sailormade Marine Telemetry/Tetra Technology" 243 "Eride" 257 "Honda Motor" 272 "Groco" 273 "Actisense" 274 "Amphenol LTW Technology" 275 "Navico" 283 "Hamilton Jet" 285 "Sea Recovery" 286 "Coelmo SRL Italy" 295 "BEP Marine" 304 "Empir Bus" 305 "NovAtel" 306 "Sleipner Motor" 307 "MBW Technologies" 315 "ICOM" 328 "Qwerty" 329 "Dief" 341 "Boening Automationstechnologie" 345 "Korean Maritime University" 351 "Thrane and Thrane" 355 "Mastervolt" 356 "Fischer Panda Generators" 358 "Victron Energy" 370 "Rolls Royce Marine" 373 "Electronic Design" 374 "Northern Lights" 378 "Glendinning" 381 "B & G" 384 "Rose Point Navigation Systems" 385 "Johnson Outdoors Marine Electronics Inc Geonav" 394 "Capi 2" 396 "Beyond Measure" 400 "Livorsi Marine" 404 "ComNav" 409 "Chetco" 419 "Fusion Electronics" 421 "Standard Horizon" 422 "True Heading" 426 "Egersund Marine Electronics" 427 "em-trak Marine Electronics" 431 "Tohatsu Co, JP" 437 "Digital Yacht" 438 "Comar Systems Limited" 440 "Cummins" 443 "VDO (aka Continental-Corporation)" 451 "Parker Hannifin aka Village Marine Tech" 459 "Alltek Marine Electronics" 460 "SAN GIORGIO S.E.I.N" 466 "Veethree Electronics & Marine" 470 "SI-TEX Marine Electronics" 471 "Sea Cross Marine" 475 "GME aka Standard Communications" 476 "Humminbird Marine Electronics" 478 "Ocean Sat" 481 "Chetco Digital Instruments" 493 "Watcheye" 499 "Lcj Capteurs" 502 "Attwood Marine" 503 "Naviop S.R.L." 504 "Vesper Marine" 510 "Marinesoft" 513 "Simarine" 517 "NoLand Engineering" 518 "Transas USA" 529 "National Instruments Korea" 530 "National Marine Electronics Association" 532 "Onwa Marine" 540 "Webasto" 571 "Marinecraft (South Korea)" 573 "McMurdo Group aka Orolia" 578 "Advansea" 579 "KVH" 580 "San Jose Technology" 583 "Yacht Control" 586 "Suzuki Motor" 591 "US Coast Guard" 595 "Ship Module aka Customware" 600 "Aquatic AV" 605 "Aventics" 606 "Intellian" 612 "SamwonIT" 614 "Arlt Tecnologies" 637 "Bavaria Yachts" 641 "Diverse Yacht Services" 644 "Wema U.S.A dba KUS" 658 "Shenzhen Jiuzhou Himunication" 688 "Rockford" 699 "Harman International" 704 "JL Audio" 708 "Lars Thrane" 715 "Autonnic" 717 "Yacht Devices" 734 "REAP Systems" 735 "AEM Performance Electronics" 739 "LxNav" 741 "Littelfuse, Inc (formerly Carling Technologies)" 743 "DaeMyung" 744 "Woosung" 748 "ISOTTA IFRA srl" 773 "Clarion US" 776 "HMI Systems" 777 "Ocean Signal" 778 "Seakeeper" 781 "Poly Planar" 785 "Fischer Panda DE" 795 "Broyda Industries" 796 "Canadian Automotive" 797 "Tides Marine" 798 "Lumishore" 799 "Still Water Designs and Audio" 802 "BJ Technologies (Beneteau)" 803 "Gill Sensors" 811 "Blue Water Desalination" 815 "FLIR" 824 "Undheim Systems" 826 "Lewmar" 838 "TeamSurv" 844 "Fell Marine" 847 "Oceanvolt" 862 "Prospec" 868 "Data Panel" 890 "L3 Technologies" 894 "Rhodan Marine Systems" 896 "Nexfour Solutions" 905 "ASA Electronics" 909 "Marines Co (South Korea)" 911 "Nautic-on" 917 "Sentinel" 929 "JL Marine Systems" 930 "Ecotronix" 944 "Zontisa Marine" 951 "EXOR International" 962 "Timbolier Industries" 963 "TJC Micro" 968 "Cox Powertrain" 969 "Blue Seas" 981 "Kobelt Manufacturing" 992 "Blue Ocean IOT" 997 "Xenta Systems" 999 "Signal K" 1004 "Ultraflex" 1008 "Lintest SmartBoat" 1011 "Soundmax" 1020 "Team Italia Marine (Onyx Marine Automation s.r.l)" 1021 "Entratech" 1022 "ITC" 1029 "The Marine Guardian" 1047 "Sonic" 1051 "ProNav" 1053 "Vetus Maxwell INC." 1056 "Lithium Pros" 1059 "Boatrax" 1062 "Marol Co ltd" 1065 "CALYPSO Instruments" 1066 "Spot Zero Water" 1069 "Lithionics Battery" 1070 "Quick-teck Electronics" 1075 "Uniden America" 1083 "Nauticoncept" 1084 "Shadow-Caster LED lighting" 1085 "Wet Sounds" 1088 "E-T-A Circuit Breakers" 1092 "Scheiber" 1100 "Smart Yachts International Limited" 1109 "Dockmate" 1114 "Bobs Machine" 1118 "L3Harris ASV" 1119 "Balmar" 1120 "Elettromedia" 1127 "Electromaax" 1140 "Across Oceans Systems" 1145 "Kiwi Yachting" 1150 "BSB Artificial Intelligence" 1151 "Orca Technologies" 1154 "TBS Electronics" 1158 "Technoton Electroics" 1160 "MG Energy Systems" 1169 "Sea Machine Robotics" 1171 "Vista Manufacturing" 1183 "Zipwake" 1186 "Sailmon" 1192 "Airmoniq Pro Kft" 1194 "Sierra Marine" 1200 "Xinuo Information Technology (Xiamen)" 1218 "Septentrio" 1233 "NKE Marine Electronics" 1238 "SuperTrack Aps" 1239 "Honda Electronics" 1245 "Raritan Engineering" 1249 "Integrated Power Solutions AG" 1260 "Interactive Technologies" 1283 "LTG-Tech" 1299 "Energy Solutions (UK)" 1300 "WATT Fuel Cell" 1302 "Pro Mainer" 1305 "Dragonfly Energy" 1306 "Koden Electronics" 1311 "Humphree" 1316 "Hinkley Yachts" 1317 "Global Marine Management GmbH (GMM)" 1320 "Triskel Marine" 1330 "Warwick Control Technologies" 1331 "Dolphin Charger" 1337 "Barnacle Systems" 1348 "Radian IoT" 1353 "Ocean LED Marine" 1359 "BluNav" 1361 "OVA (Nantong Saiyang Electronics Co., Ltd)" 1368 "RAD Propulsion" 1369 "Electric Yacht" 1372 "Elco Motor Yachts" 1384 "Tecnoseal Foundry S.r.l" 1385 "Pro Charging Systems" 1389 "EVEX" 1398 "Gobius Sensor Technology" 1403 "Arco Marine" 1408 "Lenco Marine" 1413 "Naocontrol" 1417 "Revatek" 1438 "Aeolionics" 1439 "PredictWind" 1440 "Egis Mobile Electric" 1445 "Starboard Yacht Group" 1446 "Roswell Marine" 1451 "ePropulsion (Guangdong ePropulsion Technology Ltd.)" 1452 "Micro-Air" 1453 "Vital Battery" 1458 "Ride Controller" 1460 "Tocaro Blue" 1461 "Vanquish Yachts" 1471 "FT Technologies" 1478 "Alps Alpine" 1481 "E-Force Marine" 1482 "CMC Marine" 1483 "Nanjing Sandemarine Information Technology" 1850 "Teleflex Marine (SeaStar Solutions)" 1851 "Raymarine" 1852 "Navionics" 1853 "Japan Radio" 1854 "Northstar Technologies" 1855 "Furuno" 1856 "Trimble" 1857 "Simrad" 1858 "Litton" 1859 "Kvasar" 1860 "MMP" 1861 "Vector Cantech" 1862 "Yamaha Marine" 1863 "Faria Instruments" ;
VAL_ 2566854656 Industry_Code 0 "Global" 1 "Highway" 2 "Agriculture" 3 "Construction" 4 "Marine Industry" 5 "Industrial" ;
VAL_ 2566854656 Manufacturer_Code 69 "ARKS Enterprises" 78 "FW Murphy/Enovation Controls" 80 "Twin Disc" 85 "Kohler Power Systems" 88 "Hemisphere GPS" 135 "Airmar" 137 "Maretron" 140 "Lowrance" 144 "Mercury Marine" 147 "Nautibus Electronic" 148 "Blue Water Data" 154 "Westerbeke" 157 "ISSPRO" 161 "Offshore Systems (UK)" 163 "Evinrude/BRP" 165 "CPAC Systems" 168 "Xantrex Technology" 169 "Marlin Technologies" 172 "Yanmar Marine" 174 "Volvo Penta" 176 "Carling Technologies Inc. (Moritz Aerospace)" 185 "Beede Instruments" 192 "Floscan Instrument" 193 "Nobeltec" 198 "Mystic Valley Communications" 199 "Actia" 201 "Disenos Y Technologia" 211 "Digital Switching Systems" 215 "Xintex/Atena" 224 "EMMI NETWORK" 228 "ZF" 229 "Garmin" 233 "Yacht Monitoring Solutions" 235 "Sailormade Marine Telemetry/Tetra Technology" 243 "Eride" 257 "Honda Motor" 272 "Groco" 273 "Actisense" 274 "Amphenol LTW Technology" 275 "Navico" 283 "Hamilton Jet" 285 "Sea Recovery" 286 "Coelmo SRL Italy" 295 "BEP Marine" 304 "Empir Bus" 305 "NovAtel" 306 "Sleipner Motor" 307 "MBW Technologies" 315 "ICOM" 328 "Qwerty" 329 "Dief" 341 "Boening Automationstechnologie" 345 "Korean Maritime University" 351 "Thrane and Thrane" 355 "Mastervolt" 356 "Fischer Panda Generators" 358 "Victron Energy" 370 "Rolls Royce Marine" 373 "Electronic Design" 374 "Northern Lights" 378 "Glendinning" 381 "B & G" 384 "Rose Point Navigation Systems" 385 "Johnson Outdoors Marine Electronics Inc Geonav" 394 "Capi 2" 396 "Beyond Measure" 400 "Livorsi Marine" 404 "ComNav" 409 "Chetco" 419 "Fusion Electronics" 421 "Standard Horizon" 422 "True Heading" 426 "Egersund Marine Electronics" 427 "em-trak Marine Electronics" 431 "Tohatsu Co, JP" 437 "Digital Yacht" 438 "Comar Systems Limited" 440 "Cummins" 443 "VDO (aka Continental-Corporation)" 451 "Parker Hannifin aka Village Marine Tech" 459 "Alltek Marine Electronics" 460 "SAN GIORGIO S.E.I.N" 466 "Veethree Electronics & Marine" 470 "SI-TEX Marine Electronics" 471 "Sea Cross Marine" 475 "GME aka Standard Communications" 476 "Humminbird Marine Electronics" 478 "Ocean Sat" 481 "Chetco Digital Instruments" 493 "Watcheye" 499 "Lcj Capteurs" 502 "Attwood Marine" 503 "Naviop S.R.L." 504 "Vesper Marine" 510 "Marinesoft" 513 "Simarine" 517 "NoLand Engineering" 518 "Transas USA" 529 "National Instruments Korea" 530 "National Marine Electronics Association" 532 "Onwa Marine" 540 "Webasto" 571 "Marinecraft (South Korea)" 573 "McMurdo Group aka Orolia" 578 "Advansea" 579 "KVH" 580 "San Jose Technology" 583 "Yacht Control" 586 "Suzuki Motor" 591 "US Coast Guard" 595 "Ship Module aka Customware" 600 "Aquatic AV" 605 "Aventics" 606 "Intellian" 612 "SamwonIT" 614 "Arlt Tecnologies" 637 "Bavaria Yachts" 641 "Diverse Yacht Services" 644 "Wema U.S.A dba KUS" 658 "Shenzhen Jiuzhou Himunication" 688 "Rockford" 699 "Harman International" 704 "JL Audio" 708 "Lars Thrane" 715 "Autonnic" 717 "Yacht Devices" 734 "REAP Systems" 735 "AEM Performance Electronics" 739 "LxNav" 741 "Littelfuse, Inc (formerly Carling Technologies)" 743 "DaeMyung" 744 "Woosung" 748 "ISOTTA IFRA srl" 773 "Clarion US" 776 "HMI Systems" 777 "Ocean Signal" 778 "Seakeeper" 781 "Poly Planar" 785 "Fischer Panda DE" 795 "Broyda Industries" 796 "Canadian Automotive" 797 "Tides Marine" 798 "Lumishore" 799 "Still Water Designs and Audio" 802 "BJ Technologies (Beneteau)" 803 "Gill Sensors" 811 "Blue Water Desalination" 815 "FLIR" 824 "Undheim Systems" 826 "Lewmar" 838 "TeamSurv" 844 "Fell Marine" 847 "Oceanvolt" 862 "Prospec" 868 "Data Panel" 890 "L3 Technologies" 894 "Rhodan Marine Systems" 896 "Nexfour Solutions" 905 "ASA Electronics" 909 "Marines Co (South Korea)" 911 "Nautic-on" 917 "Sentinel" 929 "JL Marine Systems" 930 "Ecotronix" 944 "Zontisa Marine" 951 "EXOR International" 962 "Timbolier Industries" 963 "TJC Micro" 968 "Cox Powertrain" 969 "Blue Seas" 981 "Kobelt Manufacturing" 992 "Blue Ocean IOT" 997 "Xenta Systems" 999 "Signal K" 1004 "Ultraflex" 1008 "Lintest SmartBoat" 1011 "Soundmax" 1020 "Team Italia Marine (Onyx Marine Automation s.r.l)" 1021 "Entratech" 1022 "ITC" 1029 "The Marine Guardian" 1047 "Sonic" 1051 "ProNav" 1053 "Vetus Maxwell INC." 1056 "Lithium Pros" 1059 "Boatrax" 1062 "Marol Co ltd" 1065 "CALYPSO Instruments" 1066 "Spot Zero Water" 1069 "Lithionics Battery" 1070 "Quick-teck Electronics" 1075 "Uniden America" 1083 "Nauticoncept" 1084 "Shadow-Caster LED lighting" 1085 "Wet Sounds" 1088 "E-T-A Circuit Breakers" 1092 "Scheiber" 1100 "Smart Yachts International Limited" 1109 "Dockmate" 1114 "Bobs Machine" 1118 "L3Harris ASV" 1119 "Balmar" 1120 "Elettromedia" 1127 "Electromaax" 1140 "Across Oceans Systems" 1145 "Kiwi Yachting" 1150 "BSB Artificial Intelligence" 1151 "Orca Technologies" 1154 "TBS Electronics" 1158 "Technoton Electroics" 1160 "MG Energy Systems" 1169 "Sea Machine Robotics" 1171 "Vista Manufacturing" 1183 "Zipwake" 1186 "Sailmon" 1192 "Airmoniq Pro Kft" 1194 "Sierra Marine" 1200 "Xinuo Information Technology (Xiamen)" 1218 "Septentrio" 1233 "NKE Marine Electronics" 1238 "SuperTrack Aps" 1239 "Honda Electronics" 1245 "Raritan Engineering" 1249 "Integrated Power Solutions AG" 1260 "Interactive Technologies" 1283 "LTG-Tech" 1299 "Energy Solutions (UK)" 1300 "WATT Fuel Cell" 1302 "Pro Mainer" 1305 "Dragonfly Energy" 1306 "Koden Electronics" 1311 "Humphree" 1316 "Hinkley Yachts" 1317 "Global Marine Management GmbH (GMM)" 1320 "Triskel Marine" 1330 "Warwick Control Technologies" 1331 "Dolphin Charger" 1337 "Barnacle Systems" 1348 "Radian IoT" 1353 "Ocean LED Marine" 1359 "BluNav" 1361 "OVA (Nantong Saiyang Electronics Co., Ltd)" 1368 "RAD Propulsion" 1369 "Electric Yacht" 1372 "Elco Motor Yachts" 1384 "Tecnoseal Foundry S.r.l" 1385 "Pro Charging Systems" 1389 "EVEX" 1398 "Gobius Sensor Technology" 1403 "Arco Marine" 1408 "Lenco Marine" 1413 "Naocontrol" 1417 "Revatek" 1438 "Aeolionics" 1439 "PredictWind" 1440 "Egis Mobile Electric" 1445 "Starboard Yacht Group" 1446 "Roswell Marine" 1451 "ePropulsion (Guangdong ePropulsion Technology Ltd.)" 1452 "Micro-Air" 1453 "Vital Battery" 1458 "Ride Controller" 1460 "Tocaro Blue" 1461 "Vanquish Yachts" 1471 "FT Technologies" 1478 "Alps Alpine" 1481 "E-Force Marine" 1482 "CMC Marine" 1483 "Nanjing Sandemarine Information Technology" 1850 "Teleflex Marine (SeaStar Solutions)" 1851 "Raymarine" 1852 "Navionics" 1853 "Japan Radio" 1854 "Northstar Technologies" 1855 "Furuno" 1856 "Trimble" 1857 "Simrad" 1858 "Litton" 1859 "Kvasar" 1860 "MMP" 1861 "Vector Cantech" 1862 "Yamaha Marine" 1863 "Faria Instruments" ;
VAL_ 2566854656 Industry_Code 0 "Global" 1 "Highway" 2 "Agriculture" 3 "Construction" 4 "Marine Industry" 5 "Industrial" ;
VAL_ 2566854656 Manufacturer_Code 69 "ARKS Enterprises" 78 "FW Murphy/Enovation Controls" 80 "Twin Disc" 85 "Kohler Power Systems" 88 "Hemisphere GPS" 135 "Airmar" 137 "Maretron" 140 "Lowrance" 144 "Mercury Marine" 147 "Nautibus Electronic" 148 "Blue Water Data" 154 "Westerbeke" 157 "ISSPRO" 161 "Offshore Systems (UK)" 163 "Evinrude/BRP" 165 "CPAC Systems" 168 "Xantrex Technology" 169 "Marlin Technologies" 172 "Yanmar Marine" 174 "Volvo Penta" 176 "Carling Technologies Inc. (Moritz Aerospace)" 185 "Beede Instruments" 192 "Floscan Instrument" 193 "Nobeltec" 198 "Mystic Valley Communications" 199 "Actia" 201 "Disenos Y Technologia" 211 "Digital Switching Systems" 215 "Xintex/Atena" 224 "EMMI NETWORK" 228 "ZF" 229 "Garmin" 233 "Yacht Monitoring Solutions" 235 "Sailormade Marine Telemetry/Tetra Technology" 243 "Eride" 257 "Honda Motor" 272 "Groco" 273 "Actisense" 274 "Amphenol LTW Technology" 275 "Navico" 283 "Hamilton Jet" 285 "Sea Recovery" 286 "Coelmo SRL Italy" 295 "BEP Marine" 304 "Empir Bus" 305 "NovAtel" 306 "Sleipner Motor" 307 "MBW Technologies" 315 "ICOM" 328 "Qwerty" 329 "Dief" 341 "Boening Automationstechnologie" 345 "Korean Maritime University" 351 "Thrane and Thrane" 355 "Mastervolt" 356 "Fischer Panda Generators" 358 "Victron Energy" 370 "Rolls Royce Marine" 373 "Electronic Design" 374 "Northern Lights" 378 "Glendinning" 381 "B & G" 384 "Rose Point Navigation Systems" 385 "Johnson Outdoors Marine Electronics Inc Geonav" 394 "Capi 2" 396 "Beyond Measure" 400 "Livorsi Marine" 404 "ComNav" 409 "Chetco" 419 "Fusion Electronics" 421 "Standard Horizon" 422 "True Heading" 426 "Egersund Marine Electronics" 427 "em-trak Marine Electronics" 431 "Tohatsu Co, JP" 437 "Digital Yacht" 438 "Comar Systems Limited" 440 "Cummins" 443 "VDO (aka Continental-Corporation)" 451 "Parker Hannifin aka Village Marine Tech" 459 "Alltek Marine Electronics" 460 "SAN GIORGIO S.E.I.N" 466 "Veethree Electronics & Marine" 470 "SI-TEX Marine Electronics" 471 "Sea Cross Marine" 475 "GME aka Standard Communications" 476 "Humminbird Marine Electronics" 478 "Ocean Sat" 481 "Chetco Digital Instruments" 493 "Watcheye" 499 "Lcj Capteurs" 502 "Attwood Marine" 503 "Naviop S.R.L." 504 "Vesper Marine" 510 "Marinesoft" 513 "Simarine" 517 "NoLand Engineering" 518 "Transas USA" 529 "National Instruments Korea" 530 "National Marine Electronics Association" 532 "Onwa Marine" 540 "Webasto" 571 "Marinecraft (South Korea)" 573 "McMurdo Group aka Orolia" 578 "Advansea" 579 "KVH" 580 "San Jose Technology" 583 "Yacht Control" 586 "Suzuki Motor" 591 "US Coast Guard" 595 "Ship Module aka Customware" 600 "Aquatic AV" 605 "Aventics" 606 "Intellian" 612 "SamwonIT" 614 "Arlt Tecnologies" 637 "Bavaria Yachts" 641 "Diverse Yacht Services" 644 "Wema U.S.A dba KUS" 658 "Shenzhen Jiuzhou Himunication" 688 "Rockford" 699 "Harman International" 704 "JL Audio" 708 "Lars Thrane" 715 "Autonnic" 717 "Yacht Devices" 734 "REAP Systems" 735 "AEM Performance Electronics" 739 "LxNav" 741 "Littelfuse, Inc (formerly Carling Technologies)" 743 "DaeMyung" 744 "Woosung" 748 "ISOTTA IFRA srl" 773 "Clarion US" 776 "HMI Systems" 777 "Ocean Signal" 778 "Seakeeper" 781 "Poly Planar" 785 "Fischer Panda DE" 795 "Broyda Industries" 796 "Canadian Automotive" 797 "Tides Marine" 798 "Lumishore" 799 "Still Water Designs and Audio" 802 "BJ Technologies (Beneteau)" 803 "Gill Sensors" 811 "Blue Water Desalination" 815 "FLIR" 824 "Undheim Systems" 826 "Lewmar" 838 "TeamSurv" 844 "Fell Marine" 847 "Oceanvolt" 862 "Prospec" 868 "Data Panel" 890 "L3 Technologies" 894 "Rhodan Marine Systems" 896 "Nexfour Solutions" 905 "ASA Electronics" 909 "Marines Co (South Korea)" 911 "Nautic-on" 917 "Sentinel" 929 "JL Marine Systems" 930 "Ecotronix" 944 "Zontisa Marine" 951 "EXOR International" 962 "Timbolier Industries" 963 "TJC Micro" 968 "Cox Powertrain" 969 "Blue Seas" 981 "Kobelt Manufacturing" 992 "Blue Ocean IOT" 997 "Xenta Systems" 999 "Signal K" 1004 "Ultraflex" 1008 "Lintest SmartBoat" 1011 "Soundmax" 1020 "Team Italia Marine (Onyx Marine Automation s.r.l)" 1021 "Entratech" 1022 "ITC" 1029 "The Marine Guardian" 1047 "Sonic" 1051 "ProNav" 1053 "Vetus Maxwell INC." 1056 "Lithium Pros" 1059 "Boatrax" 1062 "Marol Co ltd" 1065 "CALYPSO Instruments" 1066 "Spot Zero Water" 1069 "Lithionics Battery" 1070 "Quick-teck Electronics" 1075 "Uniden America" 1083 "Nauticoncept" 1084 "Shadow-Caster LED lighting" 1085 "Wet Sounds" 1088 "E-T-A Circuit Breakers" 1092 "Scheiber" 1100 "Smart Yachts International Limited" 1109 "Dockmate" 1114 "Bobs Machine" 1118 "L3Harris ASV" 1119 "Balmar" 1120 "Elettromedia" 1127 "Electromaax" 1140 "Across Oceans Systems" 1145 "Kiwi Yachting" 1150 "BSB Artificial Intelligence" 1151 "Orca Technologies" 1154 "TBS Electronics" 1158 "Technoton Electroics" 1160 "MG Energy Systems" 1169 "Sea Machine Robotics" 1171 "Vista Manufacturing" 1183 "Zipwake" 1186 "Sailmon" 1192 "Airmoniq Pro Kft" 1194 "Sierra Marine" 1200 "Xinuo Information Technology (Xiamen)" 1218 "Septentrio" 1233 "NKE Marine Electronics" 1238 "SuperTrack Aps" 1239 "Honda Electronics" 1245 "Raritan Engineering" 1249 "Integrated Power Solutions AG" 1260 "Interactive Technologies" 1283 "LTG-Tech" 1299 "Energy Solutions (UK)" 1300 "WATT Fuel Cell" 1302 "Pro Mainer" 1305 "Dragonfly Energy" 1306 "Koden Electronics" 1311 "Humphree" 1316 "Hinkley Yachts" 1317 "Global Marine Management GmbH (GMM)" 1320 "Triskel Marine" 1330 "Warwick Control Technologies" 1331 "Dolphin Charger" 1337 "Barnacle Systems" 1348 "Radian IoT" 1353 "Ocean LED Marine" 1359 "BluNav" 1361 "OVA (Nantong Saiyang Electronics Co., Ltd)" 1368 "RAD Propulsion" 1369 "Electric Yacht" 1372 "Elco Motor Yachts" 1384 "Tecnoseal Foundry S.r.l" 1385 "Pro Charging Systems" 1389 "EVEX" 1398 "Gobius Sensor Technology" 1403 "Arco Marine" 1408 "Lenco Marine" 1413 "Naocontrol" 1417 "Revatek" 1438 "Aeolionics" 1439 "PredictWind" 1440 "Egis Mobile Electric" 1445 "Starboard Yacht Group" 1446 "Roswell Marine" 1451 "ePropulsion (Guangdong ePropulsion Technology Ltd.)" 1452 "Micro-Air" 1453 "Vital Battery" 1458 "Ride Controller" 1460 "Tocaro Blue" 1461 "Vanquish Yachts" 1471 "FT Technologies" 1478 "Alps Alpine" 1481 "E-Force Marine" 1482 "CMC Marine" 1483 "Nanjing Sandemarine Information Technology" 1850 "Teleflex Marine (SeaStar Solutions)" 1851 "Raymarine" 1852 "Navionics" 1853 "Japan Radio" 1854 "Northstar Technologies" 1855 "Furuno" 1856 "Trimble" 1857 "Simrad" 1858 "Litton" 1859 "Kvasar" 1860 "MMP" 1861 "Vector Cantech" 1862 "Yamaha Marine" 1863 "Faria Instruments" ;
VAL_ 2566854656 Industry_Code 0 "Global" 1 "Highway" 2 "Agriculture" 3 "Construction" 4 "Marine Industry" 5 "Industrial" ;
VAL_ 2566854656 Manufacturer_Code 69 "ARKS Enterprises" 78 "FW Murphy/Enovation Controls" 80 "Twin Disc" 85 "Kohler Power Systems" 88 "Hemisphere GPS" 135 "Airmar" 137 "Maretron" 140 "Lowrance" 144 "Mercury Marine" 147 "Nautibus Electronic" 148 "Blue Water Data" 154 "Westerbeke" 157 "ISSPRO" 161 "Offshore Systems (UK)" 163 "Evinrude/BRP" 165 "CPAC Systems" 168 "Xantrex Technology" 169 "Marlin Technologies" 172 "Yanmar Marine" 174 "Volvo Penta" 176 "Carling Technologies Inc. (Moritz Aerospace)" 185 "Beede Instruments" 192 "Floscan Instrument" 193 "Nobeltec" 198 "Mystic Valley Communications" 199 "Actia" 201 "Disenos Y Technologia" 211 "Digital Switching Systems" 215 "Xintex/Atena" 224 "EMMI NETWORK" 228 "ZF" 229 "Garmin" 233 "Yacht Monitoring Solutions" 235 "Sailormade Marine Telemetry/Tetra Technology" 243 "Eride" 257 "Honda Motor" 272 "Groco" 273 "Actisense" 274 "Amphenol LTW Technology" 275 "Navico" 283 "Hamilton Jet" 285 "Sea Recovery" 286 "Coelmo SRL Italy" 295 "BEP Marine" 304 "Empir Bus" 305 "NovAtel" 306 "Sleipner Motor" 307 "MBW Technologies" 315 "ICOM" 328 "Qwerty" 329 "Dief" 341 "Boening Automationstechnologie" 345 "Korean Maritime University" 351 "Thrane and Thrane" 355 "Mastervolt" 356 "Fischer Panda Generators" 358 "Victron Energy" 370 "Rolls Royce Marine" 373 "Electronic Design" 374 "Northern Lights" 378 "Glendinning" 381 "B & G" 384 "Rose Point Navigation Systems" 385 "Johnson Outdoors Marine Electronics Inc Geonav" 394 "Capi 2" 396 "Beyond Measure" 400 "Livorsi Marine" 404 "ComNav" 409 "Chetco" 419 "Fusion Electronics" 421 "Standard Horizon" 422 "True Heading" 426 "Egersund Marine Electronics" 427 "em-trak Marine Electronics" 431 "Tohatsu Co, JP" 437 "Digital Yacht" 438 "Comar Systems Limited" 440 "Cummins" 443 "VDO (aka Continental-Corporation)" 451 "Parker Hannifin aka Village Marine Tech" 459 "Alltek Marine Electronics" 460 "SAN GIORGIO S.E.I.N" 466 "Veethree Electronics & Marine" 470 "SI-TEX Marine Electronics" 471 "Sea Cross Marine" 475 "GME aka Standard Communications" 476 "Humminbird Marine Electronics" 478 "Ocean Sat" 481 "Chetco Digital Instruments" 493 "Watcheye" 499 "Lcj Capteurs" 502 "Attwood Marine" 503 "Naviop S.R.L." 504 "Vesper Marine" 510 "Marinesoft" 513 "Simarine" 517 "NoLand Engineering" 518 "Transas USA" 529 "National Instruments Korea" 530 "National Marine Electronics Association" 532 "Onwa Marine" 540 "Webasto" 571 "Marinecraft (South Korea)" 573 "McMurdo Group aka Orolia" 578 "Advansea" 579 "KVH" 580 "San Jose Technology" 583 "Yacht Control" 586 "Suzuki Motor" 591 "US Coast Guard" 595 "Ship Module aka Customware" 600 "Aquatic AV" 605 "Aventics" 606 "Intellian" 612 "SamwonIT" 614 "Arlt Tecnologies" 637 "Bavaria Yachts" 641 "Diverse Yacht Services" 644 "Wema U.S.A dba KUS" 658 "Shenzhen Jiuzhou Himunication" 688 "Rockford" 699 "Harman International" 704 "JL Audio" 708 "Lars Thrane" 715 "Autonnic" 717 "Yacht Devices" 734 "REAP Systems" 735 "AEM Performance Electronics" 739 "LxNav" 741 "Littelfuse, Inc (formerly Carling Technologies)" 743 "DaeMyung" 744 "Woosung" 748 "ISOTTA IFRA srl" 773 "Clarion US" 776 "HMI Systems" 777 "Ocean Signal" 778 "Seakeeper" 781 "Poly Planar" 785 "Fischer Panda DE" 795 "Broyda Industries" 796 "Canadian Automotive" 797 "Tides Marine" 798 "Lumishore" 799 "Still Water Designs and Audio" 802 "BJ Technologies (Beneteau)" 803 "Gill Sensors" 811 "Blue Water Desalination" 815 "FLIR" 824 "Undheim Systems" 826 "Lewmar" 838 "TeamSurv" 844 "Fell Marine" 847 "Oceanvolt" 862 "Prospec" 868 "Data Panel" 890 "L3 Technologies" 894 "Rhodan Marine Systems" 896 "Nexfour Solutions" 905 "ASA Electronics" 909 "Marines Co (South Korea)" 911 "Nautic-on" 917 "Sentinel" 929 "JL Marine Systems" 930 "Ecotronix" 944 "Zontisa Marine" 951 "EXOR International" 962 "Timbolier Industries" 963 "TJC Micro" 968 "Cox Powertrain" 969 "Blue Seas" 981 "Kobelt Manufacturing" 992 "Blue Ocean IOT" 997 "Xenta Systems" 999 "Signal K" 1004 "Ultraflex" 1008 "Lintest SmartBoat" 1011 "Soundmax" 1020 "Team Italia Marine (Onyx Marine Automation s.r.l)" 1021 "Entratech" 1022 "ITC" 1029 "The Marine Guardian" 1047 "Sonic" 1051 "ProNav" 1053 "Vetus Maxwell INC." 1056 "Lithium Pros" 1059 "Boatrax" 1062 "Marol Co ltd" 1065 "CALYPSO Instruments" 1066 "Spot Zero Water" 1069 "Lithionics Battery" 1070 "Quick-teck Electronics" 1075 "Uniden America" 1083 "Nauticoncept" 1084 "Shadow-Caster LED lighting" 1085 "Wet Sounds" 1088 "E-T-A Circuit Breakers" 1092 "Scheiber" 1100 "Smart Yachts International Limited" 1109 "Dockmate" 1114 "Bobs Machine" 1118 "L3Harris ASV" 1119 "Balmar" 1120 "Elettromedia" 1127 "Electromaax" 1140 "Across Oceans Systems" 1145 "Kiwi Yachting" 1150 "BSB Artificial Intelligence" 1151 "Orca Technologies" 1154 "TBS Electronics" 1158 "Technoton Electroics" 1160 "MG Energy Systems" 1169 "Sea Machine Robotics" 1171 "Vista Manufacturing" 1183 "Zipwake" 1186 "Sailmon" 1192 "Airmoniq Pro Kft" 1194 "Sierra Marine" 1200 "Xinuo Information Technology (Xiamen)" 1218 "Septentrio" 1233 "NKE Marine Electronics" 1238 "SuperTrack Aps" 1239 "Honda Electronics" 1245 "Raritan Engineering" 1249 "Integrated Power Solutions AG" 1260 "Interactive Technologies" 1283 "LTG-Tech" 1299 "Energy Solutions (UK)" 1300 "WATT Fuel Cell" 1302 "Pro Mainer" 1305 "Dragonfly Energy" 1306 "Koden Electronics" 1311 "Humphree" 1316 "Hinkley Yachts" 1317 "Global Marine Management GmbH (GMM)" 1320 "Triskel Marine" 1330 "Warwick Control Technologies" 1331 "Dolphin Charger" 1337 "Barnacle Systems" 1348 "Radian IoT" 1353 "Ocean LED Marine" 1359 "BluNav" 1361 "OVA (Nantong Saiyang Electronics Co., Ltd)" 1368 "RAD Propulsion" 1369 "Electric Yacht" 1372 "Elco Motor Yachts" 1384 "Tecnoseal Foundry S.r.l" 1385 "Pro Charging Systems" 1389 "EVEX" 1398 "Gobius Sensor Technology" 1403 "Arco Marine" 1408 "Lenco Marine" 1413 "Naocontrol" 1417 "Revatek" 1438 "Aeolionics" 1439 "PredictWind" 1440 "Egis Mobile Electric" 1445 "Starboard Yacht Group" 1446 "Roswell Marine" 1451 "ePropulsion (Guangdong ePropulsion Technology Ltd.)" 1452 "Micro-Air" 1453 "Vital Battery" 1458 "Ride Controller" 1460 "Tocaro Blue" 1461 "Vanquish Yachts" 1471 "FT Technologies" 1478 "Alps Alpine" 1481 "E-Force Marine" 1482 "CMC Marine" 1483 "Nanjing Sandemarine Information Technology" 1850 "Teleflex Marine (SeaStar Solutions)" 1851 "Raymarine" 1852 "Navionics" 1853 "Japan Radio" 1854 "Northstar Technologies" 1855 "Furuno" 1856 "Trimble" 1857 "Simrad" 1858 "Litton" 1859 "Kvasar" 1860 "MMP" 1861 "Vector Cantech" 1862 "Yamaha Marine" 1863 "Faria Instruments" ;
VAL_ 2566854656 Industry_Code 0 "Global" 1 "Highway" 2 "Agriculture" 3 "Construction" 4 "Marine Industry" 5 "Industrial" ;
VAL_ 2566854912 Manufacturer_Code 69 "ARKS Enterprises" 78 "FW Murphy/Enovation Controls" 80 "Twin Disc" 85 "Kohler Power Systems" 88 "Hemisphere GPS" 135 "Airmar" 137 "Maretron" 140 "Lowrance" 144 "Mercury Marine" 147 "Nautibus Electronic" 148 "Blue Water Data" 154 "Westerbeke" 157 "ISSPRO" 161 "Offshore Systems (UK)" 163 "Evinrude/BRP" 165 "CPAC Systems" 168 "Xantrex Technology" 169 "Marlin Technologies" 172 "Yanmar Marine" 174 "Volvo Penta" 176 "Carling Technologies Inc. (Moritz Aerospace)" 185 "Beede Instruments" 192 "Floscan Instrument" 193 "Nobeltec" 198 "Mystic Valley Communications" 199 "Actia" 201 "Disenos Y Technologia" 211 "Digital Switching Systems" 215 "Xintex/Atena" 224 "EMMI NETWORK" 228 "ZF" 229 "Garmin" 233 "Yacht Monitoring Solutions" 235 "Sailormade Marine Telemetry/Tetra Technology" 243 "Eride" 257 "Honda Motor" 272 "Groco" 273 "Actisense" 274 "Amphenol LTW Technology" 275 "Navico" 283 "Hamilton Jet" 285 "Sea Recovery" 286 "Coelmo SRL Italy" 295 "BEP Marine" 304 "Empir Bus" 305 "NovAtel" 306 "Sleipner Motor" 307 "MBW Technologies" 315 "ICOM" 328 "Qwerty" 329 "Dief" 341 "Boening Automationstechnologie" 345 "Korean Maritime University" 351 "Thrane and Thrane" 355 "Mastervolt" 356 "Fischer Panda Generators" 358 "Victron Energy" 370 "Rolls Royce Marine" 373 "Electronic Design" 374 "Northern Lights" 378 "Glendinning" 381 "B & G" 384 "Rose Point Navigation Systems" 385 "Johnson Outdoors Marine Electronics Inc Geonav" 394 "Capi 2" 396 "Beyond Measure" 400 "Livorsi Marine" 404 "ComNav" 409 "Chetco" 419 "Fusion Electronics" 421 "Standard Horizon" 422 "True Heading" 426 "Egersund Marine Electronics" 427 "em-trak Marine Electronics" 431 "Tohatsu Co, JP" 437 "Digital Yacht" 438 "Comar Systems Limited" 440 "Cummins" 443 "VDO (aka Continental-Corporation)" 451 "Parker Hannifin aka Village Marine Tech" 459 "Alltek Marine Electronics" 460 "SAN GIORGIO S.E.I.N" 466 "Veethree Electronics & Marine" 470 "SI-TEX Marine Electronics" 471 "Sea Cross Marine" 475 "GME aka Standard Communications" 476 "Humminbird Marine Electronics" 478 "Ocean Sat" 481 "Chetco Digital Instruments" 493 "Watcheye" 499 "Lcj Capteurs" 502 "Attwood Marine" 503 "Naviop S.R.L." 504 "Vesper Marine" 510 "Marinesoft" 513 "Simarine" 517 "NoLand Engineering" 518 "Transas USA" 529 "National Instruments Korea" 530 "National Marine Electronics Association" 532 "Onwa Marine" 540 "Webasto" 571 "Marinecraft (South Korea)" 573 "McMurdo Group aka Orolia" 578 "Advansea" 579 "KVH" 580 "San Jose Technology" 583 "Yacht Control" 586 "Suzuki Motor" 591 "US Coast Guard" 595 "Ship Module aka Customware" 600 "Aquatic AV" 605 "Aventics" 606 "Intellian" 612 "SamwonIT" 614 "Arlt Tecnologies" 637 "Bavaria Yachts" 641 "Diverse Yacht Services" 644 "Wema U.S.A dba KUS" 658 "Shenzhen Jiuzhou Himunication" 688 "Rockford" 699 "Harman International" 704 "JL Audio" 708 "Lars Thrane" 715 "Autonnic" 717 "Yacht Devices" 734 "REAP Systems" 735 "AEM Performance Electronics" 739 "LxNav" 741 "Littelfuse, Inc (formerly Carling Technologies)" 743 "DaeMyung" 744 "Woosung" 748 "ISOTTA IFRA srl" 773 "Clarion US" 776 "HMI Systems" 777 "Ocean Signal" 778 "Seakeeper" 781 "Poly Planar" 785 "Fischer Panda DE" 795 "Broyda Industries" 796 "Canadian Automotive" 797 "Tides Marine" 798 "Lumishore" 799 "Still Water Designs and Audio" 802 "BJ Technologies (Beneteau)" 803 "Gill Sensors" 811 "Blue Water Desalination" 815 "FLIR" 824 "Undheim Systems" 826 "Lewmar" 838 "TeamSurv" 844 "Fell Marine" 847 "Oceanvolt" 862 "Prospec" 868 "Data Panel" 890 "L3 Technologies" 894 "Rhodan Marine Systems" 896 "Nexfour Solutions" 905 "ASA Electronics" 909 "Marines Co (South Korea)" 911 "Nautic-on" 917 "Sentinel" 929 "JL Marine Systems" 930 "Ecotronix" 944 "Zontisa Marine" 951 "EXOR International" 962 "Timbolier Industries" 963 "TJC Micro" 968 "Cox Powertrain" 969 "Blue Seas" 981 "Kobelt Manufacturing" 992 "Blue Ocean IOT" 997 "Xenta Systems" 999 "Signal K" 1004 "Ultraflex" 1008 "Lintest SmartBoat" 1011 "Soundmax" 1020 "Team Italia Marine (Onyx Marine Automation s.r.l)" 1021 "Entratech" 1022 "ITC" 1029 "The Marine Guardian" 1047 "Sonic" 1051 "ProNav" 1053 "Vetus Maxwell INC." 1056 "Lithium Pros" 1059 "Boatrax" 1062 "Marol Co ltd" 1065 "CALYPSO Instruments" 1066 "Spot Zero Water" 1069 "Lithionics Battery" 1070 "Quick-teck Electronics" 1075 "Uniden America" 1083 "Nauticoncept" 1084 "Shadow-Caster LED lighting" 1085 "Wet Sounds" 1088 "E-T-A Circuit Breakers" 1092 "Scheiber" 1100 "Smart Yachts International Limited" 1109 "Dockmate" 1114 "Bobs Machine" 1118 "L3Harris ASV" 1119 "Balmar" 1120 "Elettromedia" 1127 "Electromaax" 1140 "Across Oceans Systems" 1145 "Kiwi Yachting" 1150 "BSB Artificial Intelligence" 1151 "Orca Technologies" 1154 "TBS Electronics" 1158 "Technoton Electroics" 1160 "MG Energy Systems" 1169 "Sea Machine Robotics" 1171 "Vista Manufacturing" 1183 "Zipwake" 1186 "Sailmon" 1192 "Airmoniq Pro Kft" 1194 "Sierra Marine" 1200 "Xinuo Information Technology (Xiamen)" 1218 "Septentrio" 1233 "NKE Marine Electronics" 1238 "SuperTrack Aps" 1239 "Honda Electronics" 1245 "Raritan Engineering" 1249 "Integrated Power Solutions AG" 1260 "Interactive Technologies" 1283 "LTG-Tech" 1299 "Energy Solutions (UK)" 1300 "WATT Fuel Cell" 1302 "Pro Mainer" 1305 "Dragonfly Energy" 1306 "Koden Electronics" 1311 "Humphree" 1316 "Hinkley Yachts" 1317 "Global Marine Management GmbH (GMM)" 1320 "Triskel Marine" 1330 "Warwick Control Technologies" 1331 "Dolphin Charger" 1337 "Barnacle Systems" 1348 "Radian IoT" 1353 "Ocean LED Marine" 1359 "BluNav" 1361 "OVA (Nantong Saiyang Electronics Co., Ltd)" 1368 "RAD Propulsion" 1369 "Electric Yacht" 1372 "Elco Motor Yachts" 1384 "Tecnoseal Foundry S.r.l" 1385 "Pro Charging Systems" 1389 "EVEX" 1398 "Gobius Sensor Technology" 1403 "Arco Marine" 1408 "Lenco Marine" 1413 "Naocontrol" 1417 "Revatek" 1438 "Aeolionics" 1439 "PredictWind" 1440 "Egis Mobile Electric" 1445 "Starboard Yacht Group" 1446 "Roswell Marine" 1451 "ePropulsion (Guangdong ePropulsion Technology Ltd.)" 1452 "Micro-Air" 1453 "Vital Battery" 1458 "Ride Controller" 1460 "Tocaro Blue" 1461 "Vanquish Yachts" 1471 "FT Technologies" 1478 "Alps Alpine" 1481 "E-Force Marine" 1482 "CMC Marine" 1483 "Nanjing Sandemarine Information Technology" 1850 "Teleflex Marine (SeaStar Solutions)" 1851 "Raymarine" 1852 "Navionics" 1853 "Japan Radio" 1854 "Northstar Technologies" 1855 "Furuno" 1856 "Trimble" 1857 "Simrad" 1858 "Litton" 1859 "Kvasar" 1860 "MMP" 1861 "Vector Cantech" 1862 "Yamaha Marine" 1863 "Faria Instruments" ;
VAL_ 2566854912 Industry_Code 0 "Global" 1 "Highway" 2 "Agriculture" 3 "Construction" 4 "Marine Industry" 5 "Industrial" ;
VAL_ 2566854912 Model 0 "AC" 1 "Other device" 100 "NAC" ;
VAL_ 2566854912 Report 2 "Status" 3 "Send Status" 10 "Mode" 11 "Send Mode" 23 "Sailing Processor Status" ;
VAL_ 2566854912 Manufacturer_Code 69 "ARKS Enterprises" 78 "FW Murphy/Enovation Controls" 80 "Twin Disc" 85 "Kohler Power Systems" 88 "Hemisphere GPS" 135 "Airmar" 137 "Maretron" 140 "Lowrance" 144 "Mercury Marine" 147 "Nautibus Electronic" 148 "Blue Water Data" 154 "Westerbeke" 157 "ISSPRO" 161 "Offshore Systems (UK)" 163 "Evinrude/BRP" 165 "CPAC Systems" 168 "Xantrex Technology" 169 "Marlin Technologies" 172 "Yanmar Marine" 174 "Volvo Penta" 176 "Carling Technologies Inc. (Moritz Aerospace)" 185 "Beede Instruments" 192 "Floscan Instrument" 193 "Nobeltec" 198 "Mystic Valley Communications" 199 "Actia" 201 "Disenos Y Technologia" 211 "Digital Switching Systems" 215 "Xintex/Atena" 224 "EMMI NETWORK" 228 "ZF" 229 "Garmin" 233 "Yacht Monitoring Solutions" 235 "Sailormade Marine Telemetry/Tetra Technology" 243 "Eride" 257 "Honda Motor" 272 "Groco" 273 "Actisense" 274 "Amphenol LTW Technology" 275 "Navico" 283 "Hamilton Jet" 285 "Sea Recovery" 286 "Coelmo SRL Italy" 295 "BEP Marine" 304 "Empir Bus" 305 "NovAtel" 306 "Sleipner Motor" 307 "MBW Technologies" 315 "ICOM" 328 "Qwerty" 329 "Dief" 341 "Boening Automationstechnologie" 345 "Korean Maritime University" 351 "Thrane and Thrane" 355 "Mastervolt" 356 "Fischer Panda Generators" 358 "Victron Energy" 370 "Rolls Royce Marine" 373 "Electronic Design" 374 "Northern Lights" 378 "Glendinning" 381 "B & G" 384 "Rose Point Navigation Systems" 385 "Johnson Outdoors Marine Electronics Inc Geonav" 394 "Capi 2" 396 "Beyond Measure" 400 "Livorsi Marine" 404 "ComNav" 409 "Chetco" 419 "Fusion Electronics" 421 "Standard Horizon" 422 "True Heading" 426 "Egersund Marine Electronics" 427 "em-trak Marine Electronics" 431 "Tohatsu Co, JP" 437 "Digital Yacht" 438 "Comar Systems Limited" 440 "Cummins" 443 "VDO (aka Continental-Corporation)" 451 "Parker Hannifin aka Village Marine Tech" 459 "Alltek Marine Electronics" 460 "SAN GIORGIO S.E.I.N" 466 "Veethree Electronics & Marine" 470 "SI-TEX Marine Electronics" 471 "Sea Cross Marine" 475 "GME aka Standard Communications" 476 "Humminbird Marine Electronics" 478 "Ocean Sat" 481 "Chetco Digital Instruments" 493 "Watcheye" 499 "Lcj Capteurs" 502 "Attwood Marine" 503 "Naviop S.R.L." 504 "Vesper Marine" 510 "Marinesoft" 513 "Simarine" 517 "NoLand Engineering" 518 "Transas USA" 529 "National Instruments Korea" 530 "National Marine Electronics Association" 532 "Onwa Marine" 540 "Webasto" 571 "Marinecraft (South Korea)" 573 "McMurdo Group aka Orolia" 578 "Advansea" 579 "KVH" 580 "San Jose Technology" 583 "Yacht Control" 586 "Suzuki Motor" 591 "US Coast Guard" 595 "Ship Module aka Customware" 600 "Aquatic AV" 605 "Aventics" 606 "Intellian" 612 "SamwonIT" 614 "Arlt Tecnologies" 637 "Bavaria Yachts" 641 "Diverse Yacht Services" 644 "Wema U.S.A dba KUS" 658 "Shenzhen Jiuzhou Himunication" 688 "Rockford" 699 "Harman International" 704 "JL Audio" 708 "Lars Thrane" 715 "Autonnic" 717 "Yacht Devices" 734 "REAP Systems" 735 "AEM Performance Electronics" 739 "LxNav" 741 "Littelfuse, Inc (formerly Carling Technologies)" 743 "DaeMyung" 744 "Woosung" 748 "ISOTTA IFRA srl" 773 "Clarion US" 776 "HMI Systems" 777 "Ocean Signal" 778 "Seakeeper" 781 "Poly Planar" 785 "Fischer Panda DE" 795 "Broyda Industries" 796 "Canadian Automotive" 797 "Tides Marine" 798 "Lumishore" 799 "Still Water Designs and Audio" 802 "BJ Technologies (Beneteau)" 803 "Gill Sensors" 811 "Blue Water Desalination" 815 "FLIR" 824 "Undheim Systems" 826 "Lewmar" 838 "TeamSurv" 844 "Fell Marine" 847 "Oceanvolt" 862 "Prospec" 868 "Data Panel" 890 "L3 Technologies" 894 "Rhodan Marine Systems" 896 "Nexfour Solutions" 905 "ASA Electronics" 909 "Marines Co (South Korea)" 911 "Nautic-on" 917 "Sentinel" 929 "JL Marine Systems" 930 "Ecotronix" 944 "Zontisa Marine" 951 "EXOR International" 962 "Timbolier Industries" 963 "TJC Micro" 968 "Cox Powertrain" 969 "Blue Seas" 981 "Kobelt Manufacturing" 992 "Blue Ocean IOT" 997 "Xenta Systems" 999 "Signal K" 1004 "Ultraflex" 1008 "Lintest SmartBoat" 1011 "Soundmax" 1020 "Team Italia Marine (Onyx Marine Automation s.r.l)" 1021 "Entratech" 1022 "ITC" 1029 "The Marine Guardian" 1047 "Sonic" 1051 "ProNav" 1053 "Vetus Maxwell INC." 1056 "Lithium Pros" 1059 "Boatrax" 1062 "Marol Co ltd" 1065 "CALYPSO Instruments" 1066 "Spot Zero Water" 1069 "Lithionics Battery" 1070 "Quick-teck Electronics" 1075 "Uniden America" 1083 "Nauticoncept" 1084 "Shadow-Caster LED lighting" 1085 "Wet Sounds" 1088 "E-T-A Circuit Breakers" 1092 "Scheiber" 1100 "Smart Yachts International Limited" 1109 "Dockmate" 1114 "Bobs Machine" 1118 "L3Harris ASV" 1119 "Balmar" 1120 "Elettromedia" 1127 "Electromaax" 1140 "Across Oceans Systems" 1145 "Kiwi Yachting" 1150 "BSB Artificial Intelligence" 1151 "Orca Technologies" 1154 "TBS Electronics" 1158 "Technoton Electroics" 1160 "MG Energy Systems" 1169 "Sea Machine Robotics" 1171 "Vista Manufacturing" 1183 "Zipwake" 1186 "Sailmon" 1192 "Airmoniq Pro Kft" 1194 "Sierra Marine" 1200 "Xinuo Information Technology (Xiamen)" 1218 "Septentrio" 1233 "NKE Marine Electronics" 1238 "SuperTrack Aps" 1239 "Honda Electronics" 1245 "Raritan Engineering" 1249 "Integrated Power Solutions AG" 1260 "Interactive Technologies" 1283 "LTG-Tech" 1299 "Energy Solutions (UK)" 1300 "WATT Fuel Cell" 1302 "Pro Mainer" 1305 "Dragonfly Energy" 1306 "Koden Electronics" 1311 "Humphree" 1316 "Hinkley Yachts" 1317 "Global Marine Management GmbH (GMM)" 1320 "Triskel Marine" 1330 "Warwick Control Technologies" 1331 "Dolphin Charger" 1337 "Barnacle Systems" 1348 "Radian IoT" 1353 "Ocean LED Marine" 1359 "BluNav" 1361 "OVA (Nantong Saiyang Electronics Co., Ltd)" 1368 "RAD Propulsion" 1369 "Electric Yacht" 1372 "Elco Motor Yachts" 1384 "Tecnoseal Foundry S.r.l" 1385 "Pro Charging Systems" 1389 "EVEX" 1398 "Gobius Sensor Technology" 1403 "Arco Marine" 1408 "Lenco Marine" 1413 "Naocontrol" 1417 "Revatek" 1438 "Aeolionics" 1439 "PredictWind" 1440 "Egis Mobile Electric" 1445 "Starboard Yacht Group" 1446 "Roswell Marine" 1451 "ePropulsion (Guangdong ePropulsion Technology Ltd.)" 1452 "Micro-Air" 1453 "Vital Battery" 1458 "Ride Controller" 1460 "Tocaro Blue" 1461 "Vanquish Yachts" 1471 "FT Technologies" 1478 "Alps Alpine" 1481 "E-Force Marine" 1482 "CMC Marine" 1483 "Nanjing Sandemarine Information Technology" 1850 "Teleflex Marine (SeaStar Solutions)" 1851 "Raymarine" 1852 "Navionics" 1853 "Japan Radio" 1854 "Northstar Technologies" 1855 "Furuno" 1856 "Trimble" 1857 "Simrad" 1858 "Litton" 1859 "Kvasar" 1860 "MMP" 1861 "Vector Cantech" 1862 "Yamaha Marine" 1863 "Faria Instruments" ;
VAL_ 2566854912 Industry_Code 0 "Global" 1 "Highway" 2 "Agriculture" 3 "Construction" 4 "Marine Industry" 5 "Industrial" ;
VAL_ 2566854912 Model 0 "AC" 1 "Other device" 100 "NAC" ;
VAL_ 2566854912 Report 2 "Status" 3 "Send Status" 10 "Mode" 11 "Send Mode" 23 "Sailing Processor Status" ;
VAL_ 2566854912 Status 2 "Manual" 16 "Automatic" ;
VAL_ 2566854912 Manufacturer_Code 69 "ARKS Enterprises" 78 "FW Murphy/Enovation Controls" 80 "Twin Disc" 85 "Kohler Power Systems" 88 "Hemisphere GPS" 135 "Airmar" 137 "Maretron" 140 "Lowrance" 144 "Mercury Marine" 147 "Nautibus Electronic" 148 "Blue Water Data" 154 "Westerbeke" 157 "ISSPRO" 161 "Offshore Systems (UK)" 163 "Evinrude/BRP" 165 "CPAC Systems" 168 "Xantrex Technology" 169 "Marlin Technologies" 172 "Yanmar Marine" 174 "Volvo Penta" 176 "Carling Technologies Inc. (Moritz Aerospace)" 185 "Beede Instruments" 192 "Floscan Instrument" 193 "Nobeltec" 198 "Mystic Valley Communications" 199 "Actia" 201 "Disenos Y Technologia" 211 "Digital Switching Systems" 215 "Xintex/Atena" 224 "EMMI NETWORK" 228 "ZF" 229 "Garmin" 233 "Yacht Monitoring Solutions" 235 "Sailormade Marine Telemetry/Tetra Technology" 243 "Eride" 257 "Honda Motor" 272 "Groco" 273 "Actisense" 274 "Amphenol LTW Technology" 275 "Navico" 283 "Hamilton Jet" 285 "Sea Recovery" 286 "Coelmo SRL Italy" 295 "BEP Marine" 304 "Empir Bus" 305 "NovAtel" 306 "Sleipner Motor" 307 "MBW Technologies" 315 "ICOM" 328 "Qwerty" 329 "Dief" 341 "Boening Automationstechnologie" 345 "Korean Maritime University" 351 "Thrane and Thrane" 355 "Mastervolt" 356 "Fischer Panda Generators" 358 "Victron Energy" 370 "Rolls Royce Marine" 373 "Electronic Design" 374 "Northern Lights" 378 "Glendinning" 381 "B & G" 384 "Rose Point Navigation Systems" 385 "Johnson Outdoors Marine Electronics Inc Geonav" 394 "Capi 2" 396 "Beyond Measure" 400 "Livorsi Marine" 404 "ComNav" 409 "Chetco" 419 "Fusion Electronics" 421 "Standard Horizon" 422 "True Heading" 426 "Egersund Marine Electronics" 427 "em-trak Marine Electronics" 431 "Tohatsu Co, JP" 437 "Digital Yacht" 438 "Comar Systems Limited" 440 "Cummins" 443 "VDO (aka Continental-Corporation)" 451 "Parker Hannifin aka Village Marine Tech" 459 "Alltek Marine Electronics" 460 "SAN GIORGIO S.E.I.N" 466 "Veethree Electronics & Marine" 470 "SI-TEX Marine Electronics" 471 "Sea Cross Marine" 475 "GME aka Standard Communications" 476 "Humminbird Marine Electronics" 478 "Ocean Sat" 481 "Chetco Digital Instruments" 493 "Watcheye" 499 "Lcj Capteurs" 502 "Attwood Marine" 503 "Naviop S.R.L." 504 "Vesper Marine" 510 "Marinesoft" 513 "Simarine" 517 "NoLand Engineering" 518 "Transas USA" 529 "National Instruments Korea" 530 "National Marine Electronics Association" 532 "Onwa Marine" 540 "Webasto" 571 "Marinecraft (South Korea)" 573 "McMurdo Group aka Orolia" 578 "Advansea" 579 "KVH" 580 "San Jose Technology" 583 "Yacht Control" 586 "Suzuki Motor" 591 "US Coast Guard" 595 "Ship Module aka Customware" 600 "Aquatic AV" 605 "Aventics" 606 "Intellian" 612 "SamwonIT" 614 "Arlt Tecnologies" 637 "Bavaria Yachts" 641 "Diverse Yacht Services" 644 "Wema U.S.A dba KUS" 658 "Shenzhen Jiuzhou Himunication" 688 "Rockford" 699 "Harman International" 704 "JL Audio" 708 "Lars Thrane" 715 "Autonnic" 717 "Yacht Devices" 734 "REAP Systems" 735 "AEM Performance Electronics" 739 "LxNav" 741 "Littelfuse, Inc (formerly Carling Technologies)" 743 "DaeMyung" 744 "Woosung" 748 "ISOTTA IFRA srl" 773 "Clarion US" 776 "HMI Systems" 777 "Ocean Signal" 778 "Seakeeper" 781 "Poly Planar" 785 "Fischer Panda DE" 795 "Broyda Industries" 796 "Canadian Automotive" 797 "Tides Marine" 798 "Lumishore" 799 "Still Water Designs and Audio" 802 "BJ Technologies (Beneteau)" 803 "Gill Sensors" 811 "Blue Water Desalination" 815 "FLIR" 824 "Undheim Systems" 826 "Lewmar" 838 "TeamSurv" 844 "Fell Marine" 847 "Oceanvolt" 862 "Prospec" 868 "Data Panel" 890 "L3 Technologies" 894 "Rhodan Marine Systems" 896 "Nexfour Solutions" 905 "ASA Electronics" 909 "Marines Co (South Korea)" 911 "Nautic-on" 917 "Sentinel" 929 "JL Marine Systems" 930 "Ecotronix" 944 "Zontisa Marine" 951 "EXOR International" 962 "Timbolier Industries" 963 "TJC Micro" 968 "Cox Powertrain" 969 "Blue Seas" 981 "Kobelt Manufacturing" 992 "Blue Ocean IOT" 997 "Xenta Systems" 999 "Signal K" 1004 "Ultraflex" 1008 "Lintest SmartBoat" 1011 "Soundmax" 1020 "Team Italia Marine (Onyx Marine Automation s.r.l)" 1021 "Entratech" 1022 "ITC" 1029 "The Marine Guardian" 1047 "Sonic" 1051 "ProNav" 1053 "Vetus Maxwell INC." 1056 "Lithium Pros" 1059 "Boatrax" 1062 "Marol Co ltd" 1065 "CALYPSO Instruments" 1066 "Spot Zero Water" 1069 "Lithionics Battery" 1070 "Quick-teck Electronics" 1075 "Uniden America" 1083 "Nauticoncept" 1084 "Shadow-Caster LED lighting" 1085 "Wet Sounds" 1088 "E-T-A Circuit Breakers" 1092 "Scheiber" 1100 "Smart Yachts International Limited" 1109 "Dockmate" 1114 "Bobs Machine" 1118 "L3Harris ASV" 1119 "Balmar" 1120 "Elettromedia" 1127 "Electromaax" 1140 "Across Oceans Systems" 1145 "Kiwi Yachting" 1150 "BSB Artificial Intelligence" 1151 "Orca Technologies" 1154 "TBS Electronics" 1158 "Technoton Electroics" 1160 "MG Energy Systems" 1169 "Sea Machine Robotics" 1171 "Vista Manufacturing" 1183 "Zipwake" 1186 "Sailmon" 1192 "Airmoniq Pro Kft" 1194 "Sierra Marine" 1200 "Xinuo Information Technology (Xiamen)" 1218 "Septentrio" 1233 "NKE Marine Electronics" 1238 "SuperTrack Aps" 1239 "Honda Electronics" 1245 "Raritan Engineering" 1249 "Integrated Power Solutions AG" 1260 "Interactive Technologies" 1283 "LTG-Tech" 1299 "Energy Solutions (UK)" 1300 "WATT Fuel Cell" 1302 "Pro Mainer" 1305 "Dragonfly Energy" 1306 "Koden Electronics" 1311 "Humphree" 1316 "Hinkley Yachts" 1317 "Global Marine Management GmbH (GMM)" 1320 "Triskel Marine" 1330 "Warwick Control Technologies" 1331 "Dolphin Charger" 1337 "Barnacle Systems" 1348 "Radian IoT" 1353 "Ocean LED Marine" 1359 "BluNav" 1361 "OVA (Nantong Saiyang Electronics Co., Ltd)" 1368 "RAD Propulsion" 1369 "Electric Yacht" 1372 "Elco Motor Yachts" 1384 "Tecnoseal Foundry S.r.l" 1385 "Pro Charging Systems" 1389 "EVEX" 1398 "Gobius Sensor Technology" 1403 "Arco Marine" 1408 "Lenco Marine" 1413 "Naocontrol" 1417 "Revatek" 1438 "Aeolionics" 1439 "PredictWind" 1440 "Egis Mobile Electric" 1445 "Starboard Yacht Group" 1446 "Roswell Marine" 1451 "ePropulsion (Guangdong ePropulsion Technology Ltd.)" 1452 "Micro-Air" 1453 "Vital Battery" 1458 "Ride Controller" 1460 "Tocaro Blue" 1461 "Vanquish Yachts" 1471 "FT Technologies" 1478 "Alps Alpine" 1481 "E-Force Marine" 1482 "CMC Marine" 1483 "Nanjing Sandemarine Information Technology" 1850 "Teleflex Marine (SeaStar Solutions)" 1851 "Raymarine" 1852 "Navionics" 1853 "Japan Radio" 1854 "Northstar Technologies" 1855 "Furuno" 1856 "Trimble" 1857 "Simrad" 1858 "Litton" 1859 "Kvasar" 1860 "MMP" 1861 "Vector Cantech" 1862 "Yamaha Marine" 1863 "Faria Instruments" ;
VAL_ 2566854912 Industry_Code 0 "Global" 1 "Highway" 2 "Agriculture" 3 "Construction" 4 "Marine Industry" 5 "Industrial" ;
VAL_ 2566854912 Model 0 "AC" 1 "Other device" 100 "NAC" ;
VAL_ 2566854912 Report 2 "Status" 3 "Send Status" 10 "Mode" 11 "Send Mode" 23 "Sailing Processor Status" ;
VAL_ 2566854912 Manufacturer_Code 69 "ARKS Enterprises" 78 "FW Murphy/Enovation Controls" 80 "Twin Disc" 85 "Kohler Power Systems" 88 "Hemisphere GPS" 135 "Airmar" 137 "Maretron" 140 "Lowrance" 144 "Mercury Marine" 147 "Nautibus Electronic" 148 "Blue Water Data" 154 "Westerbeke" 157 "ISSPRO" 161 "Offshore Systems (UK)" 163 "Evinrude/BRP" 165 "CPAC Systems" 168 "Xantrex Technology" 169 "Marlin Technologies" 172 "Yanmar Marine" 174 "Volvo Penta" 176 "Carling Technologies Inc. (Moritz Aerospace)" 185 "Beede Instruments" 192 "Floscan Instrument" 193 "Nobeltec" 198 "Mystic Valley Communications" 199 "Actia" 201 "Disenos Y Technologia" 211 "Digital Switching Systems" 215 "Xintex/Atena" 224 "EMMI NETWORK" 228 "ZF" 229 "Garmin" 233 "Yacht Monitoring Solutions" 235 "Sailormade Marine Telemetry/Tetra Technology" 243 "Eride" 257 "Honda Motor" 272 "Groco" 273 "Actisense" 274 "Amphenol LTW Technology" 275 "Navico" 283 "Hamilton Jet" 285 "Sea Recovery" 286 "Coelmo SRL Italy" 295 "BEP Marine" 304 "Empir Bus" 305 "NovAtel" 306 "Sleipner Motor" 307 "MBW Technologies" 315 "ICOM" 328 "Qwerty" 329 "Dief" 341 "Boening Automationstechnologie" 345 "Korean Maritime University" 351 "Thrane and Thrane" 355 "Mastervolt" 356 "Fischer Panda Generators" 358 "Victron Energy" 370 "Rolls Royce Marine" 373 "Electronic Design" 374 "Northern Lights" 378 "Glendinning" 381 "B & G" 384 "Rose Point Navigation Systems" 385 "Johnson Outdoors Marine Electronics Inc Geonav" 394 "Capi 2" 396 "Beyond Measure" 400 "Livorsi Marine" 404 "ComNav" 409 "Chetco" 419 "Fusion Electronics" 421 "Standard Horizon" 422 "True Heading" 426 "Egersund Marine Electronics" 427 "em-trak Marine Electronics" 431 "Tohatsu Co, JP" 437 "Digital Yacht" 438 "Comar Systems Limited" 440 "Cummins" 443 "VDO (aka Continental-Corporation)" 451 "Parker Hannifin aka Village Marine Tech" 459 "Alltek Marine Electronics" 460 "SAN GIORGIO S.E.I.N" 466 "Veethree Electronics & Marine" 470 "SI-TEX Marine Electronics" 471 "Sea Cross Marine" 475 "GME aka Standard Communications" 476 "Humminbird Marine Electronics" 478 "Ocean Sat" 481 "Chetco Digital Instruments" 493 "Watcheye" 499 "Lcj Capteurs" 502 "Attwood Marine" 503 "Naviop S.R.L." 504 "Vesper Marine" 510 "Marinesoft" 513 "Simarine" 517 "NoLand Engineering" 518 "Transas USA" 529 "National Instruments Korea" 530 "National Marine Electronics Association" 532 "Onwa Marine" 540 "Webasto" 571 "Marinecraft (South Korea)" 573 "McMurdo Group aka Orolia" 578 "Advansea" 579 "KVH" 580 "San Jose Technology" 583 "Yacht Control" 586 "Suzuki Motor" 591 "US Coast Guard" 595 "Ship Module aka Customware" 600 "Aquatic AV" 605 "Aventics" 606 "Intellian" 612 "SamwonIT" 614 "Arlt Tecnologies" 637 "Bavaria Yachts" 641 "Diverse Yacht Services" 644 "Wema U.S.A dba KUS" 658 "Shenzhen Jiuzhou Himunication" 688 "Rockford" 699 "Harman International" 704 "JL Audio" 708 "Lars Thrane" 715 "Autonnic" 717 "Yacht Devices" 734 "REAP Systems" 735 "AEM Performance Electronics" 739 "LxNav" 741 "Littelfuse, Inc (formerly Carling Technologies)" 743 "DaeMyung" 744 "Woosung" 748 "ISOTTA IFRA srl" 773 "Clarion US" 776 "HMI Systems" 777 "Ocean Signal" 778 "Seakeeper" 781 "Poly Planar" 785 "Fischer Panda DE" 795 "Broyda Industries" 796 "Canadian Automotive" 797 "Tides Marine" 798 "Lumishore" 799 "Still Water Designs and Audio" 802 "BJ Technologies (Beneteau)" 803 "Gill Sensors" 811 "Blue Water Desalination" 815 "FLIR" 824 "Undheim Systems" 826 "Lewmar" 838 "TeamSurv" 844 "Fell Marine" 847 "Oceanvolt" 862 "Prospec" 868 "Data Panel" 890 "L3 Technologies" 894 "Rhodan Marine Systems" 896 "Nexfour Solutions" 905 "ASA Electronics" 909 "Marines Co (South Korea)" 911 "Nautic-on" 917 "Sentinel" 929 "JL Marine Systems" 930 "Ecotronix" 944 "Zontisa Marine" 951 "EXOR International" 962 "Timbolier Industries" 963 "TJC Micro" 968 "Cox Powertrain" 969 "Blue Seas" 981 "Kobelt Manufacturing" 992 "Blue Ocean IOT" 997 "Xenta Systems" 999 "Signal K" 1004 "Ultraflex" 1008 "Lintest SmartBoat" 1011 "Soundmax" 1020 "Team Italia Marine (Onyx Marine Automation s.r.l)" 1021 "Entratech" 1022 "ITC" 1029 "The Marine Guardian" 1047 "Sonic" 1051 "ProNav" 1053 "Vetus Maxwell INC." 1056 "Lithium Pros" 1059 "Boatrax" 1062 "Marol Co ltd" 1065 "CALYPSO Instruments" 1066 "Spot Zero Water" 1069 "Lithionics Battery" 1070 "Quick-teck Electronics" 1075 "Uniden America" 1083 "Nauticoncept" 1084 "Shadow-Caster LED lighting" 1085 "Wet Sounds" 1088 "E-T-A Circuit Breakers" 1092 "Scheiber" 1100 "Smart Yachts International Limited" 1109 "Dockmate" 1114 "Bobs Machine" 1118 "L3Harris ASV" 1119 "Balmar" 1120 "Elettromedia" 1127 "Electromaax" 1140 "Across Oceans Systems" 1145 "Kiwi Yachting" 1150 "BSB Artificial Intelligence" 1151 "Orca Technologies" 1154 "TBS Electronics" 1158 "Technoton Electroics" 1160 "MG Energy Systems" 1169 "Sea Machine Robotics" 1171 "Vista Manufacturing" 1183 "Zipwake" 1186 "Sailmon" 1192 "Airmoniq Pro Kft" 1194 "Sierra Marine" 1200 "Xinuo Information Technology (Xiamen)" 1218 "Septentrio" 1233 "NKE Marine Electronics" 1238 "SuperTrack Aps" 1239 "Honda Electronics" 1245 "Raritan Engineering" 1249 "Integrated Power Solutions AG" 1260 "Interactive Technologies" 1283 "LTG-Tech" 1299 "Energy Solutions (UK)" 1300 "WATT Fuel Cell" 1302 "Pro Mainer" 1305 "Dragonfly Energy" 1306 "Koden Electronics" 1311 "Humphree" 1316 "Hinkley Yachts" 1317 "Global Marine Management GmbH (GMM)" 1320 "Triskel Marine" 1330 "Warwick Control Technologies" 1331 "Dolphin Charger" 1337 "Barnacle Systems" 1348 "Radian IoT" 1353 "Ocean LED Marine" 1359 "BluNav" 1361 "OVA (Nantong Saiyang Electronics Co., Ltd)" 1368 "RAD Propulsion" 1369 "Electric Yacht" 1372 "Elco Motor Yachts" 1384 "Tecnoseal Foundry S.r.l" 1385 "Pro Charging Systems" 1389 "EVEX" 1398 "Gobius Sensor Technology" 1403 "Arco Marine" 1408 "Lenco Marine" 1413 "Naocontrol" 1417 "Revatek" 1438 "Aeolionics" 1439 "PredictWind" 1440 "Egis Mobile Electric" 1445 "Starboard Yacht Group" 1446 "Roswell Marine" 1451 "ePropulsion (Guangdong ePropulsion Technology Ltd.)" 1452 "Micro-Air" 1453 "Vital Battery" 1458 "Ride Controller" 1460 "Tocaro Blue" 1461 "Vanquish Yachts" 1471 "FT Technologies" 1478 "Alps Alpine" 1481 "E-Force Marine" 1482 "CMC Marine" 1483 "Nanjing Sandemarine Information Technology" 1850 "Teleflex Marine (SeaStar Solutions)" 1851 "Raymarine" 1852 "Navionics" 1853 "Japan Radio" 1854 "Northstar Technologies" 1855 "Furuno" 1856 "Trimble" 1857 "Simrad" 1858 "Litton" 1859 "Kvasar" 1860 "MMP" 1861 "Vector Cantech" 1862 "Yamaha Marine" 1863 "Faria Instruments" ;
VAL_ 2566854912 Industry_Code 0 "Global" 1 "Highway" 2 "Agriculture" 3 "Construction" 4 "Marine Industry" 5 "Industrial" ;
VAL_ 2566854912 Model 0 "AC" 1 "Other device" 100 "NAC" ;
VAL_ 2566854912 Report 2 "Status" 3 "Send Status" 10 "Mode" 11 "Send Mode" 23 "Sailing Processor Status" ;
VAL_ 2566854912 Manufacturer_Code 69 "ARKS Enterprises" 78 "FW Murphy/Enovation Controls" 80 "Twin Disc" 85 "Kohler Power Systems" 88 "Hemisphere GPS" 135 "Airmar" 137 "Maretron" 140 "Lowrance" 144 "Mercury Marine" 147 "Nautibus Electronic" 148 "Blue Water Data" 154 "Westerbeke" 157 "ISSPRO" 161 "Offshore Systems (UK)" 163 "Evinrude/BRP" 165 "CPAC Systems" 168 "Xantrex Technology" 169 "Marlin Technologies" 172 "Yanmar Marine" 174 "Volvo Penta" 176 "Carling Technologies Inc. (Moritz Aerospace)" 185 "Beede Instruments" 192 "Floscan Instrument" 193 "Nobeltec" 198 "Mystic Valley Communications" 199 "Actia" 201 "Disenos Y Technologia" 211 "Digital Switching Systems" 215 "Xintex/Atena" 224 "EMMI NETWORK" 228 "ZF" 229 "Garmin" 233 "Yacht Monitoring Solutions" 235 "Sailormade Marine Telemetry/Tetra Technology" 243 "Eride" 257 "Honda Motor" 272 "Groco" 273 "Actisense" 274 "Amphenol LTW Technology" 275 "Navico" 283 "Hamilton Jet" 285 "Sea Recovery" 286 "Coelmo SRL Italy" 295 "BEP Marine" 304 "Empir Bus" 305 "NovAtel" 306 "Sleipner Motor" 307 "MBW Technologies" 315 "ICOM" 328 "Qwerty" 329 "Dief" 341 "Boening Automationstechnologie" 345 "Korean Maritime University" 351 "Thrane and Thrane" 355 "Mastervolt" 356 "Fischer Panda Generators" 358 "Victron Energy" 370 "Rolls Royce Marine" 373 "Electronic Design" 374 "Northern Lights" 378 "Glendinning" 381 "B & G" 384 "Rose Point Navigation Systems" 385 "Johnson Outdoors Marine Electronics Inc Geonav" 394 "Capi 2" 396 "Beyond Measure" 400 "Livorsi Marine" 404 "ComNav" 409 "Chetco" 419 "Fusion Electronics" 421 "Standard Horizon" 422 "True Heading" 426 "Egersund Marine Electronics" 427 "em-trak Marine Electronics" 431 "Tohatsu Co, JP" 437 "Digital Yacht" 438 "Comar Systems Limited" 440 "Cummins" 443 "VDO (aka Continental-Corporation)" 451 "Parker Hannifin aka Village Marine Tech" 459 "Alltek Marine Electronics" 460 "SAN GIORGIO S.E.I.N" 466 "Veethree Electronics & Marine" 470 "SI-TEX Marine Electronics" 471 "Sea Cross Marine" 475 "GME aka Standard Communications" 476 "Humminbird Marine Electronics" 478 "Ocean Sat" 481 "Chetco Digital Instruments" 493 "Watcheye" 499 "Lcj Capteurs" 502 "Attwood Marine" 503 "Naviop S.R.L." 504 "Vesper Marine" 510 "Marinesoft" 513 "Simarine" 517 "NoLand Engineering" 518 "Transas USA" 529 "National Instruments Korea" 530 "National Marine Electronics Association" 532 "Onwa Marine" 540 "Webasto" 571 "Marinecraft (South Korea)" 573 "McMurdo Group aka Orolia" 578 "Advansea" 579 "KVH" 580 "San Jose Technology" 583 "Yacht Control" 586 "Suzuki Motor" 591 "US Coast Guard" 595 "Ship Module aka Customware" 600 "Aquatic AV" 605 "Aventics" 606 "Intellian" 612 "SamwonIT" 614 "Arlt Tecnologies" 637 "Bavaria Yachts" 641 "Diverse Yacht Services" 644 "Wema U.S.A dba KUS" 658 "Shenzhen Jiuzhou Himunication" 688 "Rockford" 699 "Harman International" 704 "JL Audio" 708 "Lars Thrane" 715 "Autonnic" 717 "Yacht Devices" 734 "REAP Systems" 735 "AEM Performance Electronics" 739 "LxNav" 741 "Littelfuse, Inc (formerly Carling Technologies)" 743 "DaeMyung" 744 "Woosung" 748 "ISOTTA IFRA srl" 773 "Clarion US" 776 "HMI Systems" 777 "Ocean Signal" 778 "Seakeeper" 781 "Poly Planar" 785 "Fischer Panda DE" 795 "Broyda Industries" 796 "Canadian Automotive" 797 "Tides Marine" 798 "Lumishore" 799 "Still Water Designs and Audio" 802 "BJ Technologies (Beneteau)" 803 "Gill Sensors" 811 "Blue Water Desalination" 815 "FLIR" 824 "Undheim Systems" 826 "Lewmar" 838 "TeamSurv" 844 "Fell Marine" 847 "Oceanvolt" 862 "Prospec" 868 "Data Panel" 890 "L3 Technologies" 894 "Rhodan Marine Systems" 896 "Nexfour Solutions" 905 "ASA Electronics" 909 "Marines Co (South Korea)" 911 "Nautic-on" 917 "Sentinel" 929 "JL Marine Systems" 930 "Ecotronix" 944 "Zontisa Marine" 951 "EXOR International" 962 "Timbolier Industries" 963 "TJC Micro" 968 "Cox Powertrain" 969 "Blue Seas" 981 "Kobelt Manufacturing" 992 "Blue Ocean IOT" 997 "Xenta Systems" 999 "Signal K" 1004 "Ultraflex" 1008 "Lintest SmartBoat" 1011 "Soundmax" 1020 "Team Italia Marine (Onyx Marine Automation s.r.l)" 1021 "Entratech" 1022 "ITC" 1029 "The Marine Guardian" 1047 "Sonic" 1051 "ProNav" 1053 "Vetus Maxwell INC." 1056 "Lithium Pros" 1059 "Boatrax" 1062 "Marol Co ltd" 1065 "CALYPSO Instruments" 1066 "Spot Zero Water" 1069 "Lithionics Battery" 1070 "Quick-teck Electronics" 1075 "Uniden America" 1083 "Nauticoncept" 1084 "Shadow-Caster LED lighting" 1085 "Wet Sounds" 1088 "E-T-A Circuit Breakers" 1092 "Scheiber" 1100 "Smart Yachts International Limited" 1109 "Dockmate" 1114 "Bobs Machine" 1118 "L3Harris ASV" 1119 "Balmar" 1120 "Elettromedia" 1127 "Electromaax" 1140 "Across Oceans Systems" 1145 "Kiwi Yachting" 1150 "BSB Artificial Intelligence" 1151 "Orca Technologies" 1154 "TBS Electronics" 1158 "Technoton Electroics" 1160 "MG Energy Systems" 1169 "Sea Machine Robotics" 1171 "Vista Manufacturing" 1183 "Zipwake" 1186 "Sailmon" 1192 "Airmoniq Pro Kft" 1194 "Sierra Marine" 1200 "Xinuo Information Technology (Xiamen)" 1218 "Septentrio" 1233 "NKE Marine Electronics" 1238 "SuperTrack Aps" 1239 "Honda Electronics" 1245 "Raritan Engineering" 1249 "Integrated Power Solutions AG" 1260 "Interactive Technologies" 1283 "LTG-Tech" 1299 "Energy Solutions (UK)" 1300 "WATT Fuel Cell" 1302 "Pro Mainer" 1305 "Dragonfly Energy" 1306 "Koden Electronics" 1311 "Humphree" 1316 "Hinkley Yachts" 1317 "Global Marine Management GmbH (GMM)" 1320 "Triskel Marine" 1330 "Warwick Control Technologies" 1331 "Dolphin Charger" 1337 "Barnacle Systems" 1348 "Radian IoT" 1353 "Ocean LED Marine" 1359 "BluNav" 1361 "OVA (Nantong Saiyang Electronics Co., Ltd)" 1368 "RAD Propulsion" 1369 "Electric Yacht" 1372 "Elco Motor Yachts" 1384 "Tecnoseal Foundry S.r.l" 1385 "Pro Charging Systems" 1389 "EVEX" 1398 "Gobius Sensor Technology" 1403 "Arco Marine" 1408 "Lenco Marine" 1413 "Naocontrol" 1417 "Revatek" 1438 "Aeolionics" 1439 "PredictWind" 1440 "Egis Mobile Electric" 1445 "Starboard Yacht Group" 1446 "Roswell Marine" 1451 "ePropulsion (Guangdong ePropulsion Technology Ltd.)" 1452 "Micro-Air" 1453 "Vital Battery" 1458 "Ride Controller" 1460 "Tocaro Blue" 1461 "Vanquish Yachts" 1471 "FT Technologies" 1478 "Alps Alpine" 1481 "E-Force Marine" 1482 "CMC Marine" 1483 "Nanjing Sandemarine Information Technology" 1850 "Teleflex Marine (SeaStar Solutions)" 1851 "Raymarine" 1852 "Navionics" 1853 "Japan Radio" 1854 "Northstar Technologies" 1855 "Furuno" 1856 "Trimble" 1857 "Simrad" 1858 "Litton" 1859 "Kvasar" 1860 "MMP" 1861 "Vector Cantech" 1862 "Yamaha Marine" 1863 "Faria Instruments" ;
VAL_ 2566854912 Industry_Code 0 "Global" 1 "Highway" 2 "Agriculture" 3 "Construction" 4 "Marine Industry" 5 "Industrial" ;
VAL_ 2566854912 Model 0 "AC" 1 "Other device" 100 "NAC" ;
VAL_ 2566854912 Report 2 "Status" 3 "Send Status" 10 "Mode" 11 "Send Mode" 23 "Sailing Processor Status" ;

BA_DEF_ BO_ "GenMsgCycleTime" INT 0 60000;
BA_DEF_ BO_ "ProtocolType" STRING;

BA_DEF_ BO_ "J1939PGN" INT 0 262143;
BA_ "J1939PGN" BO_ 2566851840 65293;
BA_ "J1939PGN" BO_ 2566851840 65293;
BA_ "J1939PGN" BO_ 2566852096 65294;
BA_ "J1939PGN" BO_ 2566852352 65295;
BA_ "J1939PGN" BO_ 2566852608 65296;
BA_ "J1939PGN" BO_ 2566852864 65297;
BA_ "J1939PGN" BO_ 2566853120 65298;
BA_ "J1939PGN" BO_ 2566853376 65299;
BA_ "J1939PGN" BO_ 2566853376 65299;
BA_ "J1939PGN" BO_ 2566853632 65300;
BA_ "J1939PGN" BO_ 2566853632 65300;
BA_ "J1939PGN" BO_ 2566853632 65300;
BA_ "J1939PGN" BO_ 2566853888 65301;
BA_ "J1939PGN" BO_ 2633963008 65302;
BA_ "GenMsgCycleTime" BO_ 2633963008 1000;
BA_ "J1939PGN" BO_ 2566854400 65303;
BA_ "J1939PGN" BO_ 2566854400 65303;
BA_ "J1939PGN" BO_ 2566854656 65304;
BA_ "J1939PGN" BO_ 2566854656 65304;
BA_ "J1939PGN" BO_ 2566854656 65304;
BA_ "J1939PGN" BO_ 2566854656 65304;
BA_ "J1939PGN" BO_ 2566854912 65305;
BA_ "GenMsgCycleTime" BO_ 2566854912 1000;
BA_ "J1939PGN" BO_ 2566854912 65305;
BA_ "GenMsgCycleTime" BO_ 2566854912 1000;
BA_ "J1939PGN" BO_ 2566854912 65305;
BA_ "GenMsgCycleTime" BO_ 2566854912 1000;
BA_ "J1939PGN" BO_ 2566854912 65305;
BA_ "GenMsgCycleTime" BO_ 2566854912 1000;
BA_ "J1939PGN" BO_ 2566854912 65305;
BA_ "GenMsgCycleTime" BO_ 2566854912 1000;
